VERSION "FM29 IBUS1 + IBUS2, V390.1 20230120, generated by sunnypilot/webhud/tools/gen_ibus.py"

NS_ :

BS_:

BU_: ADAS AMP FloatingButtons GW ICC MFSS PWC_L PWC_R RAC Rotator

BO_ 54 TBOX_0x36: 8 GW
 SG_ TBOX_RemSeekCarCtrlCmd : 3|2@0+ (1,0) [0|3] "" ICC
 SG_ TBOX_RemClsTrCmd : 9|2@0+ (1,0) [0|3] "" ICC
 SG_ TBOX_RemDrvrSeatVentnCmd : 12|3@0+ (1,0) [0|7] "" ICC
 SG_ TBOX_RemDrvrSeatHeatgCmd : 15|3@0+ (1,0) [0|7] "" ICC
 SG_ TBOX_RemSetWelFct : 17|2@0+ (1,0) [0|3] "" ICC
 SG_ TBOX_RemPassSeatVentnCmd : 20|3@0+ (1,0) [0|7] "" ICC
 SG_ TBOX_RemPassSeatHeatgCmd : 23|3@0+ (1,0) [0|7] "" ICC
 SG_ TBOX_ClsAVMFct_ICC : 27|1@0+ (1,0) [0|1] "" ICC
 SG_ TBOX_ClsRemAVMFct_AVAP : 28|1@0+ (1,0) [0|1] "" ICC
 SG_ TBOX_RemSetFolwMeFct_BCM : 31|3@0+ (1,0) [0|7] "" ICC
 SG_ TBOX_RemSetCtrlLockFct_PKC : 33|2@0+ (1,0) [0|3] "" ICC
 SG_ TBOX_RemSetKickSnsrFct : 35|2@0+ (1,0) [0|3] "" ICC
 SG_ TBOX_VideoCtrlReq : 38|3@0+ (1,0) [0|7] "" ICC
 SG_ TBOX_VoiceBlowerLimReq : 39|1@0+ (1,0) [0|1] "" ICC
 SG_ TBOX_RemCtrlCmdFb : 41|2@0+ (1,0) [0|3] "" ICC
 SG_ TBOX_CtrlReMirrReq : 43|2@0+ (1,0) [0|3] "" ICC
 SG_ TBOX_eCallMuteSt : 45|2@0+ (1,0) [0|3] "" ICC
 SG_ TBOX_eCallSt : 58|3@0+ (1,0) [0|7] "" ICC

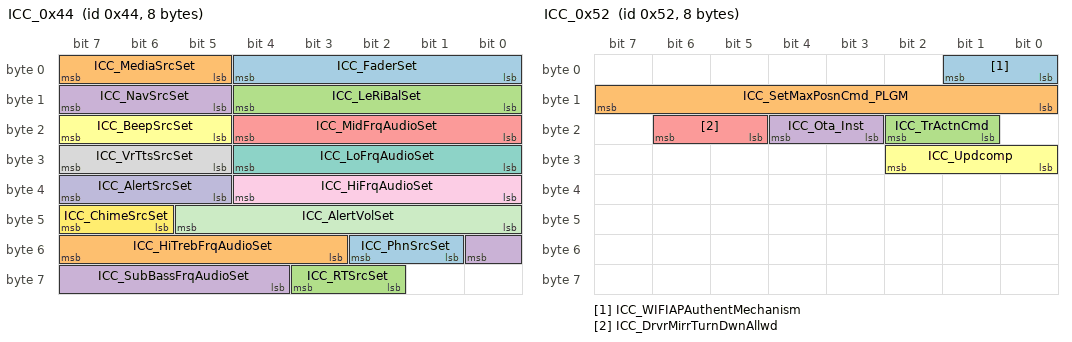
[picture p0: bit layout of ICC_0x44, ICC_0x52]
BO_ 68 ICC_0x44: 8 ICC
 SG_ ICC_FaderSet : 4|5@0+ (1,0) [0|31] "" ICC
 SG_ ICC_MediaSrcSet : 7|3@0+ (1,0) [0|7] "" ICC
 SG_ ICC_LeRiBalSet : 12|5@0+ (1,0) [0|31] "" ICC
 SG_ ICC_NavSrcSet : 15|3@0+ (1,0) [0|7] "" ICC
 SG_ ICC_MidFrqAudioSet : 20|5@0+ (1,0) [0|31] "" ICC
 SG_ ICC_BeepSrcSet : 23|3@0+ (1,0) [0|7] "" ICC
 SG_ ICC_LoFrqAudioSet : 28|5@0+ (1,0) [0|31] "" ICC
 SG_ ICC_VrTtsSrcSet : 31|3@0+ (1,0) [0|7] "" ICC
 SG_ ICC_HiFrqAudioSet : 36|5@0+ (1,0) [0|31] "" ICC
 SG_ ICC_AlertSrcSet : 39|3@0+ (1,0) [0|7] "" ICC
 SG_ ICC_AlertVolSet : 45|6@0+ (1,0) [0|63] "" ICC
 SG_ ICC_ChimeSrcSet : 47|2@0+ (1,0) [0|3] "" ICC
 SG_ ICC_PhnSrcSet : 50|2@0+ (1,0) [0|3] "" ICC
 SG_ ICC_HiTrebFrqAudioSet : 55|5@0+ (1,0) [0|31] "" ICC
 SG_ ICC_RTSrcSet : 59|2@0+ (1,0) [0|3] "" ICC
 SG_ ICC_SubBassFrqAudioSet : 48|5@0+ (1,0) [0|31] "" ICC

BO_ 70 ICC_0x46: 8 ICC
 SG_ ICC_FolwMeHomeTiSet : 2|3@0+ (1,0) [0|7] "" ICC
 SG_ ICC_IntrLampTiSet : 7|3@0+ (1,0) [0|7] "sec" ICC
 SG_ ICC_BluetoothWifiKeyPaySucFlg : 12|3@0+ (1,0) [0|7] "" ICC
 SG_ ICC_BluetoothWifiKeyPay : 15|3@0+ (1,0) [0|7] "" ICC
 SG_ ICC_MaiVolSet : 21|6@0+ (1,0) [0|63] "" ICC
 SG_ ICC_MuteCtrl : 22|1@0+ (1,0) [0|1] "" ICC
 SG_ ICC_ChimeVolSet : 27|4@0+ (1,0) [0|15] "" ICC
 SG_ ICC_IESSModReq : 29|2@0+ (1,0) [0|3] "" ICC
 SG_ ICC_VSCModReq : 31|2@0+ (1,0) [0|3] "" ICC
 SG_ ICC_HFTVolSet : 37|6@0+ (1,0) [0|63] "" ICC
 SG_ ICC_EmgyCallSet : 38|1@0+ (1,0) [0|1] "" ICC
 SG_ ICC_SurrndCtrl : 39|1@0+ (1,0) [0|1] "" ICC
 SG_ ICC_NavVolSet : 45|6@0+ (1,0) [0|63] "" ICC
 SG_ ICC_GetVoltReq : 47|1@0+ (1,0) [0|1] "" ICC
 SG_ ICC_RTVolSet : 53|6@0+ (1,0) [0|63] "" ICC
 SG_ ICC_GetDTCInfo : 54|1@0+ (1,0) [0|1] "" ICC
 SG_ ICC_GetSwVer : 55|1@0+ (1,0) [0|1] "" ICC
 SG_ ICC_VrTtsVolSet : 61|6@0+ (1,0) [0|63] "" ICC
 SG_ ICC_GetHwVer : 62|1@0+ (1,0) [0|1] "" ICC
 SG_ ICC_GetTempReq : 63|1@0+ (1,0) [0|1] "" ICC

BO_ 72 AMP_0x48: 8 AMP
 SG_ AMP_Ch1DTCInfo : 0|1@0+ (1,0) [0|1] "" ICC
 SG_ AMP_Ch2DTCInfo : 1|1@0+ (1,0) [0|1] "" ICC
 SG_ AMP_Ch3DTCInfo : 2|1@0+ (1,0) [0|1] "" ICC
 SG_ AMP_Ch4DTCInfo : 3|1@0+ (1,0) [0|1] "" ICC
 SG_ AMP_Ch5DTCInfo : 4|1@0+ (1,0) [0|1] "" ICC
 SG_ AMP_Ch6DTCInfo : 5|1@0+ (1,0) [0|1] "" ICC
 SG_ AMP_Ch7DTCInfo : 6|1@0+ (1,0) [0|1] "" ICC
 SG_ AMP_Ch8DTCInfo : 7|1@0+ (1,0) [0|1] "" ICC
 SG_ AMP_IntT : 15|8@0+ (1,-50) [-50|205] "Degree Celsius" ICC
 SG_ AMP_IntVolt : 23|8@0+ (0.1,0) [0|25.5] "V" ICC
 SG_ AMP_IntTSts : 25|2@0+ (1,0) [0|3] "" ICC
 SG_ AMP_PhnSrcSts : 27|2@0+ (1,0) [0|3] "" ICC
 SG_ AMP_VrTtsSrcSet : 30|3@0+ (1,0) [0|7] "" ICC
 SG_ AMP_RTVolSet : 37|6@0+ (1,0) [0|63] "" ICC
 SG_ AMP_RTSrcSts : 39|2@0+ (1,0) [0|3] "" ICC
 SG_ AMP_VrTtsVolSet : 45|6@0+ (1,0) [0|63] "" ICC
 SG_ AMP_ChimeSrcSts : 47|2@0+ (1,0) [0|3] "" ICC
 SG_ AMP_AlertVolSetSts : 53|6@0+ (1,0) [0|63] "" ICC
 SG_ AMP_AlertSrcSet : 58|3@0+ (1,0) [0|7] "" ICC

BO_ 73 AMP_0x49: 8 AMP
 SG_ AMP_BalSetSts : 4|5@0+ (1,0) [0|31] "" ICC
 SG_ AMP_VSCModSts : 6|2@0+ (1,0) [0|3] "" ICC
 SG_ AMP_SurrndCtrlSts : 7|1@0+ (1,0) [0|1] "" ICC
 SG_ AMP_FaderSetSts : 12|5@0+ (1,0) [0|31] "" ICC
 SG_ AMP_EmgyCallSetSts : 13|1@0+ (1,0) [0|1] "" ICC
 SG_ AMP_IESSModSts : 15|2@0+ (1,0) [0|3] "" ICC
 SG_ AMP_LoFrqAudioSetSts : 20|5@0+ (1,0) [0|31] "" ICC
 SG_ AMP_BeepSrcSts : 23|3@0+ (1,0) [0|7] "" ICC
 SG_ AMP_MidFrqAudioSetSts : 28|5@0+ (1,0) [0|31] "" ICC
 SG_ AMP_MediaSrcSts : 31|3@0+ (1,0) [0|7] "" ICC
 SG_ AMP_HiFrqAudioSetSts : 36|5@0+ (1,0) [0|31] "" ICC
 SG_ AMP_NavSrcSts : 39|3@0+ (1,0) [0|7] "" ICC
 SG_ AMP_HFTVolSetSts : 45|6@0+ (1,0) [0|63] "" ICC
 SG_ AMP_MuteCtrlSts : 46|1@0+ (1,0) [0|1] "" ICC
 SG_ AMP_NavVolSetSts : 55|6@0+ (1,0) [0|63] "" ICC
 SG_ AMP_MaiVolSetSts : 61|6@0+ (1,0) [0|63] "" ICC
 SG_ AMP_ChimeVolSetSts : 49|4@0+ (1,0) [0|15] "" ICC

BO_ 74 AMP_0x04A: 8 AMP
 SG_ AMP_GetHutInfoSts : 0|1@0+ (1,0) [0|1] "" ICC
 SG_ AMP_HiTrebFrqAudioSetSts : 15|5@0+ (1,0) [0|31] "" ICC
 SG_ AMP_SubBassFrqAudioSetSts : 10|5@0+ (1,0) [0|31] "" ICC

BO_ 76 ICC_0x4C: 8 ICC
 SG_ ICC_BluetoothMACwifi : 7|64@0+ (1,0) [0|1.84467e+19] "" ICC

BO_ 78 ICC_0x4E: 8 ICC
 SG_ ICC_abdEnaReq : 1|2@0+ (1,0) [0|3] "" ICC
 SG_ ICC_RiFrntWinCtrl : 4|3@0+ (1,0) [0|7] "" ICC
 SG_ ICC_LeReWinCtrl : 7|3@0+ (1,0) [0|7] "" ICC
 SG_ ICC_RiReWinCtrl : 10|3@0+ (1,0) [0|7] "" ICC
 SG_ ICC_LeFrntWinCtrl : 13|3@0+ (1,0) [0|7] "" ICC
 SG_ ICC_FrntWshrCtrl : 15|2@0+ (1,0) [0|3] "" ICC
 SG_ ICC_FrntWiprCtrl : 18|3@0+ (1,0) [0|7] "" ICC
 SG_ ICC_ReWiprCtrl : 20|2@0+ (1,0) [0|3] "" ICC
 SG_ ICC_PosnLampCtrl : 23|3@0+ (1,0) [0|7] "" ICC
 SG_ ICC_HiBeamCtrl : 25|2@0+ (1,0) [0|3] "" ICC
 SG_ ICC_LoBeamCtrl : 27|2@0+ (1,0) [0|3] "" ICC
 SG_ ICC_ReWshrCtrl : 29|2@0+ (1,0) [0|3] "" ICC
 SG_ ICC_TrunkLockCtrl : 31|2@0+ (1,0) [0|3] "" ICC
 SG_ ICC_SunroofPercCtrlCmdReq : 39|8@0+ (1,0) [0|127] "%" ICC
 SG_ ICC_FrntFogLampCtrl : 41|2@0+ (1,0) [0|3] "" ICC
 SG_ ICC_ReFogLampCtrl : 43|2@0+ (1,0) [0|3] "" ICC
 SG_ ICC_ReDefrstOpenReq : 45|2@0+ (1,0) [0|3] "" ICC
 SG_ ICC_SunshadeCtrlReq : 47|2@0+ (1,0) [0|3] "" ICC
 SG_ ICC_CentrLockCtrl : 49|2@0+ (1,0) [0|3] "" ICC
 SG_ ICC_MirrCmd : 51|2@0+ (1,0) [0|3] "" ICC
 SG_ ICC_ReMirrAutoFoldSet : 53|2@0+ (1,0) [0|3] "" ICC
 SG_ ICC_SunroofshadePercCtrlCmdReq : 54|1@0+ (1,0) [0|1] "" ICC
 SG_ ICC_RainClsdSunroofSet : 57|2@0+ (1,0) [0|3] "" ICC
 SG_ ICC_ArmedClsdWinSet : 59|2@0+ (1,0) [0|3] "" ICC
 SG_ ICC_OffUnlckSet : 61|2@0+ (1,0) [0|3] "" ICC
 SG_ ICC_DoorUnlockSet : 63|2@0+ (1,0) [0|3] "" ICC

BO_ 82 ICC_0x52: 8 ICC
 SG_ ICC_WIFIAPAuthentMechanism : 1|2@0+ (1,0) [0|3] "" ICC
 SG_ ICC_SetMaxPosnCmd_PLGM : 15|8@0+ (1,0) [0|255] "%" ICC
 SG_ ICC_TrActnCmd : 18|2@0+ (1,0) [0|3] "" ICC
 SG_ ICC_Ota_Inst : 20|2@0+ (1,0) [0|3] "" ICC
 SG_ ICC_DrvrMirrTurnDwnAllwd : 22|2@0+ (1,0) [0|3] "" ICC
 SG_ ICC_Updcomp : 26|3@0+ (1,0) [0|7] "" ICC

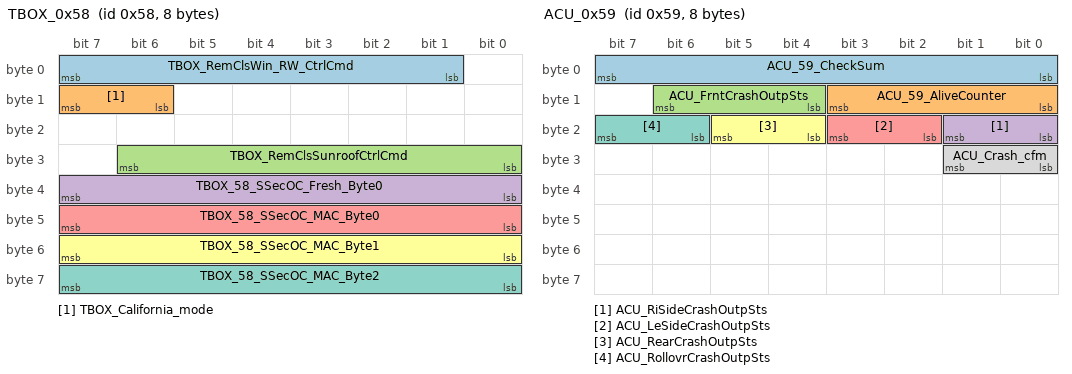
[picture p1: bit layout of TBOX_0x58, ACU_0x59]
BO_ 88 TBOX_0x58: 8 GW
 SG_ TBOX_RemClsWin_RW_CtrlCmd : 7|7@0+ (1,0) [0|100] "%" ICC
 SG_ TBOX_California_mode : 15|2@0+ (1,0) [0|3] "" ICC
 SG_ TBOX_RemClsSunroofCtrlCmd : 30|7@0+ (1,0) [0|100] "%" ICC
 SG_ TBOX_58_SSecOC_Fresh_Byte0 : 39|8@0+ (1,0) [0|255] "" ICC
 SG_ TBOX_58_SSecOC_MAC_Byte0 : 47|8@0+ (1,0) [0|255] "" ICC
 SG_ TBOX_58_SSecOC_MAC_Byte1 : 55|8@0+ (1,0) [0|255] "" ICC
 SG_ TBOX_58_SSecOC_MAC_Byte2 : 63|8@0+ (1,0) [0|255] "" ICC

BO_ 89 ACU_0x59: 8 GW
 SG_ ACU_59_CheckSum : 7|8@0+ (1,0) [0|255] "" ICC
 SG_ ACU_59_AliveCounter : 11|4@0+ (1,0) [0|14] "" ICC
 SG_ ACU_FrntCrashOutpSts : 14|3@0+ (1,0) [0|7] "" ICC
 SG_ ACU_RiSideCrashOutpSts : 17|2@0+ (1,0) [0|3] "" ICC
 SG_ ACU_LeSideCrashOutpSts : 19|2@0+ (1,0) [0|3] "" ICC
 SG_ ACU_RearCrashOutpSts : 21|2@0+ (1,0) [0|3] "" ICC
 SG_ ACU_RollovrCrashOutpSts : 23|2@0+ (1,0) [0|3] "" ICC
 SG_ ACU_Crash_cfm : 25|2@0+ (1,0) [0|3] "" ICC

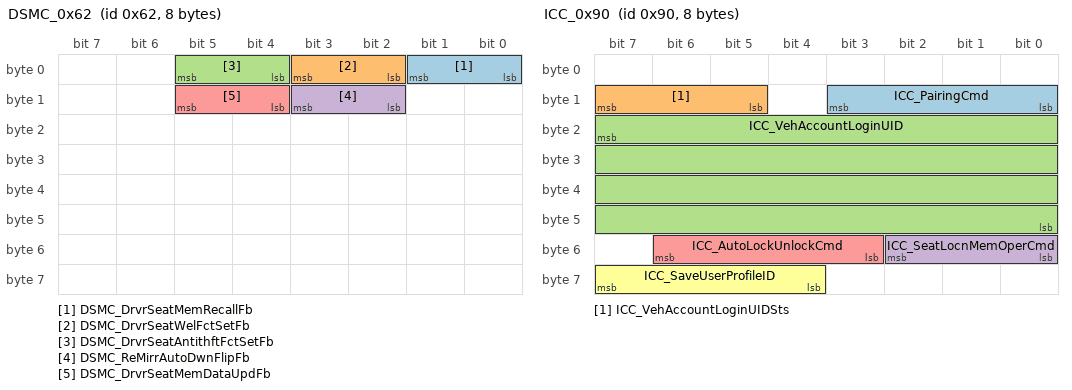
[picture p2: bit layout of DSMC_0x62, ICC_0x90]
BO_ 98 DSMC_0x62: 8 GW
 SG_ DSMC_DrvrSeatMemRecallFb : 1|2@0+ (1,0) [0|3] "" ICC
 SG_ DSMC_DrvrSeatWelFctSetFb : 3|2@0+ (1,0) [0|3] "" ICC
 SG_ DSMC_DrvrSeatAntithftFctSetFb : 5|2@0+ (1,0) [0|3] "" ICC
 SG_ DSMC_ReMirrAutoDwnFlipFb : 11|2@0+ (1,0) [0|3] "" ICC
 SG_ DSMC_DrvrSeatMemDataUpdFb : 13|2@0+ (1,0) [0|3] "" ICC

BO_ 100 PLGM_0x64: 8 GW
 SG_ PLGM_UsrSetTrMaxHeiResFb : 1|2@0+ (1,0) [0|3] "" ICC
 SG_ PLGM_RemTrCtrlFbInfo : 3|2@0+ (1,0) [0|3] "" ICC
 SG_ PLGM_LtchMotRtrnSig : 5|2@0+ (1,0) [0|3] "" ICC

BO_ 144 ICC_0x90: 8 ICC
 SG_ ICC_PairingCmd : 11|4@0+ (1,0) [0|15] "" ICC
 SG_ ICC_VehAccountLoginUIDSts : 15|3@0+ (1,0) [0|7] "" ICC
 SG_ ICC_VehAccountLoginUID : 23|32@0+ (1,0) [0|4.29497e+09] "" ICC
 SG_ ICC_SeatLocnMemOperCmd : 50|3@0+ (1,0) [0|7] "" ICC
 SG_ ICC_AutoLockUnlockCmd : 54|4@0+ (1,0) [0|15] "" ICC
 SG_ ICC_SaveUserProfileID : 63|4@0+ (1,0) [0|15] "" ICC

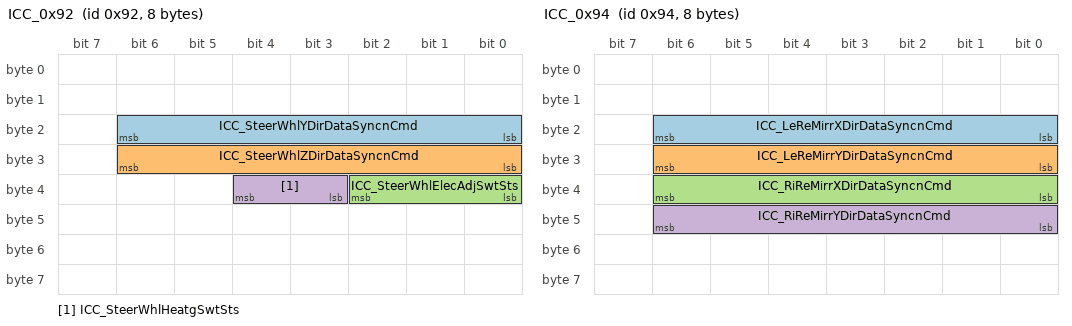
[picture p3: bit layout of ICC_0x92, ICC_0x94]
BO_ 146 ICC_0x92: 8 ICC
 SG_ ICC_SteerWhlYDirDataSyncnCmd : 22|7@0+ (1,0) [0|100] "" ICC
 SG_ ICC_SteerWhlZDirDataSyncnCmd : 30|7@0+ (1,0) [0|100] "" ICC
 SG_ ICC_SteerWhlElecAdjSwtSts : 34|3@0+ (1,0) [0|7] "" ICC
 SG_ ICC_SteerWhlHeatgSwtSts : 36|2@0+ (1,0) [0|3] "" ICC

BO_ 148 ICC_0x94: 8 ICC
 SG_ ICC_LeReMirrXDirDataSyncnCmd : 22|7@0+ (1,0) [0|100] "" ICC
 SG_ ICC_LeReMirrYDirDataSyncnCmd : 30|7@0+ (1,0) [0|100] "" ICC
 SG_ ICC_RiReMirrXDirDataSyncnCmd : 38|7@0+ (1,0) [0|100] "" ICC
 SG_ ICC_RiReMirrYDirDataSyncnCmd : 46|7@0+ (1,0) [0|100] "" ICC

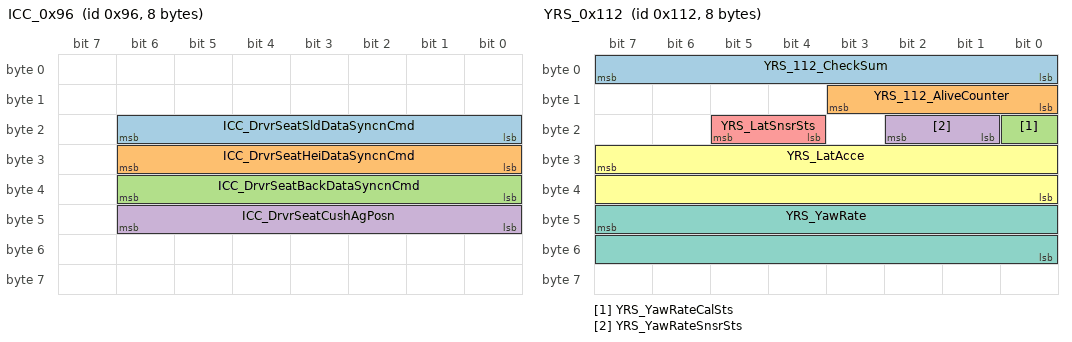
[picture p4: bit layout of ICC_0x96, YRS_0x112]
BO_ 150 ICC_0x96: 8 ICC
 SG_ ICC_DrvrSeatSldDataSyncnCmd : 22|7@0+ (1,0) [0|100] "" ICC
 SG_ ICC_DrvrSeatHeiDataSyncnCmd : 30|7@0+ (1,0) [0|100] "" ICC
 SG_ ICC_DrvrSeatBackDataSyncnCmd : 38|7@0+ (1,0) [0|100] "" ICC
 SG_ ICC_DrvrSeatCushAgPosn : 46|7@0+ (1,0) [0|100] "%" ICC

BO_ 237 BMS_HVBatt_Status_Overall: 8 GW
 SG_ BMS_OverallStatus_CheckSum : 7|8@0+ (1,0) [0|255] "" ICC
 SG_ BMS_OverallStatus_AliveCounter : 11|4@0+ (1,0) [0|14] "" ICC
 SG_ BMS_OperationStates : 19|4@0+ (1,0) [0|15] "" ICC
 SG_ BMS_BallancingStatus : 23|4@0+ (1,0) [0|15] "" ICC
 SG_ BMS_ErrorCategory_CAT0 : 24|1@0+ (1,0) [0|1] "" ICC
 SG_ BMS_ErrorCategory_CAT1 : 25|1@0+ (1,0) [0|1] "" ICC
 SG_ BMS_ErrorCategory_CAT2 : 26|1@0+ (1,0) [0|1] "" ICC
 SG_ BMS_ErrorCategory_CAT3 : 27|1@0+ (1,0) [0|1] "" ICC
 SG_ BMS_ErrorCategory_CAT4 : 28|1@0+ (1,0) [0|1] "" ICC
 SG_ BMS_ErrorCategory_CAT5 : 29|1@0+ (1,0) [0|1] "" ICC
 SG_ BMS_ErrorCategory_CAT6 : 30|1@0+ (1,0) [0|1] "" ICC
 SG_ BMS_ErrorCategory_CAT7 : 31|1@0+ (1,0) [0|1] "" ICC
 SG_ BMS_ErrorCategory_CAT8 : 32|1@0+ (1,0) [0|1] "" ICC
 SG_ BMS_HardwareStatus_OK : 33|1@0+ (1,0) [0|1] "" ICC
 SG_ BMS_ErrorCategory_Mem_Empty : 34|1@0+ (1,0) [0|1] "" ICC
 SG_ BMS_ConfigurationStatus_OK : 35|1@0+ (1,0) [0|1] "" ICC
 SG_ BMS_MeasurementModules_OK : 36|1@0+ (1,0) [0|1] "" ICC
 SG_ BMS_BatteryGeneralStatus_OK : 37|1@0+ (1,0) [0|1] "" ICC
 SG_ BMS_SDIL_Sts : 38|1@0+ (1,0) [0|1] "" ICC
 SG_ BMS_CL30C_Sts : 39|1@0+ (1,0) [0|1] "" ICC
 SG_ BMS_CL15_Sts : 40|1@0+ (1,0) [0|1] "" ICC
 SG_ BMS_HVIL_OK : 41|1@0+ (1,0) [0|1] "" ICC
 SG_ BMS_HV_ContactorsStatus_OK : 42|1@0+ (1,0) [0|1] "" ICC
 SG_ BMS_SW_Status_OK : 43|1@0+ (1,0) [0|1] "" ICC
 SG_ BMS_CurrentSensor_OK : 44|1@0+ (1,0) [0|1] "" ICC
 SG_ BMS_IsolatoinStatus_OK : 45|1@0+ (1,0) [0|1] "" ICC
 SG_ BMS_StateMAchine_Status : 55|8@0+ (1,0) [0|255] "" ICC
 SG_ BMS_BDU_Status : 63|8@0+ (1,0) [0|255] "" ICC

BO_ 274 YRS_0x112: 8 GW
 SG_ YRS_112_CheckSum : 7|8@0+ (1,0) [0|255] "" ICC
 SG_ YRS_112_AliveCounter : 11|4@0+ (1,0) [0|14] "" ICC
 SG_ YRS_YawRateCalSts : 16|1@0+ (1,0) [0|1] "" ICC
 SG_ YRS_YawRateSnsrSts : 18|2@0+ (1,0) [0|3] "" ICC
 SG_ YRS_LatSnsrSts : 21|2@0+ (1,0) [0|3] "" ICC
 SG_ YRS_LatAcce : 31|16@0+ (0.001,-2) [-2|2] "g" ICC
 SG_ YRS_YawRate : 47|16@0+ (0.01,-180) [-180|180] "deg/s" ICC

BO_ 275 YRS_0x113: 8 GW
 SG_ YRS_113_CheckSum : 7|8@0+ (1,0) [0|255] "" ICC
 SG_ YRS_113_AliveCounter : 11|4@0+ (1,0) [0|14] "" ICC
 SG_ YRS_LgtSnsrSts : 17|2@0+ (1,0) [0|3] "" ICC
 SG_ YRS_LgtAcce : 31|16@0+ (0.001,-2) [-2|2] "g" ICC

BO_ 276 ESP_0x114: 8 GW
 SG_ ESP_114_CheckSum : 7|8@0+ (1,0) [0|255] "" ICC
 SG_ ESP_114_AliveCounter : 11|4@0+ (1,0) [0|14] "" ICC
 SG_ ESP_OTARdy_Fb : 13|2@0+ (1,0) [0|3] "" ICC
 SG_ ESP_FltIndcn_DTC : 15|1@0+ (1,0) [0|1] "" ICC
 SG_ ESP_ActvSig_VDC : 16|1@0+ (1,0) [0|1] "" ICC
 SG_ ESP_ActvSig_TCS : 17|1@0+ (1,0) [0|1] "" ICC
 SG_ ESP_ActvSig_EBD : 19|1@0+ (1,0) [0|1] "" ICC
 SG_ ESP_ActvSig_DTC : 20|1@0+ (1,0) [0|1] "" ICC
 SG_ ESP_WarningOn : 22|2@0+ (1,0) [0|3] "" ICC
 SG_ ESP_Actvndcn_CDD : 24|1@0+ (1,0) [0|1] "" ICC
 SG_ ESP_FltIndcn_CDD : 25|1@0+ (1,0) [0|1] "" ICC
 SG_ ESP_ActvIndcn_ABA : 26|1@0+ (1,0) [0|1] "" ICC
 SG_ ESP_FltIndcn_ABA : 27|1@0+ (1,0) [0|1] "" ICC
 SG_ ESP_ActvIndcn_ABP : 28|1@0+ (1,0) [0|1] "" ICC
 SG_ ESP_FltIndcn_ABP : 29|1@0+ (1,0) [0|1] "" ICC
 SG_ ESP_ActvIndcn_AEB : 30|1@0+ (1,0) [0|1] "" ICC
 SG_ ESP_FltIndcn_AEB : 31|1@0+ (1,0) [0|1] "" ICC
 SG_ ESP_ActvIndcn_AWB : 32|1@0+ (1,0) [0|1] "" ICC
 SG_ ESP_FltIndcn_AWB : 33|1@0+ (1,0) [0|1] "" ICC
 SG_ ESP_VehStandstillIndcn : 35|2@0+ (1,0) [0|3] "" ICC
 SG_ ESP_BrkOverTIndcn : 36|1@0+ (1,0) [0|1] "" ICC
 SG_ ESP_FltIndcn_VDC : 37|1@0+ (1,0) [0|1] "" ICC
 SG_ ESP_ActvIndcn_CDD_AP : 42|1@0+ (1,0) [0|1] "" ICC
 SG_ ESP_FltIndcn_CDD_AP : 43|1@0+ (1,0) [0|1] "" ICC

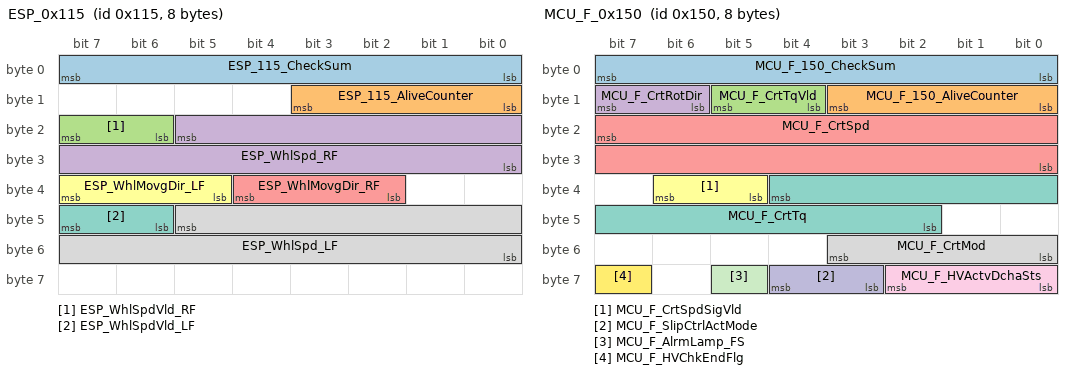
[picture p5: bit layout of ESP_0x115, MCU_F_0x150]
BO_ 277 ESP_0x115: 8 GW
 SG_ ESP_115_CheckSum : 7|8@0+ (1,0) [0|255] "" ICC
 SG_ ESP_115_AliveCounter : 11|4@0+ (1,0) [0|14] "" ICC
 SG_ ESP_WhlSpdVld_RF : 23|2@0+ (1,0) [0|3] "" ICC
 SG_ ESP_WhlSpd_RF : 21|14@0+ (0.0625,0) [0|300] "km/h" ICC
 SG_ ESP_WhlMovgDir_RF : 36|3@0+ (1,0) [0|7] "" ICC
 SG_ ESP_WhlMovgDir_LF : 39|3@0+ (1,0) [0|7] "" ICC
 SG_ ESP_WhlSpdVld_LF : 47|2@0+ (1,0) [0|3] "" ICC
 SG_ ESP_WhlSpd_LF : 45|14@0+ (0.0625,0) [0|300] "km/h" ICC

BO_ 336 MCU_F_0x150: 8 GW
 SG_ MCU_F_150_CheckSum : 7|8@0+ (1,0) [0|255] "" ICC
 SG_ MCU_F_150_AliveCounter : 11|4@0+ (1,0) [0|14] "" ICC
 SG_ MCU_F_CrtTqVld : 13|2@0+ (1,0) [0|3] "" ICC
 SG_ MCU_F_CrtRotDir : 15|2@0+ (1,0) [0|3] "" ICC
 SG_ MCU_F_CrtSpd : 23|16@0+ (1,-32768) [-32768|32767] "rpm" ICC
 SG_ MCU_F_CrtSpdSigVld : 38|2@0+ (1,0) [0|3] "" ICC
 SG_ MCU_F_CrtTq : 36|11@0+ (0.5,-511) [-511|512] "Nm" ICC
 SG_ MCU_F_CrtMod : 51|4@0+ (1,0) [0|15] "" ICC
 SG_ MCU_F_HVActvDchaSts : 58|3@0+ (1,0) [0|7] "" ICC
 SG_ MCU_F_SlipCtrlActMode : 60|2@0+ (1,0) [0|3] "" ICC
 SG_ MCU_F_AlrmLamp_FS : 61|1@0+ (1,0) [0|1] "" ICC
 SG_ MCU_F_HVChkEndFlg : 63|1@0+ (1,0) [0|1] "" ICC

BO_ 337 MCU_R_0x151: 8 GW
 SG_ MCU_R_151_CheckSum : 7|8@0+ (1,0) [0|255] "" ICC
 SG_ MCU_R_151_AliveCounter : 11|4@0+ (1,0) [0|14] "" ICC
 SG_ MCU_R_CrtTqVld : 13|2@0+ (1,0) [0|3] "" ICC
 SG_ MCU_R_CrtRotDir : 15|2@0+ (1,0) [0|3] "" ICC
 SG_ MCU_R_CrtSpd : 23|16@0+ (1,-32768) [-32768|32767] "rpm" ICC
 SG_ MCU_R_CrtSpdSigVld : 38|2@0+ (1,0) [0|3] "" ICC
 SG_ MCU_R_CrtTq : 36|11@0+ (0.5,-511) [-511|512] "Nm" ICC
 SG_ MCU_R_CrtMod : 51|4@0+ (1,0) [0|15] "" ICC
 SG_ MCU_R_Decoup_State : 55|4@0+ (1,0) [0|15] "" ICC
 SG_ MCU_R_HVActvDchaSts : 58|3@0+ (1,0) [0|7] "" ICC
 SG_ MCU_R_SlipCtrlActMode : 60|2@0+ (1,0) [0|3] "" ICC
 SG_ MCU_R_AlrmLamp_FS : 61|1@0+ (1,0) [0|1] "" ICC
 SG_ MCU_R_HVChkEndFlg : 63|1@0+ (1,0) [0|1] "" ICC
 SG_ ACU_159_CheckSum : 7|8@0+ (1,0) [0|255] "" ICC
 SG_ ACU_159_AliveCounter : 11|4@0+ (1,0) [0|14] "" ICC
 SG_ ACU_Pass_OCS_St : 13|2@0+ (1,0) [0|3] "" ICC
 SG_ ACU_AirBagSysAlrmLampSts : 17|2@0+ (1,0) [0|3] "" ICC
 SG_ ACU_Pass_Airbag_LED : 20|3@0+ (1,0) [0|7] "" ICC
 SG_ ACU_Drvr_Occpt_St : 22|2@0+ (1,0) [0|3] "" ICC
 SG_ ACU_BucSwtStFrntDrvr : 25|2@0+ (1,0) [0|3] "" ICC
 SG_ ACU_BucSwtStFrntPass : 27|2@0+ (1,0) [0|3] "" ICC
 SG_ ACU_SeatTrkPosnSwtFrntDrvr : 29|2@0+ (1,0) [0|3] "" ICC
 SG_ ACU_SeatTrkPosnSwtFrntPass : 31|2@0+ (1,0) [0|3] "" ICC

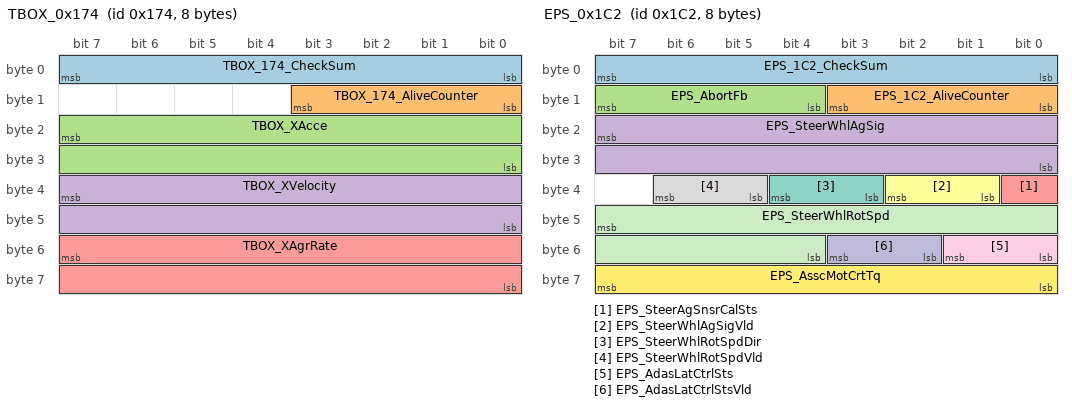
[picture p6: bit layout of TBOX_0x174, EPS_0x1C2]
BO_ 372 TBOX_0x174: 8 GW
 SG_ TBOX_174_CheckSum : 7|8@0+ (1,0) [0|255] "" ICC
 SG_ TBOX_174_AliveCounter : 11|4@0+ (1,0) [0|14] "" ICC
 SG_ TBOX_XAcce : 23|16@0- (0.01,0) [-327|327] "m/s2" ICC
 SG_ TBOX_XVelocity : 39|16@0- (1,0) [-32768|32767] "cm/s" ICC
 SG_ TBOX_XAgrRate : 55|16@0- (0.01,0) [-327|327] "deg/s" ICC

BO_ 373 TBOX_0x175: 8 GW
 SG_ TBOX_175_CheckSum : 7|8@0+ (1,0) [0|255] "" ICC
 SG_ TBOX_175_AliveCounter : 11|4@0+ (1,0) [0|14] "" ICC
 SG_ TBOX_YAcce : 23|16@0- (0.01,0) [-327|327] "m/s2" ICC
 SG_ TBOX_YVelocity : 39|16@0- (1,0) [-32768|32767] "cm/s" ICC
 SG_ TBOX_YAgrRate : 55|16@0- (0.01,0) [-327|327] "deg/s" ICC

BO_ 374 TBOX_0x176: 8 GW
 SG_ TBOX_176_CheckSum : 7|8@0+ (1,0) [0|255] "" ICC
 SG_ TBOX_176_AliveCounter : 11|4@0+ (1,0) [0|14] "" ICC
 SG_ TBOX_ZAcce : 23|16@0- (0.01,0) [-327|327] "m/s2" ICC
 SG_ TBOX_ZVelocity : 39|16@0- (1,0) [-32768|32767] "cm/s" ICC
 SG_ TBOX_ZAgrRate : 55|16@0- (0.01,0) [-327|327] "deg/s" ICC

BO_ 377 TBOX_0x179: 8 GW
 SG_ TBOX_179_CheckSum : 7|8@0+ (1,0) [0|255] "" ICC
 SG_ TBOX_179_AliveCounter : 11|4@0+ (1,0) [0|14] "" ICC
 SG_ TBOX_Heading : 23|16@0+ (0.01,0) [0|359.9] "deg" ICC
 SG_ TBOX_HeadingStdDev : 39|16@0+ (0.01,0) [0|179.9] "deg" ICC

BO_ 440 ESP_0x1B8: 8 GW
 SG_ ESP_1B8_CheckSum : 7|8@0+ (1,0) [0|255] "" ICC
 SG_ ESP_1B8_AliveCounter : 11|4@0+ (1,0) [0|14] "" ICC
 SG_ ESP_ModFbSig : 14|3@0+ (1,0) [0|7] "" ICC
 SG_ ESP_ModSwtAllw : 15|1@0+ (1,0) [0|1] "" ICC
 SG_ ESP_ActvVehHldFlg : 16|1@0+ (1,0) [0|1] "" ICC
 SG_ ESP_VehSecuCdn : 19|3@0+ (1,0) [0|7] "" ICC
 SG_ ESP_BrkFStsFlg : 20|1@0+ (1,0) [0|1] "" ICC
 SG_ ESP_CddApOpsDirMovmt : 24|1@0+ (1,0) [0|1] "" ICC
 SG_ ESP_VehStopSts : 32|1@0+ (1,0) [0|1] "" ICC
 SG_ ESP_VehStandstillSts : 33|1@0+ (1,0) [0|1] "" ICC
 SG_ ESP_EPB_BenchMode : 35|2@0+ (1,0) [0|3] "" ICC
 SG_ ESP_RoadSlopVld : 37|2@0+ (1,0) [0|3] "" ICC
 SG_ ESP_AEBRdy : 41|2@0+ (1,0) [0|3] "" ICC
 SG_ ESPACCRdy : 43|2@0+ (1,0) [0|3] "" ICC
 SG_ ESP_ParkRdy : 45|2@0+ (1,0) [0|3] "" ICC
 SG_ ESP_ReAEBRdy : 47|2@0+ (1,0) [0|3] "" ICC
 SG_ ESP_SpclTerrainModFltIndcn : 51|1@0+ (1,0) [0|1] "" ICC
 SG_ ESP_DrvOffStRdy : 52|1@0+ (1,0) [0|1] "" ICC
 SG_ ESP_TarLSMSts : 55|1@0+ (1,0) [0|1] "" ICC
 SG_ ESP_RoadSlop : 50|11@0+ (0.01,-10) [-10|10] "m/s2" ICC

BO_ 450 EPS_0x1C2: 8 GW
 SG_ EPS_1C2_CheckSum : 7|8@0+ (1,0) [0|255] "" ICC
 SG_ EPS_1C2_AliveCounter : 11|4@0+ (1,0) [0|14] "" ICC
 SG_ EPS_AbortFb : 15|4@0+ (1,0) [0|15] "" ICC
 SG_ EPS_SteerWhlAgSig : 23|16@0+ (0.0625,-780) [-780|780] "deg" ICC
 SG_ EPS_SteerAgSnsrCalSts : 32|1@0+ (1,0) [0|1] "" ICC
 SG_ EPS_SteerWhlAgSigVld : 34|2@0+ (1,0) [0|3] "" ICC
 SG_ EPS_SteerWhlRotSpdDir : 36|2@0+ (1,0) [0|3] "" ICC
 SG_ EPS_SteerWhlRotSpdVld : 38|2@0+ (1,0) [0|3] "" ICC
 SG_ EPS_AdasLatCtrlSts : 49|2@0+ (1,0) [0|3] "" ICC
 SG_ EPS_AdasLatCtrlStsVld : 51|2@0+ (1,0) [0|3] "" ICC
 SG_ EPS_SteerWhlRotSpd : 47|12@0+ (0.5,-1016) [-1016|1016] "deg/s" ICC
 SG_ EPS_AsscMotCrtTq : 63|8@0+ (0.1,0) [0|10] "Nm" ICC

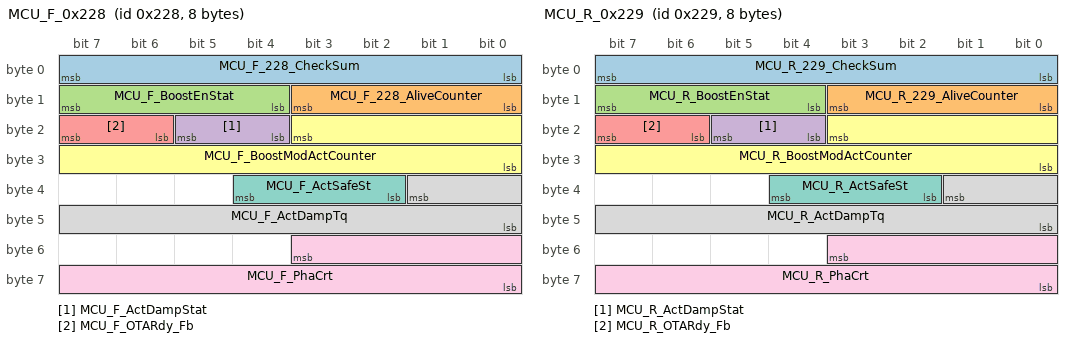
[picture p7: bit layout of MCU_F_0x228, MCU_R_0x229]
BO_ 552 MCU_F_0x228: 8 GW
 SG_ MCU_F_228_CheckSum : 7|8@0+ (1,0) [0|255] "" ICC
 SG_ MCU_F_228_AliveCounter : 11|4@0+ (1,0) [0|14] "" ICC
 SG_ MCU_F_BoostEnStat : 15|4@0+ (1,0) [0|15] "" ICC
 SG_ MCU_F_ActDampStat : 21|2@0+ (1,0) [0|3] "" ICC
 SG_ MCU_F_OTARdy_Fb : 23|2@0+ (1,0) [0|3] "" ICC
 SG_ MCU_F_BoostModActCounter : 19|12@0+ (1,0) [0|2000] "" ICC
 SG_ MCU_F_ActSafeSt : 36|3@0+ (1,0) [0|7] "" ICC
 SG_ MCU_F_ActDampTq : 33|10@0+ (1,-511) [-511|512] "Nm" ICC
 SG_ MCU_F_PhaCrt : 51|12@0+ (0.5,-1023.5) [-1023.5|1024] "A" ICC

BO_ 553 MCU_R_0x229: 8 GW
 SG_ MCU_R_229_CheckSum : 7|8@0+ (1,0) [0|255] "" ICC
 SG_ MCU_R_229_AliveCounter : 11|4@0+ (1,0) [0|14] "" ICC
 SG_ MCU_R_BoostEnStat : 15|4@0+ (1,0) [0|15] "" ICC
 SG_ MCU_R_ActDampStat : 21|2@0+ (1,0) [0|3] "" ICC
 SG_ MCU_R_OTARdy_Fb : 23|2@0+ (1,0) [0|3] "" ICC
 SG_ MCU_R_BoostModActCounter : 19|12@0+ (1,0) [0|2000] "" ICC
 SG_ MCU_R_ActSafeSt : 36|3@0+ (1,0) [0|7] "" ICC
 SG_ MCU_R_ActDampTq : 33|10@0+ (1,-511) [-511|512] "Nm" ICC
 SG_ MCU_R_PhaCrt : 51|12@0+ (0.5,-1023.5) [-1023.5|1024] "A" ICC

BO_ 564 VCU_0x234: 8 GW
 SG_ VCU_214_234_CheckSum : 7|8@0+ (1,0) [0|255] "" ICC
 SG_ VCU_214_234_AliveCounter : 11|4@0+ (1,0) [0|14] "" ICC
 SG_ VCU_RdyLamp : 12|1@0+ (1,0) [0|1] "" ICC
 SG_ VCU_BrkLampCtrlSts : 14|1@0+ (1,0) [0|1] "" ICC
 SG_ VCU_RemWakeUpEndFlg : 15|1@0+ (1,0) [0|1] "" ICC
 SG_ VCU_StgyGearSig : 19|4@0+ (1,0) [0|15] "" ICC
 SG_ VCU_ShiftMisoper : 21|1@0+ (1,0) [0|1] "" ICC
 SG_ VCU_GearSigVld : 23|2@0+ (1,0) [0|3] "" ICC
 SG_ VCU_GearSig : 27|4@0+ (1,0) [0|15] "" ICC
 SG_ VCU_ACCRdy : 28|1@0+ (1,0) [0|1] "" ICC
 SG_ VCU_ParkRdy : 29|1@0+ (1,0) [0|1] "" ICC
 SG_ VCU_APSPercVld : 31|2@0+ (1,0) [0|3] "" ICC
 SG_ VCU_VehSt : 39|16@0+ (1,0) [0|65535] "" ICC
 SG_ VCU_APSPerc : 55|8@0+ (0.4,0) [0|100] "%" ICC
 SG_ VCU_BrkSig : 56|1@0+ (1,0) [0|1] "" ICC
 SG_ VCU_BrkSigVld : 58|2@0+ (1,0) [0|3] "" ICC
 SG_ VCU_DrvModSigFb : 61|3@0+ (1,0) [0|7] "" ICC
 SG_ VCU_DrvModShiftMisoper : 62|1@0+ (1,0) [0|1] "" ICC
 SG_ VCU_SpclTerrainModEnaSig : 63|1@0+ (1,0) [0|1] "" ICC

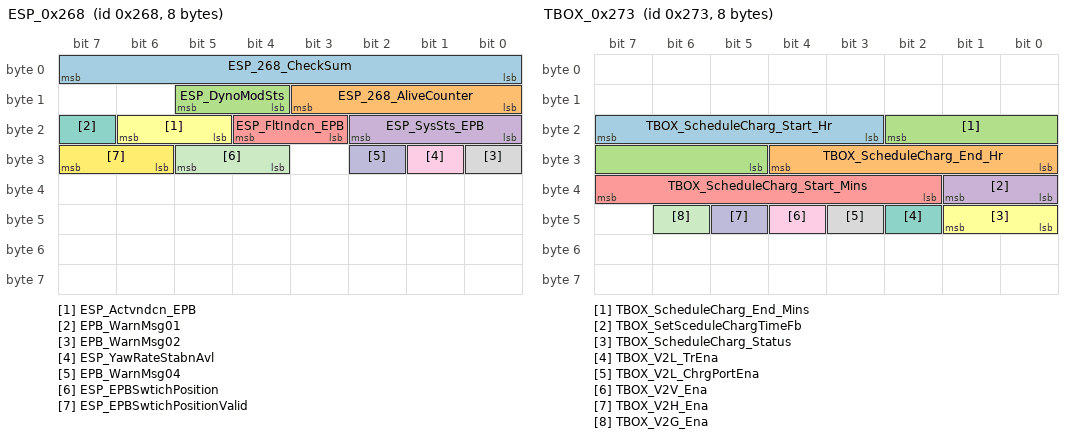
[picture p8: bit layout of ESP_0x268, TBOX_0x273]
BO_ 616 ESP_0x268: 8 GW
 SG_ ESP_268_CheckSum : 7|8@0+ (1,0) [0|255] "" ICC
 SG_ ESP_268_AliveCounter : 11|4@0+ (1,0) [0|14] "" ICC
 SG_ ESP_DynoModSts : 13|2@0+ (1,0) [0|3] "" ICC
 SG_ ESP_SysSts_EPB : 18|3@0+ (1,0) [0|7] "" ICC
 SG_ ESP_FltIndcn_EPB : 20|2@0+ (1,0) [0|3] "" ICC
 SG_ ESP_Actvndcn_EPB : 22|2@0+ (1,0) [0|3] "" ICC
 SG_ EPB_WarnMsg01 : 23|1@0+ (1,0) [0|1] "" ICC
 SG_ EPB_WarnMsg02 : 24|1@0+ (1,0) [0|1] "" ICC
 SG_ ESP_YawRateStabnAvl : 25|1@0+ (1,0) [0|1] "" ICC
 SG_ EPB_WarnMsg04 : 26|1@0+ (1,0) [0|1] "" ICC
 SG_ ESP_EPBSwtichPosition : 29|2@0+ (1,0) [0|3] "" ICC
 SG_ ESP_EPBSwtichPositionValid : 31|2@0+ (1,0) [0|3] "" ICC

BO_ 627 TBOX_0x273: 8 GW
 SG_ TBOX_ScheduleCharg_Start_Hr : 23|5@0+ (1,0) [0|23] "" ICC
 SG_ TBOX_ScheduleCharg_End_Hr : 28|5@0+ (1,0) [0|23] "" ICC
 SG_ TBOX_ScheduleCharg_End_Mins : 18|6@0+ (1,0) [0|59] "" ICC
 SG_ TBOX_SetSceduleChargTimeFb : 33|2@0+ (1,0) [0|3] "" ICC
 SG_ TBOX_ScheduleCharg_Start_Mins : 39|6@0+ (1,0) [0|59] "" ICC
 SG_ TBOX_ScheduleCharg_Status : 41|2@0+ (1,0) [0|3] "" ICC
 SG_ TBOX_V2L_TrEna : 42|1@0+ (1,0) [0|1] "" ICC
 SG_ TBOX_V2L_ChrgPortEna : 43|1@0+ (1,0) [0|1] "" ICC
 SG_ TBOX_V2V_Ena : 44|1@0+ (1,0) [0|1] "" ICC
 SG_ TBOX_V2H_Ena : 45|1@0+ (1,0) [0|1] "" ICC
 SG_ TBOX_V2G_Ena : 46|1@0+ (1,0) [0|1] "" ICC

BO_ 649 VCU_0x289: 8 GW
 SG_ VCU_SetSpeedLimitSts : 7|8@0+ (1,0) [0|255] "" ICC

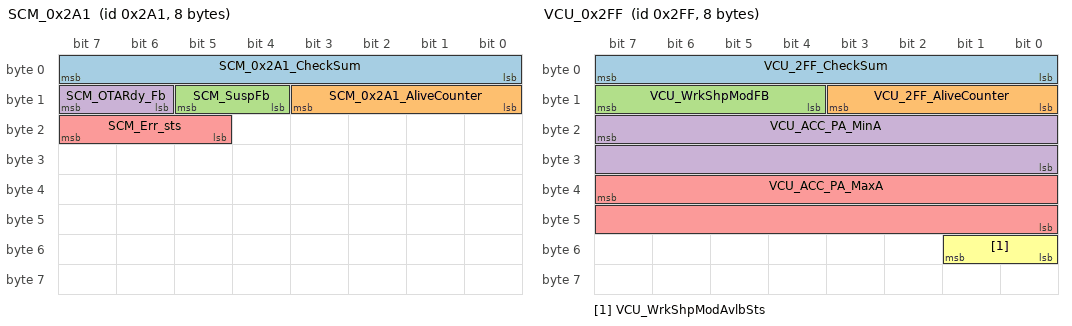
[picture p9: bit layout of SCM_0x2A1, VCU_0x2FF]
BO_ 673 SCM_0x2A1: 8 GW
 SG_ SCM_0x2A1_CheckSum : 7|8@0+ (1,0) [0|255] "" ICC
 SG_ SCM_0x2A1_AliveCounter : 11|4@0+ (1,0) [0|14] "" ICC
 SG_ SCM_SuspFb : 13|2@0+ (1,0) [0|3] "" ICC
 SG_ SCM_OTARdy_Fb : 15|2@0+ (1,0) [0|3] "" ICC
 SG_ SCM_Err_sts : 23|3@0+ (1,0) [0|7] "" ICC

BO_ 684 VCU_IBS_BZE1: 8 GW
 SG_ IBS_StateOfCharge : 7|8@0+ (0.5,0) [0|100] "%" ICC
 SG_ IBS_StateOfHealth : 15|8@0+ (0.5,0) [0|100] "%" ICC
 SG_ IBS_EstVoltaDrop : 23|8@0+ (0.05,0) [0|12.7] "V" ICC
 SG_ IBS_OptChargeVolt : 31|8@0+ (0.05,5) [5|17.75] "V" ICC
 SG_ IBS_AvgRi : 39|16@0+ (0.01,0) [0|200] "mOhm" ICC

BO_ 743 ECC_0x2E7: 8 GW
 SG_ ECC_ICCSysSwtCmdFb : 1|2@0+ (1,0) [0|3] "" ICC
 SG_ ECC_CooltLvlWarn : 17|2@0+ (1,0) [0|3] "" ICC

BO_ 756 BMS_0x2F4: 8 GW
 SG_ BMS_Bat_measure_Coulomb_Ctr : 7|16@0- (10,0) [-327680|327670] "As" ICC
 SG_ BMS_Bat_measure_Energy : 23|16@0- (10,0) [-327680|327670] "Wh" ICC
 SG_ BMS_Bat_measure_Power : 39|16@0- (0.1,0) [-3276.8|3276.7] "KW" ICC
 SG_ BMS_Bat_Bus_measure_Temperature : 55|8@0+ (1,-55) [-55|200] "Degree Celsius" ICC

BO_ 757 BMS_SOC: 8 GW
 SG_ BMS_Bat_SoC_usable : 7|8@0+ (1,0) [0|100] "%" ICC
 SG_ BMS_Bat_Actual_Pack_Capacity : 31|16@0+ (0.01,0) [0|655.35] "kWh" ICC
 SG_ BMS_Bat_SOH : 47|8@0+ (1,0) [0|255] "%" ICC
 SG_ BMS_Bat_SOC_Real : 55|8@0+ (1,0) [0|100] "%" ICC

BO_ 767 VCU_0x2FF: 8 GW
 SG_ VCU_2FF_CheckSum : 7|8@0+ (1,0) [0|255] "" ICC
 SG_ VCU_2FF_AliveCounter : 11|4@0+ (1,0) [0|14] "" ICC
 SG_ VCU_WrkShpModFB : 15|4@0+ (1,0) [0|15] "" ICC
 SG_ VCU_ACC_PA_MinA : 23|16@0+ (0.0004882,-16) [-16|0] "m/sec2" ICC
 SG_ VCU_ACC_PA_MaxA : 39|16@0+ (0.0004882,0) [0|16] "m/sec2" ICC
 SG_ VCU_WrkShpModAvlbSts : 49|2@0+ (1,0) [0|3] "" ICC

BO_ 783 ICC_0x30F: 8 ICC
 SG_ ICC_QuickBootMode : 0|1@0+ (1,0) [0|1] "" ICC

BO_ 792 ESP_0x318: 8 GW
 SG_ ESP_318_CheckSum : 7|8@0+ (1,0) [0|255] "" ICC
 SG_ ESP_318_AliveCounter : 11|4@0+ (1,0) [0|14] "" ICC
 SG_ ESP_BrkPedlStsVld : 13|2@0+ (1,0) [0|3] "" ICC
 SG_ ESP_BrkPedlSts : 14|1@0+ (1,0) [0|1] "" ICC
 SG_ ESP_VehSpdVld : 17|2@0+ (1,0) [0|3] "" ICC
 SG_ ESP_SysActv : 20|1@0+ (1,0) [0|1] "" ICC
 SG_ ESP_LampSwtOffIndcn : 21|1@0+ (1,0) [0|1] "" ICC
 SG_ ESP_FltIndcn_EBD : 22|1@0+ (1,0) [0|1] "" ICC
 SG_ ESP_FltIndcn_ABS : 23|1@0+ (1,0) [0|1] "" ICC
 SG_ ESP_MilgRollgCntr_ODO : 31|16@0+ (1,0) [0|65535] "pulses" ICC
 SG_ ESP_VehSpd : 47|16@0+ (0.1,0) [0|300] "km/h" ICC
 SG_ ESP_IninModSigIndcn : 56|1@0+ (1,0) [0|1] "" ICC
 SG_ ESP_FltIndcn_TCS : 57|1@0+ (1,0) [0|1] "" ICC
 SG_ ESP_CtrlSts_HDC : 59|2@0+ (1,0) [0|3] "" ICC
 SG_ ESP_AvlIndcn_HDC : 60|1@0+ (1,0) [0|1] "" ICC
 SG_ ESP_NoBrkP : 61|1@0+ (1,0) [0|1] "" ICC
 SG_ ESP_RDAEnaFlg : 62|1@0+ (1,0) [0|1] "" ICC

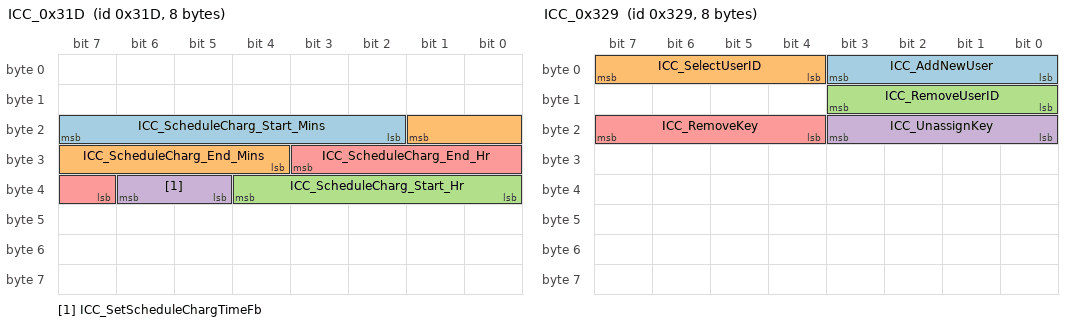
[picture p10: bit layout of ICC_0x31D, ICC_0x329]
BO_ 797 ICC_0x31D: 8 ICC
 SG_ ICC_ScheduleCharg_Start_Mins : 23|6@0+ (1,0) [0|59] "" ICC
 SG_ ICC_ScheduleCharg_End_Mins : 17|6@0+ (1,0) [0|59] "" ICC
 SG_ ICC_ScheduleCharg_Start_Hr : 36|5@0+ (1,0) [0|23] "" ICC
 SG_ ICC_SetScheduleChargTimeFb : 38|2@0+ (1,0) [0|3] "" ICC
 SG_ ICC_ScheduleCharg_End_Hr : 27|5@0+ (1,0) [0|23] "" ICC

BO_ 799 ICC_0x31F: 8 ICC
 SG_ ICC_SetSpeedLimit : 23|8@0+ (1,0) [0|255] "" ICC

BO_ 809 ICC_0x329: 8 ICC
 SG_ ICC_AddNewUser : 3|4@0+ (1,0) [0|15] "" ICC
 SG_ ICC_SelectUserID : 7|4@0+ (1,0) [0|15] "" ICC
 SG_ ICC_RemoveUserID : 11|4@0+ (1,0) [0|15] "" ICC
 SG_ ICC_UnassignKey : 19|4@0+ (1,0) [0|15] "" ICC
 SG_ ICC_RemoveKey : 23|4@0+ (1,0) [0|15] "" ICC

BO_ 812 ICC_0x32C: 8 ICC
 SG_ ICC_SchedUpdate_Selection : 7|64@0+ (1,0) [0|1.84467e+19] "" ICC

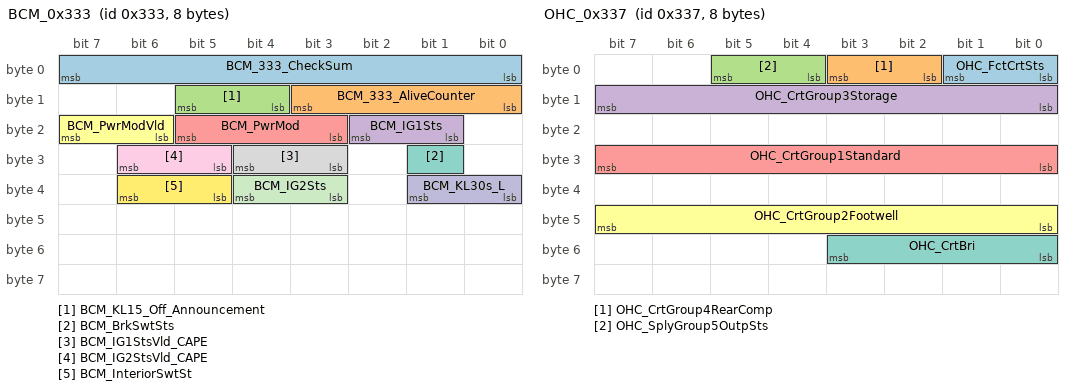
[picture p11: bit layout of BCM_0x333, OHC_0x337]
BO_ 819 BCM_0x333: 8 GW
 SG_ BCM_333_CheckSum : 7|8@0+ (1,0) [0|255] "" ICC
 SG_ BCM_333_AliveCounter : 11|4@0+ (1,0) [0|14] "" ICC
 SG_ BCM_KL15_Off_Announcement : 13|2@0+ (1,0) [0|3] "" ICC
 SG_ BCM_IG1Sts : 18|2@0+ (1,0) [0|3] "" ICC
 SG_ BCM_PwrMod : 21|3@0+ (1,0) [0|7] "" ICC
 SG_ BCM_PwrModVld : 23|2@0+ (1,0) [0|3] "" ICC
 SG_ BCM_BrkSwtSts : 25|1@0+ (1,0) [0|1] "" ICC
 SG_ BCM_IG1StsVld_CAPE : 28|2@0+ (1,0) [0|3] "" ICC
 SG_ BCM_IG2StsVld_CAPE : 30|2@0+ (1,0) [0|3] "" ICC
 SG_ BCM_KL30s_L : 33|2@0+ (1,0) [0|3] "" ICC
 SG_ BCM_IG2Sts : 36|2@0+ (1,0) [0|3] "" ICC
 SG_ BCM_InteriorSwtSt : 38|2@0+ (1,0) [0|3] "" ICC

BO_ 821 BCM_0x335: 8 GW
 SG_ BCM_335_CheckSum : 7|8@0+ (1,0) [0|255] "" ICC
 SG_ BCM_335_AliveCounter : 11|4@0+ (1,0) [0|14] "" ICC
 SG_ BCM_WiprInSrvPosn : 12|1@0+ (1,0) [0|1] "" ICC
 SG_ BCM_IntLampTiSetSts : 15|3@0+ (1,0) [0|7] "" ICC
 SG_ BCM_WaterPosnSnsrSwtSts : 16|1@0+ (1,0) [0|1] "" ICC
 SG_ BCM_FrntFogLampOutpCmd : 17|1@0+ (1,0) [0|1] "" ICC
 SG_ BCM_LicPlateLampOutpCmd : 18|1@0+ (1,0) [0|1] "" ICC
 SG_ BCM_EnaSts_ADB : 19|1@0+ (1,0) [0|1] "" ICC
 SG_ BCM_PwrSaveOutpCmd : 20|1@0+ (1,0) [0|1] "" ICC
 SG_ BCM_ExtLampSwtSts : 23|3@0+ (1,0) [0|7] "" ICC
 SG_ BCM_HornOutpCmd : 24|1@0+ (1,0) [0|1] "" ICC
 SG_ BCM_HornSwtSts : 25|1@0+ (1,0) [0|1] "" ICC
 SG_ BCM_WelLampOutpCmd : 26|1@0+ (1,0) [0|1] "" ICC
 SG_ BCM_FolwMeHomeSts : 27|1@0+ (1,0) [0|1] "" ICC
 SG_ BCM_FrntFogLampSwtSts : 28|1@0+ (1,0) [0|1] "" ICC
 SG_ BCM_ReFogLampSwtSts : 29|1@0+ (1,0) [0|1] "" ICC
 SG_ BCM_ReWiprBackSwtSts : 30|1@0+ (1,0) [0|1] "" ICC
 SG_ BCM_RainClsSunroofSetSts : 31|1@0+ (1,0) [0|0] "" ICC
 SG_ BCM_MirrLockAutoSetSts : 32|1@0+ (1,0) [0|1] "" ICC
 SG_ BCM_FrntWshrOutpCmd : 33|1@0+ (1,0) [0|1] "" ICC
 SG_ BCM_DangerAlrmLampSwtSts : 34|1@0+ (1,0) [0|1] "" ICC
 SG_ BCM_ReDefrstHeatgCmd : 35|1@0+ (1,0) [0|1] "" ICC
 SG_ BCM_RvsLampOutpCmd : 36|1@0+ (1,0) [0|1] "" ICC
 SG_ BCM_IntLampOutpCmd : 37|1@0+ (1,0) [0|1] "" ICC
 SG_ BCM_LeTrunLampOutpCmd : 38|1@0+ (1,0) [0|1] "" ICC
 SG_ BCM_RiTrunLampOutpCmd : 39|1@0+ (1,0) [0|1] "" ICC
 SG_ BCM_ReWiprOutpCmd : 40|1@0+ (1,0) [0|1] "" ICC
 SG_ BCM_ReWshrOutpCmd : 41|1@0+ (1,0) [0|1] "" ICC
 SG_ BCM_BrkLampSwtSts : 42|1@0+ (1,0) [0|1] "" ICC
 SG_ BCM_HiBeamOutpCmd : 43|1@0+ (1,0) [0|1] "" ICC
 SG_ BCM_LoBeamOutpCmd : 44|1@0+ (1,0) [0|1] "" ICC
 SG_ BCM_PosnLampOutpCmd : 46|2@0+ (1,0) [0|3] "" ICC
 SG_ BCM_BrkLampOutpCmd : 47|1@0+ (1,0) [0|1] "" ICC
 SG_ BCM_ReFogLampOutpCmd : 48|1@0+ (1,0) [0|1] "" ICC
 SG_ BCM_FrntWiprSpd : 54|6@0+ (1,0) [0|63] "time/m" ICC
 SG_ BCM_EnaReq_ADB : 55|1@0+ (1,0) [0|1] "" ICC
 SG_ BCM_VehAmbBri : 63|8@0+ (100,0) [0|25400] "lx" ICC

BO_ 822 ICC_0x336: 8 ICC
 SG_ ICC_336_Checksum : 7|8@0+ (1,0) [0|255] "" ICC
 SG_ ICC_336_AliveCounter : 11|4@0+ (1,0) [0|14] "" ICC
 SG_ ICC_SetAtmLampBri : 15|4@0+ (1,0) [0|15] "" ICC
 SG_ ICC_SuspSet : 17|2@0+ (1,0) [0|3] "" ICC
 SG_ ICC_OTAInhbRdy : 19|2@0+ (1,0) [0|3] "" ICC
 SG_ ICC_AtmLampOpenCmd : 20|1@0+ (1,0) [0|1] "" ICC
 SG_ ICC_SteerAssiSet : 23|3@0+ (1,0) [0|7] "" ICC
 SG_ ICC_SetStorageBriLvl : 27|4@0+ (1,0) [0|15] "" ICC
 SG_ ICC_HDCSwtSig : 28|1@0+ (1,0) [0|1] "" ICC
 SG_ ICC_ESPSwtSig : 29|1@0+ (1,0) [0|1] "" ICC
 SG_ ICC_ReqCalifModHMIBtn : 31|2@0+ (1,0) [0|3] "" ICC
 SG_ ICC_SpdLimOffs : 35|4@0+ (1,0) [0|15] "" ICC
 SG_ ICC_iTPMSResetSig : 37|2@0+ (1,0) [0|3] "" ICC
 SG_ ICC_WIFIOnOffSig : 39|2@0+ (1,0) [0|3] "" ICC
 SG_ ICC_LeMirrAlrmLampFlt : 41|2@0+ (1,0) [0|3] "" ICC
 SG_ ICC_RiMirrAlrmLampFlt : 43|2@0+ (1,0) [0|3] "" ICC
 SG_ ICC_PhoneSt : 45|2@0+ (1,0) [0|3] "" ICC
 SG_ ICC_SpeechSt : 47|2@0+ (1,0) [0|3] "" ICC
 SG_ ICC_RemReqFb : 49|2@0+ (1,0) [0|3] "" ICC
 SG_ ICC_SpdLimFdb : 51|2@0+ (1,0) [0|3] "" ICC
 SG_ ICC_OTARdy_Fb : 54|2@0+ (1,0) [0|3] "" ICC

BO_ 823 OHC_0x337: 8 GW
 SG_ OHC_FctCrtSts : 1|2@0+ (1,0) [0|3] "" ICC
 SG_ OHC_CrtGroup4RearComp : 3|2@0+ (1,0) [0|3] "" ICC
 SG_ OHC_SplyGroup5OutpSts : 5|2@0+ (1,0) [0|3] "" ICC
 SG_ OHC_CrtGroup3Storage : 15|8@0+ (1,0) [0|100] "%" ICC
 SG_ OHC_CrtGroup1Standard : 31|8@0+ (1,0) [0|100] "%" ICC
 SG_ OHC_CrtGroup2Footwell : 47|8@0+ (1,0) [0|100] "%" ICC
 SG_ OHC_CrtBri : 51|4@0+ (1,0) [0|15] "" ICC

BO_ 835 BCM_0x343: 8 GW
 SG_ BCM_343_CheckSum : 7|8@0+ (1,0) [0|255] "" ICC
 SG_ BCM_343_AliveCounter : 11|4@0+ (1,0) [0|14] "" ICC
 SG_ BCM_RemReqFb : 13|2@0+ (1,0) [0|3] "" ICC
 SG_ BCM_APASwSts : 15|2@0+ (1,0) [0|3] "" ICC
 SG_ BCM_FrntHoodLidSts : 16|1@0+ (1,0) [0|1] "" ICC
 SG_ BCM_SunroofAntipinchSts : 17|1@0+ (1,0) [0|1] "" ICC
 SG_ BCM_FrntDrDoorLockSts : 18|1@0+ (1,0) [0|1] "" ICC
 SG_ BCM_TrRelsSwtSts : 19|1@0+ (1,0) [0|1] "" ICC
 SG_ BCM_LockAllDoorCmd : 20|1@0+ (1,0) [0|1] "" ICC
 SG_ BCM_DrFrntDoorSts : 21|1@0+ (1,0) [0|1] "" ICC
 SG_ BCM_PasFrntDoorSts : 22|1@0+ (1,0) [0|1] "" ICC
 SG_ BCM_AntithftSts : 25|2@0+ (1,0) [0|3] "" ICC
 SG_ BCM_CenLockSwtSts : 27|2@0+ (1,0) [0|3] "" ICC
 SG_ BCM_DoorUnlockSetFb : 28|1@0+ (1,0) [0|1] "" ICC
 SG_ BCM_RiReDoorSts : 29|1@0+ (1,0) [0|1] "" ICC
 SG_ BCM_LeReDoorSts : 30|1@0+ (1,0) [0|1] "" ICC
 SG_ BCM_LeFrntWinSts : 31|1@0+ (1,0) [0|1] "" ICC
 SG_ BCM_RiFrntWinSts : 32|1@0+ (1,0) [0|1] "" ICC
 SG_ BCM_LeReWinSts : 33|1@0+ (1,0) [0|1] "" ICC
 SG_ BCM_RiReWinSt : 34|1@0+ (1,0) [0|1] "" ICC
 SG_ BCM_SunroofSts : 35|1@0+ (1,0) [0|1] "" ICC
 SG_ BCM_FolwMeSetStsFb : 38|3@0+ (1,0) [0|7] "" ICC
 SG_ BCM_DrvrDoorUnlckOutpCmd : 39|1@0+ (1,0) [0|1] "" ICC
 SG_ BCM_PassDoorUnlckOutpCmd : 40|1@0+ (1,0) [0|1] "" ICC
 SG_ BCM_LeDRLOutpCmd : 41|1@0+ (1,0) [0|1] "" ICC
 SG_ BCM_RiDRLOutpCmd : 42|1@0+ (1,0) [0|1] "" ICC
 SG_ BCM_ArmedClsWinSetSts : 44|1@0+ (1,0) [0|1] "" ICC
 SG_ BCM_OffAutoUnlckSetSts : 45|1@0+ (1,0) [0|1] "" ICC
 SG_ BCM_WarnVbrnSts : 46|1@0+ (1,0) [0|1] "" ICC
 SG_ BCM_SunroofPosnInfo : 55|7@0+ (1,0) [0|127] "%" ICC
 SG_ BCM_SunroofOpenAr : 56|1@0+ (1,0) [0|1] "" ICC
 SG_ BCM_SteerWhlVbrnAlrmAvl : 58|2@0+ (1,0) [0|3] "" ICC
 SG_ BCM_SunroofRunngSts : 61|3@0+ (1,0) [0|7] "" ICC
 SG_ BCM_MirrCmd : 63|2@0+ (1,0) [0|3] "" ICC

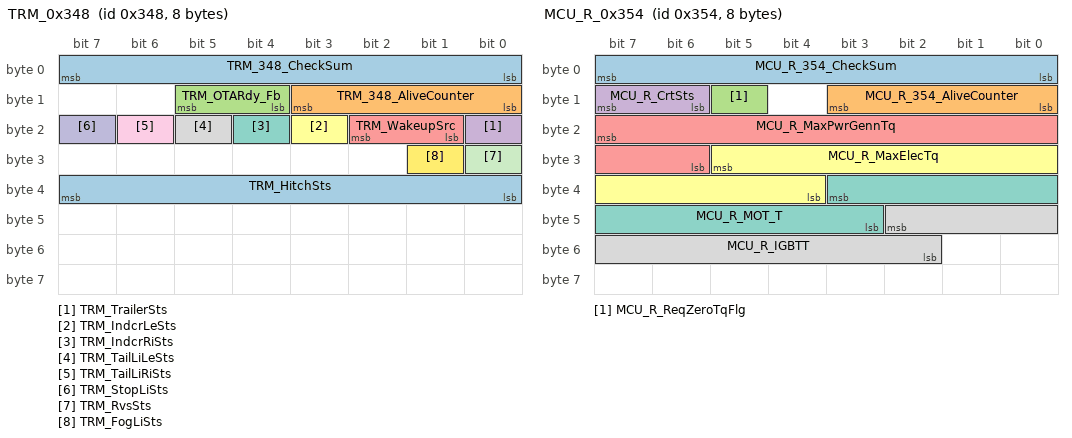
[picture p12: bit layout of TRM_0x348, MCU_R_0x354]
BO_ 840 TRM_0x348: 8 GW
 SG_ TRM_348_CheckSum : 7|8@0+ (1,0) [0|255] "" ICC
 SG_ TRM_348_AliveCounter : 11|4@0+ (1,0) [0|14] "" ICC
 SG_ TRM_OTARdy_Fb : 13|2@0+ (1,0) [0|3] "" ICC
 SG_ TRM_TrailerSts : 16|1@0+ (1,0) [0|1] "" ICC
 SG_ TRM_WakeupSrc : 18|2@0+ (1,0) [0|3] "" ICC
 SG_ TRM_IndcrLeSts : 19|1@0+ (1,0) [0|1] "" ICC
 SG_ TRM_IndcrRiSts : 20|1@0+ (1,0) [0|1] "" ICC
 SG_ TRM_TailLiLeSts : 21|1@0+ (1,0) [0|1] "" ICC
 SG_ TRM_TailLiRiSts : 22|1@0+ (1,0) [0|1] "" ICC
 SG_ TRM_StopLiSts : 23|1@0+ (1,0) [0|1] "" ICC
 SG_ TRM_RvsSts : 24|1@0+ (1,0) [0|1] "" ICC
 SG_ TRM_FogLiSts : 25|1@0+ (1,0) [0|1] "" ICC
 SG_ TRM_HitchSts : 39|8@0+ (1,0) [0|255] "" ICC

BO_ 852 MCU_R_0x354: 8 GW
 SG_ MCU_R_354_CheckSum : 7|8@0+ (1,0) [0|255] "" ICC
 SG_ MCU_R_354_AliveCounter : 11|4@0+ (1,0) [0|14] "" ICC
 SG_ MCU_R_ReqZeroTqFlg : 13|1@0+ (1,0) [0|1] "" ICC
 SG_ MCU_R_CrtSts : 15|2@0+ (1,0) [0|3] "" ICC
 SG_ MCU_R_MaxPwrGennTq : 23|10@0+ (1,-511) [-511|512] "Nm" ICC
 SG_ MCU_R_MaxElecTq : 29|10@0+ (1,-511) [-511|512] "Nm" ICC
 SG_ MCU_R_MOT_T : 35|9@0+ (1,-48) [-48|400] "Degree Celsius" ICC
 SG_ MCU_R_IGBTT : 42|9@0+ (1,-48) [-48|300] "Degree Celsius" ICC

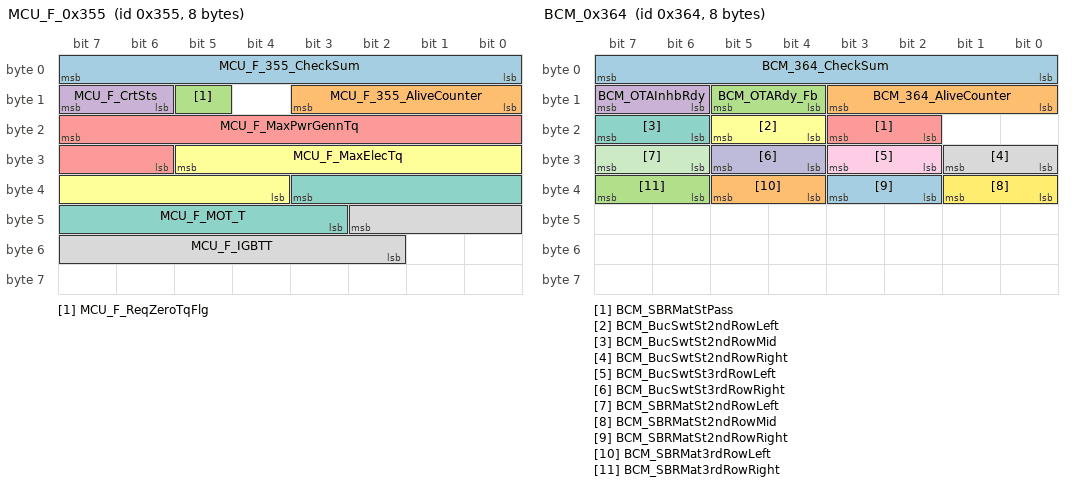
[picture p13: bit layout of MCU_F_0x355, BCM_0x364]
BO_ 853 MCU_F_0x355: 8 GW
 SG_ MCU_F_355_CheckSum : 7|8@0+ (1,0) [0|255] "" ICC
 SG_ MCU_F_355_AliveCounter : 11|4@0+ (1,0) [0|14] "" ICC
 SG_ MCU_F_ReqZeroTqFlg : 13|1@0+ (1,0) [0|1] "" ICC
 SG_ MCU_F_CrtSts : 15|2@0+ (1,0) [0|3] "" ICC
 SG_ MCU_F_MaxPwrGennTq : 23|10@0+ (1,-511) [-511|512] "Nm" ICC
 SG_ MCU_F_MaxElecTq : 29|10@0+ (1,-511) [-511|512] "Nm" ICC
 SG_ MCU_F_MOT_T : 35|9@0+ (1,-48) [-48|400] "Degree Celsius" ICC
 SG_ MCU_F_IGBTT : 42|9@0+ (1,-48) [-48|300] "Degree Celsius" ICC

BO_ 856 VCU_0x358: 8 GW
 SG_ VCU_358_CheckSum : 7|8@0+ (1,0) [0|255] "" ICC
 SG_ VCU_358_AliveCounter : 11|4@0+ (1,0) [0|14] "" ICC
 SG_ VCU_KickdwnFlg : 13|2@0+ (1,0) [0|3] "" ICC
 SG_ VCU_EPedlEnaSig : 15|1@0+ (1,0) [0|1] "" ICC
 SG_ VCU_ComLostFlt_ESP : 16|1@0+ (1,0) [0|1] "" ICC
 SG_ VCU_ComFlt_iBooster : 17|1@0+ (1,0) [0|1] "" ICC
 SG_ VCU_RegenLvlFb : 19|2@0+ (1,0) [0|3] "" ICC
 SG_ VCU_AccelModFb : 21|2@0+ (1,0) [0|3] "" ICC
 SG_ VCU_EPedlStsFb : 23|2@0+ (1,0) [0|3] "" ICC
 SG_ VCU_CcTrgSpdDisp : 31|8@0+ (1,0) [0|255] "" ICC
 SG_ VCU_Sts_CC_ICC : 35|4@0+ (1,0) [0|15] "" ICC
 SG_ VCU_CCIconDisp : 38|3@0+ (1,0) [0|7] "" ICC
 SG_ VCU_DispSpdUnit_CC : 39|1@0+ (1,0) [0|1] "" ICC
 SG_ VCU_BoostEnStat : 43|4@0+ (1,0) [0|15] "" ICC
 SG_ VCU_OTARdy_Fb : 45|2@0+ (1,0) [0|3] "" ICC
 SG_ VCU_OTA_ECUInhb_Req : 47|2@0+ (1,0) [0|3] "" ICC
 SG_ VCU_OTAVehCdnChk_ASIL : 49|2@0+ (1,0) [0|3] "" ICC
 SG_ VCU_OTAVehInhb_ASIL_Fb : 51|2@0+ (1,0) [0|3] "" ICC

BO_ 868 BCM_0x364: 8 GW
 SG_ BCM_364_CheckSum : 7|8@0+ (1,0) [0|255] "" ICC
 SG_ BCM_364_AliveCounter : 11|4@0+ (1,0) [0|14] "" ICC
 SG_ BCM_OTARdy_Fb : 13|2@0+ (1,0) [0|3] "" ICC
 SG_ BCM_OTAInhbRdy : 15|2@0+ (1,0) [0|3] "" ICC
 SG_ BCM_SBRMatStPass : 19|2@0+ (1,0) [0|3] "" ICC
 SG_ BCM_BucSwtSt2ndRowLeft : 21|2@0+ (1,0) [0|3] "" ICC
 SG_ BCM_BucSwtSt2ndRowMid : 23|2@0+ (1,0) [0|3] "" ICC
 SG_ BCM_BucSwtSt2ndRowRight : 25|2@0+ (1,0) [0|3] "" ICC
 SG_ BCM_BucSwtSt3rdRowLeft : 27|2@0+ (1,0) [0|3] "" ICC
 SG_ BCM_BucSwtSt3rdRowRight : 29|2@0+ (1,0) [0|3] "" ICC
 SG_ BCM_SBRMatSt2ndRowLeft : 31|2@0+ (1,0) [0|3] "" ICC
 SG_ BCM_SBRMatSt2ndRowMid : 33|2@0+ (1,0) [0|3] "" ICC
 SG_ BCM_SBRMatSt2ndRowRight : 35|2@0+ (1,0) [0|3] "" ICC
 SG_ BCM_SBRMat3rdRowLeft : 37|2@0+ (1,0) [0|3] "" ICC
 SG_ BCM_SBRMat3rdRowRight : 39|2@0+ (1,0) [0|3] "" ICC

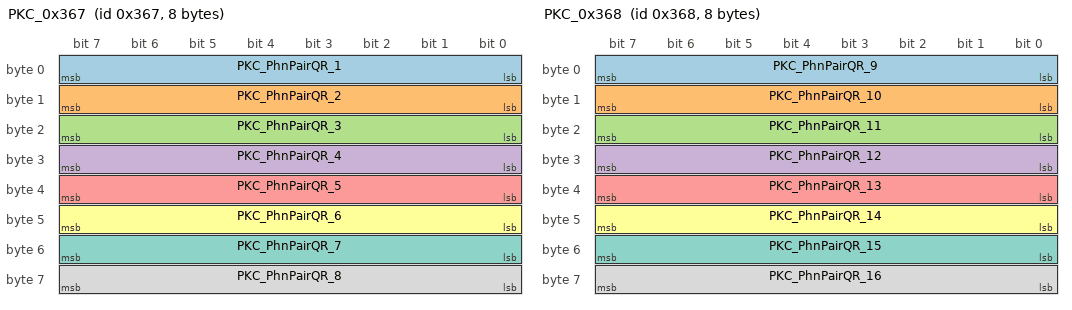
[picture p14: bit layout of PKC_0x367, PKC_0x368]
BO_ 871 PKC_0x367: 8 GW
 SG_ PKC_PhnPairQR_1 : 7|8@0+ (1,0) [0|255] "" ICC
 SG_ PKC_PhnPairQR_2 : 15|8@0+ (1,0) [0|255] "" ICC
 SG_ PKC_PhnPairQR_3 : 23|8@0+ (1,0) [0|255] "" ICC
 SG_ PKC_PhnPairQR_4 : 31|8@0+ (1,0) [0|255] "" ICC
 SG_ PKC_PhnPairQR_5 : 39|8@0+ (1,0) [0|255] "" ICC
 SG_ PKC_PhnPairQR_6 : 47|8@0+ (1,0) [0|255] "" ICC
 SG_ PKC_PhnPairQR_7 : 55|8@0+ (1,0) [0|255] "" ICC
 SG_ PKC_PhnPairQR_8 : 63|8@0+ (1,0) [0|255] "" ICC

BO_ 872 PKC_0x368: 8 GW
 SG_ PKC_PhnPairQR_9 : 7|8@0+ (1,0) [0|255] "" ICC
 SG_ PKC_PhnPairQR_10 : 15|8@0+ (1,0) [0|255] "" ICC
 SG_ PKC_PhnPairQR_11 : 23|8@0+ (1,0) [0|255] "" ICC
 SG_ PKC_PhnPairQR_12 : 31|8@0+ (1,0) [0|255] "" ICC
 SG_ PKC_PhnPairQR_13 : 39|8@0+ (1,0) [0|255] "" ICC
 SG_ PKC_PhnPairQR_14 : 47|8@0+ (1,0) [0|255] "" ICC
 SG_ PKC_PhnPairQR_15 : 55|8@0+ (1,0) [0|255] "" ICC
 SG_ PKC_PhnPairQR_16 : 63|8@0+ (1,0) [0|255] "" ICC

BO_ 883 ECC_0x373: 8 GW
 SG_ ECC_CrtSts : 3|4@0+ (1,0) [0|15] "" ICC
 SG_ ECC_IninSts : 4|1@0+ (1,0) [0|1] "" ICC
 SG_ ECC_PwrSysHeatMngtSts : 6|2@0+ (1,0) [0|3] "" ICC
 SG_ ECC_ACSts : 7|1@0+ (1,0) [0|1] "" ICC
 SG_ ECC_AirClnSts : 8|1@0+ (1,0) [0|1] "" ICC
 SG_ ECC_WindSpdSts : 12|4@0+ (1,0) [0|15] "" ICC
 SG_ ECC_BackRowAirOutlModSts : 15|3@0+ (1,0) [0|7] "" ICC
 SG_ ECC_DrvrTSetSts : 23|8@0+ (0.5,0) [0|127.5] "" ICC
 SG_ ECC_PassTSetSts : 31|8@0+ (0.5,0) [0|127.5] "" ICC
 SG_ ECC_HeatSts : 32|1@0+ (1,0) [0|1] "" ICC
 SG_ ECC_AUTOSts : 33|1@0+ (1,0) [0|1] "" ICC
 SG_ ECC_SYNCSts : 34|1@0+ (1,0) [0|1] "" ICC
 SG_ ECC_InfoSysWrmColdDisp : 36|2@0+ (1,0) [0|3] "" ICC
 SG_ ECC_CircSts : 37|1@0+ (1,0) [0|1] "" ICC
 SG_ ECC_ParticleConcVld : 39|2@0+ (1,0) [0|3] "" ICC
 SG_ ECC_OutdT : 47|8@0+ (0.5,-48) [-48|79.5] "Degree Celsius" ICC
 SG_ ECC_OutdTVld : 49|2@0+ (1,0) [0|3] "" ICC
 SG_ ECC_MaxFrntDefrst : 50|1@0+ (1,0) [0|1] "" ICC
 SG_ ECC_HeatMngtSysFlt : 51|1@0+ (1,0) [0|1] "" ICC
 SG_ ECC_HeatMngtFctLim : 52|1@0+ (1,0) [0|1] "" ICC
 SG_ ECC_DrvrAirOutlMod : 55|3@0+ (1,0) [0|7] "" ICC
 SG_ ECC_PassAirOutlMod : 58|3@0+ (1,0) [0|7] "" ICC
 SG_ ECC_RemSts : 60|2@0+ (1,0) [0|3] "" ICC
 SG_ ECC_OTAInhbRdy : 62|2@0+ (1,0) [0|3] "" ICC

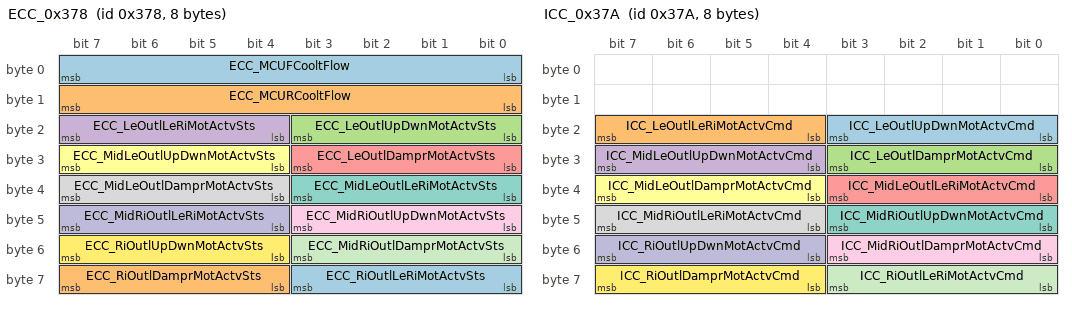
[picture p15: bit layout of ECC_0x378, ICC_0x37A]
BO_ 888 ECC_0x378: 8 GW
 SG_ ECC_MCUFCooltFlow : 7|8@0+ (0.1,0) [0|25.5] "L/min" ICC
 SG_ ECC_MCURCooltFlow : 15|8@0+ (0.1,0) [0|25.5] "L/min" ICC
 SG_ ECC_LeOutlUpDwnMotActvSts : 19|4@0+ (1,0) [0|15] "" ICC
 SG_ ECC_LeOutlLeRiMotActvSts : 23|4@0+ (1,0) [0|15] "" ICC
 SG_ ECC_LeOutlDamprMotActvSts : 27|4@0+ (1,0) [0|15] "" ICC
 SG_ ECC_MidLeOutlUpDwnMotActvSts : 31|4@0+ (1,0) [0|15] "" ICC
 SG_ ECC_MidLeOutlLeRiMotActvSts : 35|4@0+ (1,0) [0|15] "" ICC
 SG_ ECC_MidLeOutlDamprMotActvSts : 39|4@0+ (1,0) [0|15] "" ICC
 SG_ ECC_MidRiOutlUpDwnMotActvSts : 43|4@0+ (1,0) [0|15] "" ICC
 SG_ ECC_MidRiOutlLeRiMotActvSts : 47|4@0+ (1,0) [0|15] "" ICC
 SG_ ECC_MidRiOutlDamprMotActvSts : 51|4@0+ (1,0) [0|15] "" ICC
 SG_ ECC_RiOutlUpDwnMotActvSts : 55|4@0+ (1,0) [0|15] "" ICC
 SG_ ECC_RiOutlLeRiMotActvSts : 59|4@0+ (1,0) [0|15] "" ICC
 SG_ ECC_RiOutlDamprMotActvSts : 63|4@0+ (1,0) [0|15] "" ICC

BO_ 890 ICC_0x37A: 8 ICC
 SG_ ICC_LeOutlUpDwnMotActvCmd : 19|4@0+ (1,0) [0|15] "" ICC
 SG_ ICC_LeOutlLeRiMotActvCmd : 23|4@0+ (1,0) [0|15] "" ICC
 SG_ ICC_LeOutlDamprMotActvCmd : 27|4@0+ (1,0) [0|15] "" ICC
 SG_ ICC_MidLeOutlUpDwnMotActvCmd : 31|4@0+ (1,0) [0|15] "" ICC
 SG_ ICC_MidLeOutlLeRiMotActvCmd : 35|4@0+ (1,0) [0|15] "" ICC
 SG_ ICC_MidLeOutlDamprMotActvCmd : 39|4@0+ (1,0) [0|15] "" ICC
 SG_ ICC_MidRiOutlUpDwnMotActvCmd : 43|4@0+ (1,0) [0|15] "" ICC
 SG_ ICC_MidRiOutlLeRiMotActvCmd : 47|4@0+ (1,0) [0|15] "" ICC
 SG_ ICC_MidRiOutlDamprMotActvCmd : 51|4@0+ (1,0) [0|15] "" ICC
 SG_ ICC_RiOutlUpDwnMotActvCmd : 55|4@0+ (1,0) [0|15] "" ICC
 SG_ ICC_RiOutlLeRiMotActvCmd : 59|4@0+ (1,0) [0|15] "" ICC
 SG_ ICC_RiOutlDamprMotActvCmd : 63|4@0+ (1,0) [0|15] "" ICC

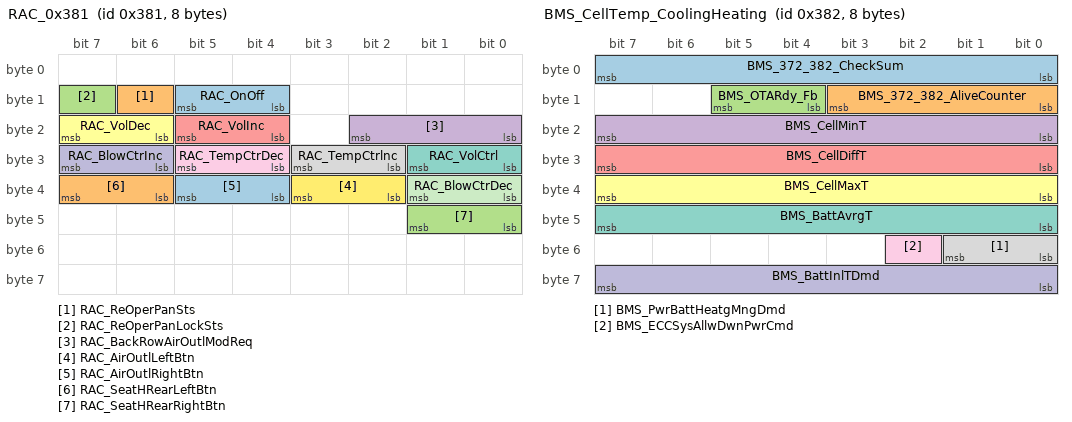
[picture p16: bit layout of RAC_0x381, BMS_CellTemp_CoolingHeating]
BO_ 897 RAC_0x381: 8 RAC
 SG_ RAC_OnOff : 13|2@0+ (1,0) [0|3] "" ICC
 SG_ RAC_ReOperPanSts : 14|1@0+ (1,0) [0|1] "" ICC
 SG_ RAC_ReOperPanLockSts : 15|1@0+ (1,0) [0|1] "" ICC
 SG_ RAC_BackRowAirOutlModReq : 18|3@0+ (1,0) [0|7] "" ICC
 SG_ RAC_VolInc : 21|2@0+ (1,0) [0|3] "" ICC
 SG_ RAC_VolDec : 23|2@0+ (1,0) [0|3] "" ICC
 SG_ RAC_VolCtrl : 25|2@0+ (1,0) [0|3] "" ICC
 SG_ RAC_TempCtrlnc : 27|2@0+ (1,0) [0|3] "" ICC
 SG_ RAC_TempCtrDec : 29|2@0+ (1,0) [0|3] "" ICC
 SG_ RAC_BlowCtrInc : 31|2@0+ (1,0) [0|3] "" ICC
 SG_ RAC_BlowCtrDec : 33|2@0+ (1,0) [0|3] "" ICC
 SG_ RAC_AirOutlLeftBtn : 35|2@0+ (1,0) [0|3] "" ICC
 SG_ RAC_AirOutlRightBtn : 37|2@0+ (1,0) [0|3] "" ICC
 SG_ RAC_SeatHRearLeftBtn : 39|2@0+ (1,0) [0|3] "" ICC
 SG_ RAC_SeatHRearRightBtn : 41|2@0+ (1,0) [0|3] "" ICC

BO_ 898 BMS_CellTemp_CoolingHeating: 8 GW
 SG_ BMS_372_382_CheckSum : 7|8@0+ (1,0) [0|255] "" ICC
 SG_ BMS_372_382_AliveCounter : 11|4@0+ (1,0) [0|14] "" ICC
 SG_ BMS_OTARdy_Fb : 13|2@0+ (1,0) [0|3] "" ICC
 SG_ BMS_CellMinT : 23|8@0+ (1,-48) [-48|207] "Degree Celsius" ICC
 SG_ BMS_CellDiffT : 31|8@0+ (1,0) [0|255] "Degree Celsius" ICC
 SG_ BMS_CellMaxT : 39|8@0+ (1,-48) [-48|207] "Degree Celsius" ICC
 SG_ BMS_BattAvrgT : 47|8@0+ (1,-48) [-48|207] "Degree Celsius" ICC
 SG_ BMS_PwrBattHeatgMngDmd : 49|2@0+ (1,0) [0|3] "" ICC
 SG_ BMS_ECCSysAllwDwnPwrCmd : 50|1@0+ (1,0) [0|1] "" ICC
 SG_ BMS_BattInlTDmd : 63|8@0+ (1,-48) [-48|207] "" ICC

BO_ 899 MCU_F_0x383: 8 GW
 SG_ MCU_F_383_CheckSum : 7|8@0+ (1,0) [0|255] "" ICC
 SG_ MCU_F_383_AliveCounter : 11|4@0+ (1,0) [0|14] "" ICC
 SG_ MCU_F_ParkLockStatus_EV : 15|4@0+ (1,0) [0|15] "" ICC
 SG_ MCU_F_PrkLckStatNrmlOp_EV : 18|3@0+ (1,0) [0|7] "" ICC

BO_ 900 ICC_0x384: 8 ICC
 SG_ ICC_PreHeatDepartSet : 15|2@0+ (1,0) [0|3] "" ICC
 SG_ ICC_MonPreHeatDepartSet : 16|1@0+ (1,0) [0|1] "" ICC
 SG_ ICC_TuePreHeatDepartSet : 17|1@0+ (1,0) [0|1] "" ICC
 SG_ ICC_WedPreHeatDepartSet : 18|1@0+ (1,0) [0|1] "" ICC
 SG_ ICC_ThuPreHeatDepartSet : 19|1@0+ (1,0) [0|1] "" ICC
 SG_ ICC_FriPreHeatDepartSet : 20|1@0+ (1,0) [0|1] "" ICC
 SG_ ICC_SatPreHeatDepartSet : 21|1@0+ (1,0) [0|1] "" ICC
 SG_ ICC_SunPreHeatDepartSet : 22|1@0+ (1,0) [0|1] "" ICC
 SG_ ICC_PreHeatDepartTi1_Mins : 29|6@0+ (1,0) [0|59] "" ICC
 SG_ ICC_SchedChargSet : 31|2@0+ (1,0) [0|3] "" ICC
 SG_ ICC_MonSchedChargSet : 32|1@0+ (1,0) [0|1] "" ICC
 SG_ ICC_TueSchedChargSet : 33|1@0+ (1,0) [0|1] "" ICC
 SG_ ICC_WedSchedChargSet : 34|1@0+ (1,0) [0|1] "" ICC
 SG_ ICC_ThuSchedChargSet : 35|1@0+ (1,0) [0|1] "" ICC
 SG_ ICC_FriSchedChargSet : 36|1@0+ (1,0) [0|1] "" ICC
 SG_ ICC_SatSchedChargSet : 37|1@0+ (1,0) [0|1] "" ICC
 SG_ ICC_SunSchedChargSet : 38|1@0+ (1,0) [0|1] "" ICC
 SG_ ICC_PreHeatDepartTi1_Hr : 44|5@0+ (1,0) [0|23] "" ICC
 SG_ ICC_PreHeatDepartTi2_Hr : 53|5@0+ (1,0) [0|23] "" ICC
 SG_ ICC_PreHeatDepartTi2_Mins : 62|6@0+ (1,0) [0|59] "" ICC
 SG_ ICC_PreHeatDepartSetFb : 48|2@0+ (1,0) [0|3] "" ICC

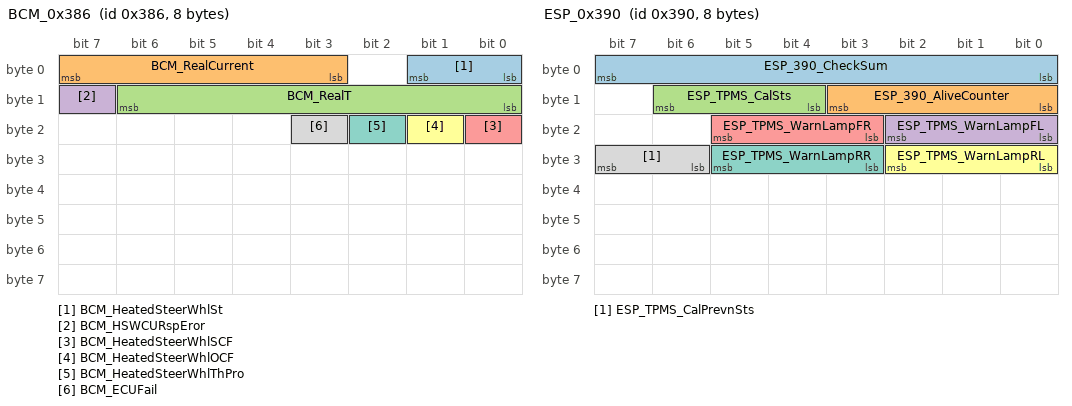
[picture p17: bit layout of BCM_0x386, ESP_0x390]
BO_ 902 BCM_0x386: 8 GW
 SG_ BCM_HeatedSteerWhlSt : 1|2@0+ (1,0) [0|3] "" ICC
 SG_ BCM_RealCurrent : 7|5@0+ (0.5,0) [0|15.5] "A" ICC
 SG_ BCM_RealT : 14|7@0+ (1,-41) [-40|85] "Degree Celsius" ICC
 SG_ BCM_HSWCURspEror : 15|1@0+ (1,0) [0|1] "" ICC
 SG_ BCM_HeatedSteerWhlSCF : 16|1@0+ (1,0) [0|1] "" ICC
 SG_ BCM_HeatedSteerWhlOCF : 17|1@0+ (1,0) [0|1] "" ICC
 SG_ BCM_HeatedSteerWhlThPro : 18|1@0+ (1,0) [0|1] "" ICC
 SG_ BCM_ECUFail : 19|1@0+ (1,0) [0|1] "" ICC

BO_ 912 ESP_0x390: 8 GW
 SG_ ESP_390_CheckSum : 7|8@0+ (1,0) [0|255] "" ICC
 SG_ ESP_390_AliveCounter : 11|4@0+ (1,0) [0|14] "" ICC
 SG_ ESP_TPMS_CalSts : 14|3@0+ (1,0) [0|7] "" ICC
 SG_ ESP_TPMS_WarnLampFL : 18|3@0+ (1,0) [0|7] "" ICC
 SG_ ESP_TPMS_WarnLampFR : 21|3@0+ (1,0) [0|7] "" ICC
 SG_ ESP_TPMS_WarnLampRL : 26|3@0+ (1,0) [0|7] "" ICC
 SG_ ESP_TPMS_WarnLampRR : 29|3@0+ (1,0) [0|7] "" ICC
 SG_ ESP_TPMS_CalPrevnSts : 31|2@0+ (1,0) [0|3] "" ICC

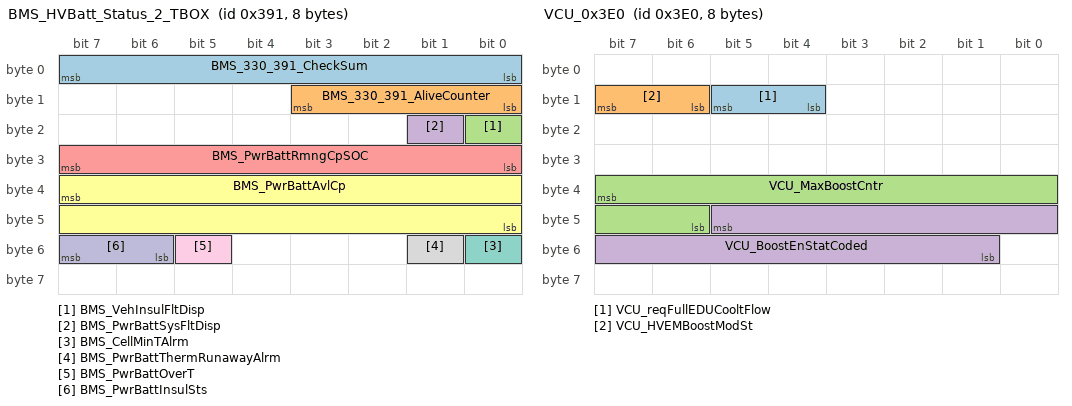
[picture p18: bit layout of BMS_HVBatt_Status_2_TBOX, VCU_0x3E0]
BO_ 913 BMS_HVBatt_Status_2_TBOX: 8 GW
 SG_ BMS_330_391_CheckSum : 7|8@0+ (1,0) [0|255] "" ICC
 SG_ BMS_330_391_AliveCounter : 11|4@0+ (1,0) [0|14] "" ICC
 SG_ BMS_VehInsulFltDisp : 16|1@0+ (1,0) [0|1] "" ICC
 SG_ BMS_PwrBattSysFltDisp : 17|1@0+ (1,0) [0|1] "" ICC
 SG_ BMS_PwrBattRmngCpSOC : 31|8@0+ (0.4,0) [0|100] "%" ICC
 SG_ BMS_PwrBattAvlCp : 39|16@0+ (0.01,0) [0|655.35] "Ah" ICC
 SG_ BMS_CellMinTAlrm : 48|1@0+ (1,0) [0|1] "" ICC
 SG_ BMS_PwrBattThermRunawayAlrm : 49|1@0+ (1,0) [0|1] "" ICC
 SG_ BMS_PwrBattOverT : 53|1@0+ (1,0) [0|1] "" ICC
 SG_ BMS_PwrBattInsulSts : 55|2@0+ (1,0) [0|3] "" ICC

BO_ 965 AMP_0x3C5: 8 AMP
 SG_ AMP_OTAInhbRdy : 15|2@0+ (1,0) [0|3] "" ICC

BO_ 992 VCU_0x3E0: 8 GW
 SG_ VCU_reqFullEDUCooltFlow : 13|2@0+ (1,0) [0|3] "" ICC
 SG_ VCU_HVEMBoostModSt : 15|2@0+ (1,0) [0|3] "" ICC
 SG_ VCU_MaxBoostCntr : 39|10@0+ (1,0) [0|1000] "" ICC
 SG_ VCU_BoostEnStatCoded : 45|13@0+ (1,0) [0|5040] "" ICC

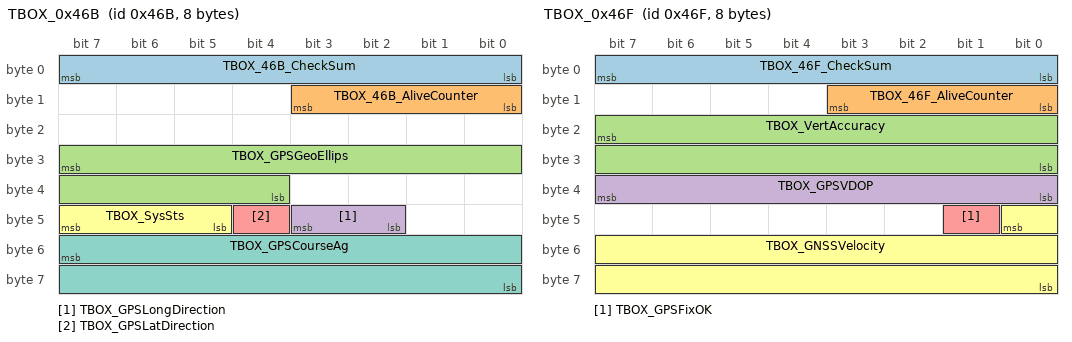
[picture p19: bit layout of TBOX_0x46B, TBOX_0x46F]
BO_ 1131 TBOX_0x46B: 8 GW
 SG_ TBOX_46B_CheckSum : 7|8@0+ (1,0) [0|255] "" ICC
 SG_ TBOX_46B_AliveCounter : 11|4@0+ (1,0) [0|14] "" ICC
 SG_ TBOX_GPSGeoEllips : 31|12@0+ (0.1,-200) [-200|200] "m" ICC
 SG_ TBOX_GPSLongDirection : 43|2@0+ (1,0) [0|3] "" ICC
 SG_ TBOX_GPSLatDirection : 44|1@0+ (1,0) [0|1] "" ICC
 SG_ TBOX_SysSts : 47|3@0+ (1,0) [0|7] "" ICC
 SG_ TBOX_GPSCourseAg : 55|16@0+ (0.01,0) [0|359.9] "deg" ICC

BO_ 1133 TBOX_0x46D: 8 GW
 SG_ TBOX_46D_CheckSumm : 7|8@0+ (1,0) [0|255] "" ICC
 SG_ TBOX_46D_AliveCounter : 11|4@0+ (1,0) [0|14] "" ICC
 SG_ TBOX_GPSEpochWeekNur : 23|16@0+ (1,0) [0|65535] "" ICC
 SG_ TBOX_GPSEpochTOW : 39|32@0+ (1,0) [0|6.048e+07] "" ICC

BO_ 1135 TBOX_0x46F: 8 GW
 SG_ TBOX_46F_CheckSum : 7|8@0+ (1,0) [0|255] "" ICC
 SG_ TBOX_46F_AliveCounter : 11|4@0+ (1,0) [0|14] "" ICC
 SG_ TBOX_VertAccuracy : 23|16@0+ (0.01,0) [0|650] "m" ICC
 SG_ TBOX_GPSVDOP : 39|8@0+ (0.1,0) [0|25] "" ICC
 SG_ TBOX_GPSFixOK : 41|1@0+ (1,0) [0|1] "" ICC
 SG_ TBOX_GNSSVelocity : 40|17@0+ (0.01,0) [0|1000] "m/s" ICC

BO_ 1137 PLGM_0x471: 8 GW
 SG_ PLGM_UsrSetTrMaxHei : 7|8@0+ (1,0) [0|255] "%" ICC
 SG_ PLGM_LeTrPosn : 15|8@0+ (1,0) [0|100] "%" ICC
 SG_ PLGM_RiTrPosn : 23|8@0+ (1,0) [0|100] "%" ICC
 SG_ PLGM_LiRemdngReq_BCM : 26|3@0+ (1,0) [0|7] "" ICC
 SG_ PLGM_SoundRemdngReq_EHU : 29|3@0+ (1,0) [0|7] "" ICC
 SG_ PLGM_FctEnaRes : 30|1@0+ (1,0) [0|1] "" ICC
 SG_ PLGM_SysFltIndcn : 31|1@0+ (1,0) [0|1] "" ICC
 SG_ PLGM_TrActnHandCmd : 33|2@0+ (1,0) [0|3] "" ICC
 SG_ PLGM_TrSwtStsIndcn : 36|3@0+ (1,0) [0|7] "" ICC
 SG_ PLGM_TrLtchStsIndcn : 39|3@0+ (1,0) [0|7] "" ICC
 SG_ PLGM_TrSwtTrigOpenReq : 40|1@0+ (1,0) [0|1] "" ICC
 SG_ PLGM_OperMod : 42|2@0+ (1,0) [0|3] "" ICC
 SG_ PLGM_TrSwtSts : 43|1@0+ (1,0) [0|1] "" ICC
 SG_ PLGM_LimpHomeSts : 44|1@0+ (1,0) [0|1] "" ICC
 SG_ PLGM_DrvrSwtSts : 45|1@0+ (1,0) [0|1] "" ICC
 SG_ PLGM_TrInnrSwtSts : 47|2@0+ (1,0) [0|3] "" ICC
 SG_ PLGM_AntipinchSts : 48|1@0+ (1,0) [0|1] "" ICC
 SG_ PLGM_TrSts : 49|1@0+ (1,0) [0|1] "" ICC
 SG_ PLGM_OTAInhbRdy : 51|2@0+ (1,0) [0|3] "" ICC
 SG_ PLGM_OTARdy_Fb : 53|2@0+ (1,0) [0|3] "" ICC
 SG_ PLGM_Tindcn_NTC : 63|8@0+ (1,-40) [-40|100] "Degree Celsius" ICC

BO_ 1138 TBOX_0x472: 8 GW
 SG_ TBOX_472_CheckSum : 7|8@0+ (1,0) [0|255] "" ICC
 SG_ TBOX_472_AliveCounter : 11|4@0+ (1,0) [0|14] "" ICC
 SG_ TBOX_GNSSReckoningTi : 23|16@0+ (1,0) [0|65000] "s" ICC
 SG_ TBOX_HorzAccuracy : 39|16@0+ (0.01,0) [0|650] "m" ICC
 SG_ TBOX_GPSSpdOverGnd : 55|16@0+ (0.01,0) [0|655.35] "km/h" ICC

BO_ 1139 TBOX_0x473: 8 GW
 SG_ TBOX_473_CheckSum : 7|8@0+ (1,0) [0|255] "" ICC
 SG_ TBOX_473_AliveCounter : 11|4@0+ (1,0) [0|14] "" ICC
 SG_ TBOX_SatellitesNr : 23|8@0+ (1,0) [0|255] "" ICC
 SG_ TBOX_GPSHDOP : 31|8@0+ (0.1,0) [0|25] "" ICC
 SG_ TBOX_Pitch : 47|16@0+ (0.01,-180) [-180|180] "deg" ICC

BO_ 1140 TBOX_0x474: 8 GW
 SG_ TBOX_ICC_UpdSched : 1|2@0+ (1,0) [0|3] "" ICC
 SG_ TBOX_OTAReq_BMS : 17|2@0+ (1,0) [0|3] "" ICC
 SG_ TBOX_OTAReq_VCU : 19|2@0+ (1,0) [0|3] "" ICC
 SG_ TBOX_OTAReq_ECC : 21|2@0+ (1,0) [0|3] "" ICC
 SG_ TBOX_OTAReq_OBC : 23|2@0+ (1,0) [0|3] "" ICC
 SG_ TBOX_OTAReq_MCU_F : 25|2@0+ (1,0) [0|3] "" ICC
 SG_ TBOX_OTAReq_MCU_R : 27|2@0+ (1,0) [0|3] "" ICC
 SG_ TBOX_OTAReq_ADAS : 29|2@0+ (1,0) [0|3] "" ICC
 SG_ TBOX_OTAReq_FCM : 31|2@0+ (1,0) [0|3] "" ICC
 SG_ TBOX_OTAReq_GW : 33|2@0+ (1,0) [0|3] "" ICC
 SG_ TBOX_OTAReq_EPS : 35|2@0+ (1,0) [0|3] "" ICC
 SG_ TBOX_OTAReq_ESP : 37|2@0+ (1,0) [0|3] "" ICC
 SG_ TBOX_OTAReq_iBooster : 39|2@0+ (1,0) [0|3] "" ICC
 SG_ TBOX_OTAReq_SCM : 41|2@0+ (1,0) [0|3] "" ICC
 SG_ TBOX_OTAReq_ICC : 43|2@0+ (1,0) [0|3] "" ICC
 SG_ TBOX_OTAReq_OHC : 45|2@0+ (1,0) [0|3] "" ICC
 SG_ TBOX_OTAReq_BCM : 47|2@0+ (1,0) [0|3] "" ICC
 SG_ TBOX_OTAReq_CIM : 49|2@0+ (1,0) [0|3] "" ICC
 SG_ TBOX_OTAReq_PKC : 51|2@0+ (1,0) [0|3] "" ICC
 SG_ TBOX_OTAReq_PLGM : 53|2@0+ (1,0) [0|3] "" ICC
 SG_ TBOX_OTAReq_TRM : 55|2@0+ (1,0) [0|3] "" ICC
 SG_ TBOX_OTAReq_DSMC : 57|2@0+ (1,0) [0|3] "" ICC
 SG_ TBOX_OTAReq_PSM : 59|2@0+ (1,0) [0|3] "" ICC
 SG_ TBOX_OTAReq_VSP : 61|2@0+ (1,0) [0|3] "" ICC
 SG_ TBOX_OTAReq_TBOX : 63|2@0+ (1,0) [0|3] "" ICC

CM_ SG_ 54 TBOX_RemSeekCarCtrlCmd "Remote vehicle locating control command";
CM_ SG_ 54 TBOX_RemClsTrCmd "Close electric tail gate command remotely";
CM_ SG_ 54 TBOX_RemDrvrSeatVentnCmd "Remote driver seat ventilation command";
CM_ SG_ 54 TBOX_RemDrvrSeatHeatgCmd "Remote driver seat heating command";
CM_ SG_ 54 TBOX_RemSetWelFct "Remotely set opening and closing seat courtesy function and steering wheel courtesy function";
CM_ SG_ 54 TBOX_RemPassSeatVentnCmd "Remote passenger seat ventilation command";
CM_ SG_ 54 TBOX_RemPassSeatHeatgCmd "Remote passenger seat heating command";
CM_ SG_ 54 TBOX_ClsAVMFct_ICC "Turn off ICC remote panoramic function";
CM_ SG_ 54 TBOX_ClsRemAVMFct_AVAP "Turn off AVAP signal remote panoramic function";
CM_ SG_ 54 TBOX_RemSetFolwMeFct_BCM "Remotely set BCM follow me home function, headlamp delay off time";
CM_ SG_ 54 TBOX_RemSetCtrlLockFct_PKC "Remote setting opening and closing inductive PEPS unlocking function";
CM_ SG_ 54 TBOX_RemSetKickSnsrFct "Remote setting turns on and off the foot kick sensor function";
CM_ SG_ 54 TBOX_VideoCtrlReq "Video control request";
CM_ SG_ 54 TBOX_VoiceBlowerLimReq "Voice Blower Limit Rquest";
CM_ SG_ 54 TBOX_RemCtrlCmdFb "TBOX remote control command feedback";
CM_ SG_ 54 TBOX_CtrlReMirrReq "Control rearview mirror request";
CM_ SG_ 54 TBOX_eCallMuteSt "Emergency Call Mute status";
CM_ SG_ 54 TBOX_eCallSt "eCall status";
CM_ BO_ 54 "IBUS1, NoMsgSendType, sent by GW";
CM_ SG_ 68 ICC_FaderSet "Forward/backward balance adjustmentFront/rear audio fader set.";
CM_ SG_ 68 ICC_MediaSrcSet "Main media audio sourceMedia Source Set.";
CM_ SG_ 68 ICC_LeRiBalSet "Left and right balance adjustmentLeft/Right Audio Balance set.";
CM_ SG_ 68 ICC_NavSrcSet "Navigation sound sourceNavi source set.Navi source set.";
CM_ SG_ 68 ICC_MidFrqAudioSet "Middle range adjustmentMid frequency audio set.";
CM_ SG_ 68 ICC_BeepSrcSet "Prompt sound sourceBeep source set.";
CM_ SG_ 68 ICC_LoFrqAudioSet "Low-range adjustmentLow frequency audio set.";
CM_ SG_ 68 ICC_VrTtsSrcSet "Voice and notification sound sourceVoice & Notification Source Set";
CM_ SG_ 68 ICC_HiFrqAudioSet "High range adjustmentHigh frequency audio set.";
CM_ SG_ 68 ICC_AlertSrcSet "Alert audio source";
CM_ SG_ 68 ICC_AlertVolSet "Alert volume setting";
CM_ SG_ 68 ICC_ChimeSrcSet "Alarm sound sourceChime Source Set";
CM_ SG_ 68 ICC_PhnSrcSet "Telephone audio sourcePhone Source Set";
CM_ SG_ 68 ICC_HiTrebFrqAudioSet "ICC to AMP for 5 Band Equalizing";
CM_ SG_ 68 ICC_RTSrcSet "Telephone sound sourceRingtone Source Set";
CM_ SG_ 68 ICC_SubBassFrqAudioSet "ICC to AMP for 5 Band Equalizing";
CM_ BO_ 68 "IBUS1, NoMsgSendType, sent by ICC";
CM_ SG_ 70 ICC_FolwMeHomeTiSet "Central control with me home time setting";
CM_ SG_ 70 ICC_IntrLampTiSet "Central control interior lamp control delay time setting";
CM_ SG_ 70 ICC_BluetoothWifiKeyPaySucFlg "Bluetooth/wifi/smart key/mobile payment success sign";
CM_ SG_ 70 ICC_BluetoothWifiKeyPay "NFC operation mode";
CM_ SG_ 70 ICC_MaiVolSet "Main media volume setting";
CM_ SG_ 70 ICC_MuteCtrl "Silence controlMute all speakers.";
CM_ SG_ 70 ICC_ChimeVolSet "Alarm sound volume settingChime volume set.";
CM_ SG_ 70 ICC_IESSModReq "IESS mode selection requestIESS Model write request to IESS.";
CM_ SG_ 70 ICC_VSCModReq "Volume Speed Gear SelectionVehicle Speed Compensation mode(on/off) request.";
CM_ SG_ 70 ICC_HFTVolSet "Hands-free phone volume settingHFM(hand free mode), RT(ring tone) and Tbox-I/B call volume set.";
CM_ SG_ 70 ICC_EmgyCallSet "Emergency BroadcastingT_boxEcall(emergency call) set (mute all speakers).";
CM_ SG_ 70 ICC_SurrndCtrl "Surround sound controlStereo or surround set.";
CM_ SG_ 70 ICC_NavVolSet "Navigation volume settingNavi volume adjustment.";
CM_ SG_ 70 ICC_GetVoltReq "Obtain internal working voltage of power amplifierGet Amplifier internal voltage request";
CM_ SG_ 70 ICC_RTVolSet "Ring volume settingRT(ring tone) volume set.";
CM_ SG_ 70 ICC_GetDTCInfo "Obtain amplifier diagnosis resultGet the DTC result of AMP";
CM_ SG_ 70 ICC_GetSwVer "Obtain power amplifier software versionGet the SW version of AMP";
CM_ SG_ 70 ICC_VrTtsVolSet "Voice and notification volume settingsVoice & Notification Source volume set";
CM_ SG_ 70 ICC_GetHwVer "Obtain power amplifier hardware versionGet the HW version of AMP";
CM_ SG_ 70 ICC_GetTempReq "Obtain internal temperature of amplifierGet temperature Value request";
CM_ BO_ 70 "IBUS1, NoMsgSendType, sent by ICC";
CM_ SG_ 72 AMP_Ch1DTCInfo "CH1 Diagnostic resultAmplifier output channel 1 DTC informatio.";
CM_ SG_ 72 AMP_Ch2DTCInfo "CH2 Diagnostic resultAmplifier output channel 2 DTC information.";
CM_ SG_ 72 AMP_Ch3DTCInfo "CH3 Diagnostic resultsAmplifier output channel 3 DTC information.";
CM_ SG_ 72 AMP_Ch4DTCInfo "CH4 diagnostic resultAmplifier output channel 4 DTC information.";
CM_ SG_ 72 AMP_Ch5DTCInfo "CH5 Diagnostic resultAmplifier output channel 5 DTC information.";
CM_ SG_ 72 AMP_Ch6DTCInfo "CH6 Diagnostic resultAmplifier output channel 6 DTC information.";
CM_ SG_ 72 AMP_Ch7DTCInfo "CH7 Diagnostic resultAmplifier output channel 7 DTC information.";
CM_ SG_ 72 AMP_Ch8DTCInfo "CH8 Diagnostic resultsAmplifier output channel 8 DTC information.";
CM_ SG_ 72 AMP_IntT "Internal temperatureAmplifier internal temperature.";
CM_ SG_ 72 AMP_IntVolt "Internal VoltageAmplifier internal voltage.";
CM_ SG_ 72 AMP_IntTSts "Internal temperature stateThe value of AMP temperature status.";
CM_ SG_ 72 AMP_PhnSrcSts "Telephone audio source statusPhone Source State";
CM_ SG_ 72 AMP_VrTtsSrcSet "Voice and notification sound source statusVoice & Notification Source State";
CM_ SG_ 72 AMP_RTVolSet "Ring volume RT(ring tone) volume status.";
CM_ SG_ 72 AMP_RTSrcSts "Telephone sound source statusRingtone Source State";
CM_ SG_ 72 AMP_VrTtsVolSet "Voice and notification volumeVoice & Notification Source volume status.";
CM_ SG_ 72 AMP_ChimeSrcSts "Alarm sound source stateChime Source State";
CM_ SG_ 72 AMP_AlertVolSetSts "Alert volume";
CM_ SG_ 72 AMP_AlertSrcSet "Alert audio source status";
CM_ BO_ 72 "IBUS1, NoMsgSendType, sent by AMP";
CM_ SG_ 73 AMP_BalSetSts "Left/right balance adjustment stateBalance setting.";
CM_ SG_ 73 AMP_VSCModSts "Volume speed gearVehicle Speed Compensation on/off.";
CM_ SG_ 73 AMP_SurrndCtrlSts "Surrounding sound control stateStereo or surround state.";
CM_ SG_ 73 AMP_FaderSetSts "Forward and backward balance adjustment stateFade setting.";
CM_ SG_ 73 AMP_EmgyCallSetSts "Emergency Broadcasting stateT_box Ecall(emergency call) status (mute all speakers).";
CM_ SG_ 73 AMP_IESSModSts "IESS mode stateIESS model status feedback to HUT.";
CM_ SG_ 73 AMP_LoFrqAudioSetSts "Low-range adjustment stateLow frequency audio setting.";
CM_ SG_ 73 AMP_BeepSrcSts "State of sound sourceBeep source status.";
CM_ SG_ 73 AMP_MidFrqAudioSetSts "Middle range adjustment stateMid frequency audio setting.";
CM_ SG_ 73 AMP_MediaSrcSts "Master audio source statusMedia Source State";
CM_ SG_ 73 AMP_HiFrqAudioSetSts "High-tone range adjustment stateHigh frequency audio setting.";
CM_ SG_ 73 AMP_NavSrcSts "Navigation audio source stateNavi state imformation";
CM_ SG_ 73 AMP_HFTVolSetSts "Hands-free phone volumeHFM(hand free mode), RT(ring tone) and Tbox-I/B call volume set status.";
CM_ SG_ 73 AMP_MuteCtrlSts "Silence control stateMute/Unmute all speakers.";
CM_ SG_ 73 AMP_NavVolSetSts "Navigation volumeNavi volume adjustment.";
CM_ SG_ 73 AMP_MaiVolSetSts "Main media volumeMain volume step.";
CM_ SG_ 73 AMP_ChimeVolSetSts "Alarm sound volumeChime volume set status.";
CM_ BO_ 73 "IBUS1, NoMsgSendType, sent by AMP";
CM_ SG_ 74 AMP_GetHutInfoSts "Obtain host initialization informationGet HUT Status.";
CM_ SG_ 74 AMP_HiTrebFrqAudioSetSts "Feedback signals from AMP to ICC for 5-Band Equalizing";
CM_ SG_ 74 AMP_SubBassFrqAudioSetSts "Feedback signals from AMP to ICC for 5-Band Equalizing";
CM_ BO_ 74 "IBUS1, NoMsgSendType, sent by AMP";
CM_ SG_ 76 ICC_BluetoothMACwifi "Bluetooth MAC address/wifi AP and key (7 bytes MAC address/WIFI AP and keyLength of SSID: 8: 1:32 bytes.Bluetooth default name is ARCFOX, with a maximum of 248 8-bit-byte UTF8 encoded characters.)";
CM_ BO_ 76 "IBUS1, NoMsgSendType, sent by ICC";
CM_ SG_ 78 ICC_abdEnaReq "adb enable request";
CM_ SG_ 78 ICC_RiFrntWinCtrl "Front passenger side window control";
CM_ SG_ 78 ICC_LeReWinCtrl "Left rear window control";
CM_ SG_ 78 ICC_RiReWinCtrl "Right rear side window control";
CM_ SG_ 78 ICC_LeFrntWinCtrl "Driver's window control";
CM_ SG_ 78 ICC_FrntWshrCtrl "Front washing control";
CM_ SG_ 78 ICC_FrntWiprCtrl "Front wiper control";
CM_ SG_ 78 ICC_ReWiprCtrl "Rear wiper control";
CM_ SG_ 78 ICC_PosnLampCtrl "Position lamp control";
CM_ SG_ 78 ICC_HiBeamCtrl "High beam control";
CM_ SG_ 78 ICC_LoBeamCtrl "Dipped beam control";
CM_ SG_ 78 ICC_ReWshrCtrl "Rear washing control";
CM_ SG_ 78 ICC_TrunkLockCtrl "Trunk lid control";
CM_ SG_ 78 ICC_SunroofPercCtrlCmdReq "Sunroof horizontal opening control command request";
CM_ SG_ 78 ICC_FrntFogLampCtrl "Central control front fog lamp control";
CM_ SG_ 78 ICC_ReFogLampCtrl "Central control rear fog lamp control";
CM_ SG_ 78 ICC_ReDefrstOpenReq "Rear defrosting ON request";
CM_ SG_ 78 ICC_SunshadeCtrlReq "Sunshade control request";
CM_ SG_ 78 ICC_CentrLockCtrl "Central control screen central control lock control";
CM_ SG_ 78 ICC_MirrCmd "Central control exterior rearview mirror control";
CM_ SG_ 78 ICC_ReMirrAutoFoldSet "Automatic folding setting of central control rearview mirror locking";
CM_ SG_ 78 ICC_SunroofshadePercCtrlCmdReq "Horizontal opening mark positionSunroof or shade control select.";
CM_ SG_ 78 ICC_RainClsdSunroofSet "Central control screen closing sunroof setting in rainy days";
CM_ SG_ 78 ICC_ArmedClsdWinSet "Setting of central control screen flocking window";
CM_ SG_ 78 ICC_OffUnlckSet "Automatic unlocking setting of central control flameout";
CM_ SG_ 78 ICC_DoorUnlockSet "Door unlocking setting";
CM_ BO_ 78 "IBUS1, NoMsgSendType, sent by ICC";
CM_ SG_ 82 ICC_WIFIAPAuthentMechanism "WIFI AP authentication mechanism";
CM_ SG_ 82 ICC_SetMaxPosnCmd_PLGM "Central control setting of rear door maximum opening height commandReset maximum height by touchscreen.";
CM_ SG_ 82 ICC_TrActnCmd "Central control command to open and close the rear doorOpen or close item trunk by touch or voice.";
CM_ SG_ 82 ICC_Ota_Inst "Response of OTA installation";
CM_ SG_ 82 ICC_DrvrMirrTurnDwnAllwd "Automatic downturning setting of exterior rearview mirror";
CM_ SG_ 82 ICC_Updcomp "ICC update complited";
CM_ BO_ 82 "IBUS1, cyclic every 100 ms, sent by ICC";
CM_ SG_ 88 TBOX_58_SSecOC_Fresh_Byte0 "Short SecOC Fresh signal byte 0 on CAN";
CM_ SG_ 88 TBOX_58_SSecOC_MAC_Byte0 "Short SecOC MAC signal byte 0 on CAN";
CM_ SG_ 88 TBOX_58_SSecOC_MAC_Byte1 "Short SecOC MAC signal byte 1 on CAN";
CM_ SG_ 88 TBOX_58_SSecOC_MAC_Byte2 "Short SecOC MAC signal byte 2 on CAN";
CM_ BO_ 88 "IBUS1, CE every 100 ms, sent by GW";
CM_ SG_ 89 ACU_59_CheckSum "ACU_59_CheckSum (E2E data ID: 0x98)";
CM_ SG_ 89 ACU_59_AliveCounter "ACU_0x59_Message counterACU_59_AliveCounter";
CM_ SG_ 89 ACU_FrntCrashOutpSts "Front Crash Status";
CM_ SG_ 89 ACU_RiSideCrashOutpSts "Right Side Crash Status";
CM_ SG_ 89 ACU_LeSideCrashOutpSts "Left Side Crash Status";
CM_ SG_ 89 ACU_RearCrashOutpSts "Rear Crash Status";
CM_ SG_ 89 ACU_RollovrCrashOutpSts "Rollover Crash Status";
CM_ SG_ 89 ACU_Crash_cfm "Crash confirm signal";
CM_ BO_ 89 "IBUS1, CE every 50 ms, sent by GW";
CM_ SG_ 98 DSMC_DrvrSeatMemRecallFb "Driver seat memory recall feedback";
CM_ SG_ 98 DSMC_DrvrSeatWelFctSetFb "Driver seat courtesy function setting feedback";
CM_ SG_ 98 DSMC_DrvrSeatAntithftFctSetFb "Driver seat anti-theft function setting feedback";
CM_ SG_ 98 DSMC_ReMirrAutoDwnFlipFb "Automatic downturn feedback of reversing rearview mirror";
CM_ SG_ 98 DSMC_DrvrSeatMemDataUpdFb "Driver seat memory information update complete feedback";
CM_ BO_ 98 "IBUS1, NoMsgSendType, sent by GW";
CM_ SG_ 100 PLGM_UsrSetTrMaxHeiResFb "The result feedback of the user setting the maximum opening height of the rear door If user customize the maximum height, PLG give feedback to ICC to indicate result on screen.";
CM_ SG_ 100 PLGM_RemTrCtrlFbInfo "Remote tailgate control feedback information";
CM_ SG_ 100 PLGM_LtchMotRtrnSig "Rear door lock motor return signal";
CM_ BO_ 100 "IBUS1, NoMsgSendType, sent by GW";
CM_ SG_ 144 ICC_PairingCmd "Status of login UID of vehicle end account";
CM_ SG_ 144 ICC_VehAccountLoginUIDSts "Status of login UID of vehicle end account";
CM_ SG_ 144 ICC_VehAccountLoginUID "User account login UID";
CM_ SG_ 144 ICC_SeatLocnMemOperCmd "Seat position memory operation command";
CM_ SG_ 144 ICC_AutoLockUnlockCmd "Status of login UID of vehicle end account";
CM_ BO_ 144 "IBUS1, NoMsgSendType, sent by ICC";
CM_ SG_ 146 ICC_SteerWhlYDirDataSyncnCmd "Steering wheel column Y direction position data synchronization command";
CM_ SG_ 146 ICC_SteerWhlZDirDataSyncnCmd "Steering wheel column Z direction position data synchronization command";
CM_ SG_ 146 ICC_SteerWhlElecAdjSwtSts "Electric adjustment handle for steering wheel switch status.";
CM_ SG_ 146 ICC_SteerWhlHeatgSwtSts "Steering wheel heating switch statesteering wheel heating switch signal.";
CM_ BO_ 146 "IBUS1, NoMsgSendType, sent by ICC";
CM_ SG_ 148 ICC_LeReMirrXDirDataSyncnCmd "Left rearview mirrorxdirection position data synchronization command";
CM_ SG_ 148 ICC_LeReMirrYDirDataSyncnCmd "Left rearview mirror Y direction position data synchronization command";
CM_ SG_ 148 ICC_RiReMirrXDirDataSyncnCmd "Right rearview mirrorxdirection position data synchronization command";
CM_ SG_ 148 ICC_RiReMirrYDirDataSyncnCmd "Right rearview mirror Y direction position data synchronization command";
CM_ BO_ 148 "IBUS1, NoMsgSendType, sent by ICC";
CM_ SG_ 150 ICC_DrvrSeatSldDataSyncnCmd "Driver seat slide position data synchronization command";
CM_ SG_ 150 ICC_DrvrSeatHeiDataSyncnCmd "Driver seat height position data synchronization command";
CM_ SG_ 150 ICC_DrvrSeatBackDataSyncnCmd "Driver seat backrest position data synchronization command";
CM_ SG_ 150 ICC_DrvrSeatCushAgPosn "Driver's seat cushion angle position";
CM_ BO_ 150 "IBUS1, NoMsgSendType, sent by ICC";
CM_ SG_ 237 BMS_OverallStatus_CheckSum "Checksum(E2E data ID: 0x22)";
CM_ SG_ 237 BMS_OverallStatus_AliveCounter "Rolling counter";
CM_ SG_ 237 BMS_OperationStates "BMS operational states";
CM_ SG_ 237 BMS_BallancingStatus "BMS balancing status";
CM_ SG_ 237 BMS_ErrorCategory_CAT0 "Escalation level of an error";
CM_ SG_ 237 BMS_ErrorCategory_CAT1 "Escalation level of an error";
CM_ SG_ 237 BMS_ErrorCategory_CAT2 "Escalation level of an error";
CM_ SG_ 237 BMS_ErrorCategory_CAT3 "Escalation level of an error";
CM_ SG_ 237 BMS_ErrorCategory_CAT4 "Escalation level of an error";
CM_ SG_ 237 BMS_ErrorCategory_CAT5 "Escalation level of an error";
CM_ SG_ 237 BMS_ErrorCategory_CAT6 "Escalation level of an error";
CM_ SG_ 237 BMS_ErrorCategory_CAT7 "Escalation level of an error";
CM_ SG_ 237 BMS_ErrorCategory_CAT8 "Escalation level of an error";
CM_ SG_ 237 BMS_HardwareStatus_OK "BMS Hardware OK Flag, Internal Temp. And and Voltages are okey";
CM_ SG_ 237 BMS_ErrorCategory_Mem_Empty "BMS Error memory is empty and OK";
CM_ SG_ 237 BMS_ConfigurationStatus_OK "BMS Configuration was successful";
CM_ SG_ 237 BMS_MeasurementModules_OK "BMS Measurement Modules OK";
CM_ SG_ 237 BMS_BatteryGeneralStatus_OK "BMS Battery status OK";
CM_ SG_ 237 BMS_SDIL_Sts "BMS Service Disconnect status";
CM_ SG_ 237 BMS_CL30C_Sts "BMS Clamp 30 status";
CM_ SG_ 237 BMS_CL15_Sts "BMS Clamp 15 status";
CM_ SG_ 237 BMS_HVIL_OK "BMS BMS HV Interlock OK";
CM_ SG_ 237 BMS_HV_ContactorsStatus_OK "BMS High Voltage / Main contactors OK";
CM_ SG_ 237 BMS_SW_Status_OK "BMS Algorithm status OK";
CM_ SG_ 237 BMS_CurrentSensor_OK "BMS IVT (Current Sensor) OK";
CM_ SG_ 237 BMS_IsolatoinStatus_OK "BMS Insolation and IMD OK";
CM_ SG_ 237 BMS_StateMAchine_Status "Status of system state machine";
CM_ SG_ 237 BMS_BDU_Status "Status of battery disconnect unit";
CM_ BO_ 237 "IBUS1, cyclic every 20 ms, sent by GW";
CM_ SG_ 274 YRS_112_CheckSum "YRS_112_Message Checksum (E2E data ID: 0xA1)";
CM_ SG_ 274 YRS_112_AliveCounter "YRS_112_ AliveCounter";
CM_ SG_ 274 YRS_YawRateCalSts "Yaw rate sensor calibration state Indicates Yaw Rate Sensor Calibration State.";
CM_ SG_ 274 YRS_YawRateSnsrSts "Status of yaw rate sensor Indicates Yaw Rate Sensor State.";
CM_ SG_ 274 YRS_LatSnsrSts "Status of lateral sensor Indicates Lateral Sensor State.";
CM_ SG_ 274 YRS_LatAcce "Lateral acceleration (left positive, right negative, Real Value = raw value-offset)Indicates Lateral Acceleration.";
CM_ SG_ 274 YRS_YawRate "Indicates the yaw rate (counterclockwise positive, clockwise negative, Real Value = raw value-offset)Indicates Yaw Rate.";
CM_ BO_ 274 "IBUS1, cyclic every 10 ms, sent by GW";
CM_ SG_ 275 YRS_113_CheckSum "YRS_113_Message Checksum (E2E data ID: 0xB8)";
CM_ SG_ 275 YRS_113_AliveCounter "YRS_113_AliveCounter";
CM_ SG_ 275 YRS_LgtSnsrSts "Status of lateral sensorIndicates Lateral Sensor State.";
CM_ SG_ 275 YRS_LgtAcce "Longitudinal acceleration (Forward positive, Backward negative, Real Value = raw value-offset)Indicates Longitudinal Acceleration";
CM_ BO_ 275 "IBUS1, cyclic every 10 ms, sent by GW";
CM_ SG_ 276 ESP_114_CheckSum "ESP_114_Message checksum (E2E data ID: 0x72)";
CM_ SG_ 276 ESP_114_AliveCounter "EP_114 _Message counter";
CM_ SG_ 276 ESP_OTARdy_Fb "ESP OTA ready status feedback";
CM_ SG_ 276 ESP_FltIndcn_DTC "ESP/TCS fault indication Signal indicates failure monitoring of ESP function. Not used for ABS";
CM_ SG_ 276 ESP_ActvSig_VDC "ESP activation signal VDC operating When ESP is active shall the system send out a bus signal. Not used for ABS.";
CM_ SG_ 276 ESP_ActvSig_TCS "TCS activation signal TCS operating(including DTC operating)When TCS is active shall the system send out a bus signal. Not used for ABS.";
CM_ SG_ 276 ESP_ActvSig_EBD "EBD activation signal indicating EBD in active control or not.";
CM_ SG_ 276 ESP_ActvSig_DTC "DTC activation signal indicate DTC in active control or not.";
CM_ SG_ 276 ESP_WarningOn "ESP brake fault turning on request With this signal ESP requests the warning in the dashboard.";
CM_ SG_ 276 ESP_Actvndcn_CDD "CDD operation indication indicating CDD is working or not.";
CM_ SG_ 276 ESP_FltIndcn_CDD "CDD fault indication indicating CDD is available or not.";
CM_ SG_ 276 ESP_ActvIndcn_ABA "ABA working indication ABA is active.";
CM_ SG_ 276 ESP_FltIndcn_ABA "ABA fault indication the ABA function is available.";
CM_ SG_ 276 ESP_ActvIndcn_ABP "ABP operation indication Prefill (ABP) is active.";
CM_ SG_ 276 ESP_FltIndcn_ABP "ABP fault indication Prefill (ABP) is available.";
CM_ SG_ 276 ESP_ActvIndcn_AEB "AEB operation indication ESP is excuting AEB braking function.";
CM_ SG_ 276 ESP_FltIndcn_AEB "AEB fault indication AEB is available.";
CM_ SG_ 276 ESP_ActvIndcn_AWB "AWB operation indication AWB is active(brake jerk).";
CM_ SG_ 276 ESP_FltIndcn_AWB "AWB fault indication AWB is available. Feedback of AWB activation for ACC.";
CM_ SG_ 276 ESP_VehStandstillIndcn "Vehicle stop indication indicating whether the vehicle is standstill or not; must not be set until standstill is surely reached.";
CM_ SG_ 276 ESP_BrkOverTIndcn "Brake disc high temperature indication , set 1 to exit ACC function indicating brake temperature too high or not.";
CM_ SG_ 276 ESP_FltIndcn_VDC "ESP/TCS fault indication Signal indicates failure monitoring of ESP function. Not used for ABS";
CM_ SG_ 276 ESP_ActvIndcn_CDD_AP "ECS Active indication_CDD_APWhen VLC AP is active shall the system send out a bus signal.";
CM_ SG_ 276 ESP_FltIndcn_CDD_AP "Signal from ESC indicates whether CDD_AP is activated When VLC AP is active shall the system send out a bus signal.";
CM_ BO_ 276 "IBUS1, cyclic every 20 ms, sent by GW";
CM_ SG_ 277 ESP_115_CheckSum "ESP_115_Message checksum (E2E data ID: 0x8A)";
CM_ SG_ 277 ESP_115_AliveCounter "EP_115 _Message counter";
CM_ SG_ 277 ESP_WhlSpdVld_RF "Effective right front wheel speed Validty of signal 'WHEEL_SPEED_FRONT_RIGHT_ACC '";
CM_ SG_ 277 ESP_WhlSpd_RF "Right front wheel speed Wheel speed of the front right wheel.";
CM_ SG_ 277 ESP_WhlMovgDir_RF "Front right wheel movement direction (positive forward and negative backward)Front Right wheel Moving direction.";
CM_ SG_ 277 ESP_WhlMovgDir_LF "Front left wheel movement direction (positive forward and negative backward)Front left wheel Moving direction.";
CM_ SG_ 277 ESP_WhlSpdVld_LF "Effective position of left front wheel speed Validty of signal 'WHEEL_SPEED_FRONT_LEFT_ACC'";
CM_ SG_ 277 ESP_WhlSpd_LF "Left front wheel speed Wheel speed of the front left wheel.";
CM_ BO_ 277 "IBUS1, cyclic every 10 ms, sent by GW";
CM_ SG_ 336 MCU_F_150_CheckSum "Front MCU_150_Message checksum(E2E data ID: 0x29)";
CM_ SG_ 336 MCU_F_150_AliveCounter "MCU_150_Message Counter FrontMCU_F_150_AliveCounter";
CM_ SG_ 336 MCU_F_CrtTqVld "Effective torque of front drive motorMotorFTorquevalidflag";
CM_ SG_ 336 MCU_F_CrtRotDir "Current rotation direction of front drive motorMotorFRotingdirection";
CM_ SG_ 336 MCU_F_CrtSpd "Current speed of front drive motorMotorFSpeed";
CM_ SG_ 336 MCU_F_CrtSpdSigVld "Effective position of front drive motor current speed signalMotorFSpeedsignalvalidflag";
CM_ SG_ 336 MCU_F_CrtTq "Current torque of front drive motorMotorFTorque";
CM_ SG_ 336 MCU_F_CrtMod "Current operating mode of front drive motorMotorFworkingmode";
CM_ SG_ 336 MCU_F_HVActvDchaSts "High-voltage active discharge state of front MCUHVActiveDischargeState";
CM_ SG_ 336 MCU_F_SlipCtrlActMode "the Anti-Slip Control (ASC or ASR on german) state";
CM_ SG_ 336 MCU_F_AlrmLamp_FS "Warning lamp_front drive motor (functional safety)";
CM_ SG_ 336 MCU_F_HVChkEndFlg "High voltage detection completion flag of front MCUMCUFHVCheckStates";
CM_ BO_ 336 "IBUS1, cyclic every 10 ms, sent by GW";
CM_ SG_ 337 MCU_R_151_CheckSum "Rear MCU_151_Message checksum (E2E data ID: 0x34)";
CM_ SG_ 337 MCU_R_151_AliveCounter "Rear MCU_151_Message counterMCU_R_151_AliveCounter";
CM_ SG_ 337 MCU_R_CrtTqVld "Effective torque of rear drive motorMotorRTorquevalidflag";
CM_ SG_ 337 MCU_R_CrtRotDir "Current rotation direction of rear drive motorMotorRRotingdirection";
CM_ SG_ 337 MCU_R_CrtSpd "Current speed of rear drive motorMotorRSpeed";
CM_ SG_ 337 MCU_R_CrtSpdSigVld "Effective position of current speed signal of rear drive motorMotorRSpeedsignalvalidflag";
CM_ SG_ 337 MCU_R_CrtTq "Current torque of rear drive motorMotorRTorque";
CM_ SG_ 337 MCU_R_CrtMod "Current working mode of rear drive motorMotorRworkingmode";
CM_ SG_ 337 MCU_R_Decoup_State "Disconnect status";
CM_ SG_ 337 MCU_R_HVActvDchaSts "High-voltage active discharge state of rear MCUHVActiveDischargeState";
CM_ SG_ 337 MCU_R_SlipCtrlActMode "the Anti-Slip Control (ASC or ASR on german) state";
CM_ SG_ 337 MCU_R_AlrmLamp_FS "Warning lamp_rear drive motor (functional safety)";
CM_ SG_ 337 MCU_R_HVChkEndFlg "High voltage detection completion flag of rear drive motor controllerMCURHVCheckStates";
CM_ SG_ 337 ACU_159_CheckSum "ACU_0x159_Message Checksum ( E2E data ID: 0x97)";
CM_ SG_ 337 ACU_159_AliveCounter "ACU_0x159_Message counterACU_159_AliveCounter";
CM_ SG_ 337 ACU_Pass_OCS_St "Passenger Occupant Status OCS (not for China)";
CM_ SG_ 337 ACU_AirBagSysAlrmLampSts "State of warning lamp of airbag system";
CM_ SG_ 337 ACU_Pass_Airbag_LED "Passenger LED Status";
CM_ SG_ 337 ACU_Drvr_Occpt_St "Driver Occupant Status";
CM_ SG_ 337 ACU_BucSwtStFrntDrvr "Buckle switch state front driver";
CM_ SG_ 337 ACU_BucSwtStFrntPass "Buckle switch state front passenger";
CM_ SG_ 337 ACU_SeatTrkPosnSwtFrntDrvr "Seat Track Position Sensor Front Driver";
CM_ SG_ 337 ACU_SeatTrkPosnSwtFrntPass "Seat Track Position Sensor Front Passenger";
CM_ BO_ 337 "IBUS1, cyclic every 10 ms, sent by GW";
CM_ SG_ 372 TBOX_174_CheckSum "TBOX_174_message checksum (E2E Data ID: 0x66)";
CM_ SG_ 372 TBOX_174_AliveCounter "TBOX_174_message counter";
CM_ SG_ 372 TBOX_XAcce "X Acceleration";
CM_ SG_ 372 TBOX_XVelocity "X Velocity";
CM_ SG_ 372 TBOX_XAgrRate "X Angular Rate";
CM_ BO_ 372 "IBUS1, cyclic every 100 ms, sent by GW";
CM_ SG_ 373 TBOX_175_CheckSum "TBOX_175_message checksum (E2E Data ID: 0x67)";
CM_ SG_ 373 TBOX_175_AliveCounter "TBOX_175_message counter";
CM_ SG_ 373 TBOX_YAcce "Y Acceleration";
CM_ SG_ 373 TBOX_YVelocity "Y Velocity";
CM_ SG_ 373 TBOX_YAgrRate "Y Angular Rate";
CM_ BO_ 373 "IBUS1, cyclic every 100 ms, sent by GW";
CM_ SG_ 374 TBOX_176_CheckSum "TBOX_176_message checksum (E2E Data ID: 0x64)";
CM_ SG_ 374 TBOX_176_AliveCounter "TBOX_176_message counter";
CM_ SG_ 374 TBOX_ZAcce "Z Acceleration";
CM_ SG_ 374 TBOX_ZVelocity "Z Velocity";
CM_ SG_ 374 TBOX_ZAgrRate "Z Angular Rate";
CM_ BO_ 374 "IBUS1, cyclic every 100 ms, sent by GW";
CM_ SG_ 377 TBOX_179_CheckSum "TBOX_179_message checksum (E2E Data ID: 0x6B)";
CM_ SG_ 377 TBOX_179_AliveCounter "TBOX_179_message counter";
CM_ SG_ 377 TBOX_Heading "Vehicle heading";
CM_ SG_ 377 TBOX_HeadingStdDev "Vehicle heading Std Dev";
CM_ BO_ 377 "IBUS1, cyclic every 100 ms, sent by GW";
CM_ SG_ 440 ESP_1B8_CheckSum "ESP _1B8_Message checksum (E2E data ID: 0xC1)";
CM_ SG_ 440 ESP_1B8_AliveCounter "EP_1B8_Message counterESP_1B8_AliveCounter";
CM_ SG_ 440 ESP_ModFbSig "ESP mode feedback signal ESP mode feedback signal";
CM_ SG_ 440 ESP_ModSwtAllw "Whether ESP allows switching mode ESP Special terrain mode switch allowed";
CM_ SG_ 440 ESP_ActvVehHldFlg "ESP actively builds the brake stop vehicle flag position Flag whether the vehicle is actively held by ESP pressure built up.";
CM_ SG_ 440 ESP_VehSecuCdn "Vehicle safety condition .Indicates security states when request security condition.";
CM_ SG_ 440 ESP_BrkFStsFlg "Whether ESP has brake force Flag whether ESP there is brake force present.";
CM_ SG_ 440 ESP_CddApOpsDirMovmt "CDD_AP flag for identification of opposite direction motion Flag whether CDDAP recognises an opposite direction movement.";
CM_ SG_ 440 ESP_VehStopSts "Vehicle stop signal (fully stationary)Flag whether vehicle is in stop.";
CM_ SG_ 440 ESP_VehStandstillSts "Vehicle stop signal (v < 3 km/h)flag whether vehicle is in standstill.";
CM_ SG_ 440 ESP_RoadSlopVld "Whether the slope signal is Valid";
CM_ SG_ 440 ESP_AEBRdy "AEB ready status signal from ESP";
CM_ SG_ 440 ESPACCRdy "ACC ready status signal from ESP";
CM_ SG_ 440 ESP_ParkRdy "Park ready status signal from ESP";
CM_ SG_ 440 ESP_ReAEBRdy "ReAEB ready status signal from ESP";
CM_ SG_ 440 ESP_SpclTerrainModFltIndcn "ESP all-terrain mode fault indication ATM Available";
CM_ SG_ 440 ESP_DrvOffStRdy "Does the drive off flag be supported in the current LSMLSM confirmation that all conditions are fullfilled to support parking maneuver";
CM_ SG_ 440 ESP_TarLSMSts "LSM status of ESP request";
CM_ SG_ 440 ESP_RoadSlop "Road gradient";
CM_ BO_ 440 "IBUS1, cyclic every 20 ms, sent by GW";
CM_ SG_ 450 EPS_1C2_CheckSum "EPS_1C2_Message check ( E2E data ID: 0x90)";
CM_ SG_ 450 EPS_1C2_AliveCounter "EP_1C2 _Message counterEPS_1C2_AliveCounter";
CM_ SG_ 450 EPS_AbortFb "EPS control interruption reason";
CM_ SG_ 450 EPS_SteerWhlAgSig "Steering wheel angle signal (counterclockwise as positive, clockwise as negative)Steering wheel angle left is positive, right is negative.";
CM_ SG_ 450 EPS_SteerAgSnsrCalSts "Calibration state of rotation angle sensor SAS Calibration status.";
CM_ SG_ 450 EPS_SteerWhlAgSigVld "Effective bit of steering wheel angle signal indicate Steer Wheel Angle signal valid or not.";
CM_ SG_ 450 EPS_SteerWhlRotSpdDir "Steering wheel speed direction Rotation speed direction of the steering wheel.";
CM_ SG_ 450 EPS_SteerWhlRotSpdVld "Effective Position of Steering Wheel Speed";
CM_ SG_ 450 EPS_AdasLatCtrlSts "EPS system available state Electrical Power Steering Available Status.";
CM_ SG_ 450 EPS_AdasLatCtrlStsVld "EPS system available state Electrical Power Steering Available valid Status.";
CM_ SG_ 450 EPS_SteerWhlRotSpd "Steering wheel speed (counterclockwise is positive, clockwise is negative)Rotation speed of the steering wheel.";
CM_ SG_ 450 EPS_AsscMotCrtTq "Current torque of EPS booster motor";
CM_ BO_ 450 "IBUS1, cyclic every 10 ms, sent by GW";
CM_ SG_ 552 MCU_F_228_CheckSum "checksum(E2E data ID: 0x85)";
CM_ SG_ 552 MCU_F_228_AliveCounter "MCU_xx_Message Counter FrontMCU_F_xxxAliveCounter";
CM_ SG_ 552 MCU_F_BoostEnStat "Status indicator on boost mode enable";
CM_ SG_ 552 MCU_F_ActDampStat "Active damping state";
CM_ SG_ 552 MCU_F_OTARdy_Fb "MCU_F OTA ready status feedback";
CM_ SG_ 552 MCU_F_BoostModActCounter "Counter on boost mode activations";
CM_ SG_ 552 MCU_F_ActSafeSt "Actual safe state from MCU_F";
CM_ SG_ 552 MCU_F_ActDampTq "Active damping torque";
CM_ SG_ 552 MCU_F_PhaCrt "Front drive motor phase current (effective value)MotorFPhasecurrent";
CM_ BO_ 552 "IBUS1, cyclic every 10 ms, sent by GW";
CM_ SG_ 553 MCU_R_229_CheckSum "checksum(E2E data ID: 0x86)";
CM_ SG_ 553 MCU_R_229_AliveCounter "MCU_xx_Message Counter FrontMCU_R_xxxAliveCounter";
CM_ SG_ 553 MCU_R_BoostEnStat "Status indicator on boost mode enable";
CM_ SG_ 553 MCU_R_ActDampStat "Active damping state";
CM_ SG_ 553 MCU_R_OTARdy_Fb "MCU_R OTA ready status feedback";
CM_ SG_ 553 MCU_R_BoostModActCounter "Counter on boost mode activations";
CM_ SG_ 553 MCU_R_ActSafeSt "Actual safe state from MCU_R";
CM_ SG_ 553 MCU_R_ActDampTq "Active damping torque";
CM_ SG_ 553 MCU_R_PhaCrt "Rear drive motor phase current (effective value)MotorFPhasecurrent";
CM_ BO_ 553 "IBUS1, cyclic every 10 ms, sent by GW";
CM_ SG_ 564 VCU_214_234_CheckSum "VCU_214_Message checksum (E2E data ID: 0x12)";
CM_ SG_ 564 VCU_214_234_AliveCounter "VCU_214_Packet counterVCU_214_AliveCounter";
CM_ SG_ 564 VCU_RdyLamp "READY lamp";
CM_ SG_ 564 VCU_BrkLampCtrlSts "Stop lamp control state";
CM_ SG_ 564 VCU_RemWakeUpEndFlg "Terminal wake-up end flag bit";
CM_ SG_ 564 VCU_StgyGearSig "Strategy gear signal";
CM_ SG_ 564 VCU_ShiftMisoper "Gear misoperation";
CM_ SG_ 564 VCU_GearSigVld "Effective bit of gear signal";
CM_ SG_ 564 VCU_GearSig "Gear signal";
CM_ SG_ 564 VCU_ACCRdy "ACC ready signal from VCU";
CM_ SG_ 564 VCU_ParkRdy "Park ready signal from VCU";
CM_ SG_ 564 VCU_APSPercVld "Effective position of accelerator pedal opening";
CM_ SG_ 564 VCU_VehSt "State of complete vehicle";
CM_ SG_ 564 VCU_APSPerc "Accelerator pedal opening";
CM_ SG_ 564 VCU_BrkSig "Brake signal";
CM_ SG_ 564 VCU_BrkSigVld "Effective bit of brake signal";
CM_ SG_ 564 VCU_DrvModSigFb "Driving mode signal feedback to ICC";
CM_ SG_ 564 VCU_DrvModShiftMisoper "Driving mode switching error operation";
CM_ SG_ 564 VCU_SpclTerrainModEnaSig "All-terrain driving mode enable signal";
CM_ BO_ 564 "IBUS1, cyclic every 10 ms, sent by GW";
CM_ SG_ 616 ESP_268_CheckSum "ESP_268_Message checksum ( E2E data ID: 0x7B)";
CM_ SG_ 616 ESP_268_AliveCounter "EP_268 _Message counterESP_268_AliveCounter";
CM_ SG_ 616 ESP_DynoModSts "Status signal of Dyno Mode";
CM_ SG_ 616 ESP_SysSts_EPB "EPB stateStatus of EPB system.";
CM_ SG_ 616 ESP_FltIndcn_EPB "EPB system error indicationindicating EPB is available or not.";
CM_ SG_ 616 ESP_Actvndcn_EPB "EPB operation indicationIndicating the working state of EPB funtion.";
CM_ SG_ 616 EPB_WarnMsg01 "Prompt information to inform the driver of the next operationAdditional warning message to inform the driver how to do the next step.";
CM_ SG_ 616 EPB_WarnMsg02 "Prompt message to inform the driver of the next operation, the seat belt is not fastened or the door is not closedAdditional warning message to inform the driver how to do the next step when seatbelt not attached or the door not closed.";
CM_ SG_ 616 ESP_YawRateStabnAvl "Lateral stability signal (whether the lateral stability of the needle is available.If 0x0: None, the needle lateral VMC function is not available)";
CM_ SG_ 616 EPB_WarnMsg04 "Prompt message to inform the driver of the next operation, and the parking gradient exceeds the thresholdAdditional warning message to inform the driver to park the car on the slope with gentle incline.";
CM_ SG_ 616 ESP_EPBSwtichPosition "EPB switch state";
CM_ SG_ 616 ESP_EPBSwtichPositionValid "Effective bit of EPB switch state";
CM_ BO_ 616 "IBUS1, cyclic every 20 ms, sent by GW";
CM_ SG_ 627 TBOX_V2L_TrEna "TBOX_V2LTrunkEnable";
CM_ SG_ 627 TBOX_V2L_ChrgPortEna "TBOX_V2LChargePortEnable";
CM_ SG_ 627 TBOX_V2V_Ena "TBOX_V2VEnable";
CM_ SG_ 627 TBOX_V2H_Ena "TBOX_V2HEnable";
CM_ SG_ 627 TBOX_V2G_Ena "TBOX_V2GEnable";
CM_ BO_ 627 "IBUS1, NoMsgSendType, sent by GW";
CM_ BO_ 649 "IBUS1, cyclic every 200 ms, sent by GW";
CM_ SG_ 673 SCM_0x2A1_CheckSum "SCM_2A1_Message checksum (E2E data ID: 0xF2)";
CM_ SG_ 673 SCM_0x2A1_AliveCounter "SCM_2A1_Message counterSCM_2A1_AliveCounter";
CM_ SG_ 673 SCM_SuspFb "Suspension set feedback";
CM_ SG_ 673 SCM_OTARdy_Fb "SCM OTA ready status feedback";
CM_ SG_ 673 SCM_Err_sts "SCM error status";
CM_ BO_ 673 "IBUS1, cyclic every 50 ms, sent by GW";
CM_ SG_ 684 IBS_StateOfCharge "State of Charge";
CM_ SG_ 684 IBS_StateOfHealth "State of Health, age of battery";
CM_ SG_ 684 IBS_EstVoltaDrop "State of Function, predicted battery voltage for next crank";
CM_ SG_ 684 IBS_OptChargeVolt "Recommended charge voltage for battery";
CM_ SG_ 684 IBS_AvgRi "Average of internal resistance";
CM_ BO_ 684 "IBUS1, cyclic every 100 ms, sent by GW";
CM_ SG_ 743 ECC_CooltLvlWarn "Coolant level Warning to HMI";
CM_ BO_ 743 "IBUS1, cyclic every 100 ms, sent by GW";
CM_ SG_ 756 BMS_Bat_measure_Coulomb_Ctr "measured values [As]";
CM_ SG_ 756 BMS_Bat_measure_Energy "measured values IVT [Wh]";
CM_ SG_ 756 BMS_Bat_measure_Power "measured values IVT [KW]";
CM_ SG_ 756 BMS_Bat_Bus_measure_Temperature "measured valuesIVT";
CM_ BO_ 756 "IBUS1, cyclic every 100 ms, sent by GW";
CM_ SG_ 757 BMS_Bat_SoC_usable "Usable SoC value output [%]";
CM_ SG_ 757 BMS_Bat_Actual_Pack_Capacity "Actual system capacity [kWh]";
CM_ SG_ 757 BMS_Bat_SOH "Actual aging [%]";
CM_ SG_ 757 BMS_Bat_SOC_Real "Real SOC of HV battery (%)";
CM_ BO_ 757 "IBUS1, cyclic every 100 ms, sent by GW";
CM_ SG_ 767 VCU_2FF_CheckSum "VCU_2FF_Message checksum (0xE7)VCU_2FF_CheckSum";
CM_ SG_ 767 VCU_2FF_AliveCounter "VCU_0x139_AliveCounter";
CM_ SG_ 767 VCU_WrkShpModFB "Workshop Mode Feedback from VCU";
CM_ SG_ 767 VCU_ACC_PA_MinA "VCU minimum acceleration for ACC and parking functions";
CM_ SG_ 767 VCU_ACC_PA_MaxA "VCU maximum acceleration for ACC and parking functions";
CM_ SG_ 767 VCU_WrkShpModAvlbSts "Workshop Mode Availability Status from VCU";
CM_ BO_ 767 "IBUS1, cyclic every 100 ms, sent by GW";
CM_ SG_ 783 ICC_QuickBootMode "ICC to send VCU to enable quick boot mode where ICC does not power down, but just turns the screen blank.";
CM_ BO_ 783 "IBUS1, cyclic every 1000 ms, sent by ICC";
CM_ SG_ 792 ESP_318_CheckSum "ESP318_Message Checksum ( E2E data ID: 0x79)";
CM_ SG_ 792 ESP_318_AliveCounter "ESP 3318_Message counterESP_318_AliveCounter";
CM_ SG_ 792 ESP_BrkPedlStsVld "Effective position of brake pedal state validity of BRAKE_STATUS_ESP.";
CM_ SG_ 792 ESP_BrkPedlSts "Brake pedal state indicating brake pedal activated by driver or not.";
CM_ SG_ 792 ESP_VehSpdVld "ABS_ESC signal indicates whether the vehicle speed is valid When the diagnostic have set the failure code on this signal the value wil be 2.";
CM_ SG_ 792 ESP_SysActv "ESP works effectively Is used to indicate to the driver that the system is currently active. Not used for ABS.";
CM_ SG_ 792 ESP_LampSwtOffIndcn "ESP OFF indication Signal indicates to light up 'TCS/ESP off' lamp.-manual switch off of ESP function (on/off switch).Not used for ABS.";
CM_ SG_ 792 ESP_FltIndcn_EBD "EBD fault indication Signal indicates to light up EBD lamp.";
CM_ SG_ 792 ESP_FltIndcn_ABS "ABS fault indication Signal indicates to light up ABS lamp.";
CM_ SG_ 792 ESP_MilgRollgCntr_ODO "Mileage statistical pulse Odometer rolling count 1 pulse/bit. The value shall be set to zero at every ignition off and if the counter reach max value it starts from zero again.";
CM_ SG_ 792 ESP_VehSpd "Speed signal";
CM_ SG_ 792 ESP_IninModSigIndcn "The signal needs to cover the time of ESP and ABS fault signals caused by self-inspection. Signal indicates if ESP or ABS is in initialization mode or not.";
CM_ SG_ 792 ESP_FltIndcn_TCS "ESP/TCS fault indication Signal indicates failure monitoring of ESP function. Not used for ABS";
CM_ SG_ 792 ESP_CtrlSts_HDC "Indicate that the HDC is on/off or working, and the ADAS receives this signal to determine whether the ACC is off. HDC control(Off/On, not active braking/On, active braking).";
CM_ SG_ 792 ESP_AvlIndcn_HDC "Effective bit of HDC indicating HDC is available or not.";
CM_ SG_ 792 ESP_NoBrkP "When the vehicle is stationary, whether the function has braking force or not, whether it is braking.no brake pressure applied; generally it regards wheel cylinder presure.";
CM_ SG_ 792 ESP_RDAEnaFlg "ESP remote driving function enable flag position";
CM_ BO_ 792 "IBUS1, cyclic every 20 ms, sent by GW";
CM_ BO_ 797 "IBUS1, NoMsgSendType, sent by ICC";
CM_ BO_ 799 "IBUS1, cyclic every 200 ms, sent by ICC";
CM_ BO_ 809 "IBUS1, NoMsgSendType, sent by ICC";
CM_ SG_ 812 ICC_SchedUpdate_Selection "64 bit signed integer representing Unix epoch time (number of seconds since 01/01/1970)";
CM_ BO_ 812 "IBUS1, NoMsgSendType, sent by ICC";
CM_ SG_ 819 BCM_333_CheckSum "BCM333_message checksum ( 0xCB)BCM_333_CheckSum";
CM_ SG_ 819 BCM_333_AliveCounter "BCM333_Packet counterBCM_333_AliveCounter";
CM_ SG_ 819 BCM_KL15_Off_Announcement "Before switching off the KL15 (5s), this signal gets active to inform other ECUs that the KL15 will be disabled in 5seconds if there are still no triggers to keep it active";
CM_ SG_ 819 BCM_IG1Sts "IG1 state";
CM_ SG_ 819 BCM_PwrMod "Power mode";
CM_ SG_ 819 BCM_PwrModVld "Effective value of power mode";
CM_ SG_ 819 BCM_BrkSwtSts "Brake switch status";
CM_ SG_ 819 BCM_IG1StsVld_CAPE "Effective value of IG1 state";
CM_ SG_ 819 BCM_IG2StsVld_CAPE "Effective value of IG2 state";
CM_ SG_ 819 BCM_KL30s_L "Logical State of KL30";
CM_ SG_ 819 BCM_IG2Sts "IG2 state";
CM_ SG_ 819 BCM_InteriorSwtSt "Interior switch status from LIN1";
CM_ BO_ 819 "IBUS1, cyclic every 50 ms, sent by GW";
CM_ SG_ 821 BCM_335_CheckSum "BCM_335_Message checksum ( 0xD4)BCM_335_CheckSum";
CM_ SG_ 821 BCM_335_AliveCounter "BC_335_Message counterBCM_335_AliveCounter";
CM_ SG_ 821 BCM_WiprInSrvPosn "Whether the electronic wiper is in the service position";
CM_ SG_ 821 BCM_IntLampTiSetSts "Central control interior lamp door control delay time setting state";
CM_ SG_ 821 BCM_WaterPosnSnsrSwtSts "Condition of level sensor switch";
CM_ SG_ 821 BCM_FrntFogLampOutpCmd "Front fog lamp output command";
CM_ SG_ 821 BCM_LicPlateLampOutpCmd "License plate lamp output command";
CM_ SG_ 821 BCM_EnaSts_ADB "ADB enable";
CM_ SG_ 821 BCM_PwrSaveOutpCmd "Power saving output command";
CM_ SG_ 821 BCM_ExtLampSwtSts "Outside lamp switch status";
CM_ SG_ 821 BCM_HornOutpCmd "Horn output command";
CM_ SG_ 821 BCM_HornSwtSts "Horn switch state";
CM_ SG_ 821 BCM_WelLampOutpCmd "Approach lamp output command";
CM_ SG_ 821 BCM_FolwMeHomeSts "Follow me home state";
CM_ SG_ 821 BCM_FrntFogLampSwtSts "Front fog lamp switch state";
CM_ SG_ 821 BCM_ReFogLampSwtSts "Rear fog lamp switch state";
CM_ SG_ 821 BCM_ReWiprBackSwtSts "State of rear wiper return switch";
CM_ SG_ 821 BCM_RainClsSunroofSetSts "Central control screen closing sunroof setting state in rainy days";
CM_ SG_ 821 BCM_MirrLockAutoSetSts "Central control rearview mirror locking automatic folding setting state";
CM_ SG_ 821 BCM_FrntWshrOutpCmd "Front washing output command";
CM_ SG_ 821 BCM_DangerAlrmLampSwtSts "Hazard warning lamp switch state";
CM_ SG_ 821 BCM_ReDefrstHeatgCmd "Rear defrosting heating command";
CM_ SG_ 821 BCM_RvsLampOutpCmd "Reverse lamp output command";
CM_ SG_ 821 BCM_IntLampOutpCmd "Output state of internal lamp";
CM_ SG_ 821 BCM_LeTrunLampOutpCmd "Left turn signal lamp output command";
CM_ SG_ 821 BCM_RiTrunLampOutpCmd "Right turn signal lamp output command";
CM_ SG_ 821 BCM_ReWiprOutpCmd "Rear wiper output command";
CM_ SG_ 821 BCM_ReWshrOutpCmd "Rear washer output command";
CM_ SG_ 821 BCM_BrkLampSwtSts "Brake lamp switch state";
CM_ SG_ 821 BCM_HiBeamOutpCmd "High beam output command";
CM_ SG_ 821 BCM_LoBeamOutpCmd "Low beam output command";
CM_ SG_ 821 BCM_PosnLampOutpCmd "Position lamp output command";
CM_ SG_ 821 BCM_BrkLampOutpCmd "Brake lamp output command";
CM_ SG_ 821 BCM_ReFogLampOutpCmd "Rear fog lamp output command";
CM_ SG_ 821 BCM_FrntWiprSpd "Front wiper speed";
CM_ SG_ 821 BCM_EnaReq_ADB "ADB enable state feedback";
CM_ SG_ 821 BCM_VehAmbBri "Ambient light detection value output";
CM_ BO_ 821 "IBUS1, cyclic every 50 ms, sent by GW";
CM_ SG_ 822 ICC_336_Checksum "EHU336_Message checksum ( 0xE5)EHU_336_Checksum";
CM_ SG_ 822 ICC_336_AliveCounter "EHU336_Message CounterEHU_336_AliveCounter";
CM_ SG_ 822 ICC_SetAtmLampBri "Set the ambient light brightness";
CM_ SG_ 822 ICC_SuspSet "Suspension set";
CM_ SG_ 822 ICC_AtmLampOpenCmd "Atmosphere lamp opening command";
CM_ SG_ 822 ICC_SteerAssiSet "Steering Assist set";
CM_ SG_ 822 ICC_SetStorageBriLvl "Set brightness of storage lights";
CM_ SG_ 822 ICC_HDCSwtSig "HDC switch signalHDC switch, pressed or not.";
CM_ SG_ 822 ICC_ESPSwtSig "ESP switch signalESP switch, pressed or not.";
CM_ SG_ 822 ICC_ReqCalifModHMIBtn "California HMI button";
CM_ SG_ 822 ICC_SpdLimOffs "Speed limit deviation (reserved)";
CM_ SG_ 822 ICC_iTPMSResetSig "iTPMS reset signal";
CM_ SG_ 822 ICC_WIFIOnOffSig "Send WIFI ON/OFF signal to TBOX";
CM_ SG_ 822 ICC_LeMirrAlrmLampFlt "Left reflector warning lamp fault";
CM_ SG_ 822 ICC_RiMirrAlrmLampFlt "Right reflector warning lamp fault";
CM_ SG_ 822 ICC_PhoneSt "Phone is being usedPhone status";
CM_ SG_ 822 ICC_SpeechSt "Speech statusIndication of someone talking to a vehicle application, like navigation.";
CM_ SG_ 822 ICC_RemReqFb "Feeback signal to TBOX_RemSWH_Req from ICC to TBOX";
CM_ SG_ 822 ICC_SpdLimFdb "Feeback signal to TBOX_SpdLim from ICC to TBOX";
CM_ SG_ 822 ICC_OTARdy_Fb "ICC OTA ready status feedback";
CM_ BO_ 822 "IBUS1, cyclic every 100 ms, sent by ICC";
CM_ SG_ 823 OHC_FctCrtSts "Current status of ambient light function";
CM_ SG_ 823 OHC_CrtGroup4RearComp "Current state of rear compartment light";
CM_ SG_ 823 OHC_SplyGroup5OutpSts "Output state of reading light power supply";
CM_ SG_ 823 OHC_CrtGroup3Storage "Storage light current status";
CM_ SG_ 823 OHC_CrtGroup1Standard "Ambient light current status";
CM_ SG_ 823 OHC_CrtGroup2Footwell "Footwell light current status";
CM_ SG_ 823 OHC_CrtBri "Current brightness of ambient light";
CM_ BO_ 823 "IBUS1, cyclic every 100 ms, sent by GW";
CM_ SG_ 835 BCM_343_CheckSum "BCM3343_Message checksum ( 0xD7)BCM_343_CheckSum";
CM_ SG_ 835 BCM_343_AliveCounter "BCM3343_Message counterBCM_343_AliveCounter";
CM_ SG_ 835 BCM_RemReqFb "Remote request feedback";
CM_ SG_ 835 BCM_APASwSts "APA switch state";
CM_ SG_ 835 BCM_FrntHoodLidSts "Status of front engine hood";
CM_ SG_ 835 BCM_SunroofAntipinchSts "Sunroof anti-pinch state";
CM_ SG_ 835 BCM_FrntDrDoorLockSts "Driver door lock state";
CM_ SG_ 835 BCM_TrRelsSwtSts "State of micro switch of tail gate";
CM_ SG_ 835 BCM_LockAllDoorCmd "Four door locking output command";
CM_ SG_ 835 BCM_DrFrntDoorSts "Lock StATUS driver Door used as central lock information";
CM_ SG_ 835 BCM_PasFrntDoorSts "Lock Status Passinger Front Door used as central lock information";
CM_ SG_ 835 BCM_AntithftSts "Body anti-theft state";
CM_ SG_ 835 BCM_CenLockSwtSts "Central control lock switch state";
CM_ SG_ 835 BCM_DoorUnlockSetFb "Door unlocking setting feedback";
CM_ SG_ 835 BCM_RiReDoorSts "State of RR door";
CM_ SG_ 835 BCM_LeReDoorSts "State of left rear door";
CM_ SG_ 835 BCM_LeFrntWinSts "Opening and closing state of left front window";
CM_ SG_ 835 BCM_RiFrntWinSts "Opening and closing state of right front window";
CM_ SG_ 835 BCM_LeReWinSts "Opening and closing state of left rear window";
CM_ SG_ 835 BCM_RiReWinSt "Opening and closing state of right rear window";
CM_ SG_ 835 BCM_SunroofSts "Opening and closing status of sunroof";
CM_ SG_ 835 BCM_FolwMeSetStsFb "Follow me home setting status feedback";
CM_ SG_ 835 BCM_DrvrDoorUnlckOutpCmd "Driver door unlocking output command";
CM_ SG_ 835 BCM_PassDoorUnlckOutpCmd "Passenger door unlocking output command";
CM_ SG_ 835 BCM_LeDRLOutpCmd "Left daytime running lamp output command";
CM_ SG_ 835 BCM_RiDRLOutpCmd "Right daytime running lamp output command";
CM_ SG_ 835 BCM_ArmedClsWinSetSts "Central control screen control window setting state";
CM_ SG_ 835 BCM_OffAutoUnlckSetSts "Automatic unlocking setting state of central control flameout";
CM_ SG_ 835 BCM_WarnVbrnSts "BCM vibration alarm activated state";
CM_ SG_ 835 BCM_SunroofPosnInfo "Sunroof opening information";
CM_ SG_ 835 BCM_SunroofOpenAr "Sunroof opening area";
CM_ SG_ 835 BCM_SteerWhlVbrnAlrmAvl "Whether steering wheel vibration alarm is available";
CM_ SG_ 835 BCM_SunroofRunngSts "Sunroof operation state";
CM_ SG_ 835 BCM_MirrCmd "Exterior rearview mirror control";
CM_ BO_ 835 "IBUS1, cyclic every 50 ms, sent by GW";
CM_ SG_ 840 TRM_348_CheckSum "TRM_348_Message Verification ( 0xF7)TRM_348_CheckSum";
CM_ SG_ 840 TRM_348_AliveCounter "TRM_348_AliveCounter";
CM_ SG_ 840 TRM_OTARdy_Fb "TRM OTA ready status feedback";
CM_ SG_ 840 TRM_TrailerSts "Trailer status";
CM_ SG_ 840 TRM_WakeupSrc "Wakeup source";
CM_ SG_ 840 TRM_IndcrLeSts "Indicator left status";
CM_ SG_ 840 TRM_IndcrRiSts "Indicator right status";
CM_ SG_ 840 TRM_TailLiLeSts "Tail light left status";
CM_ SG_ 840 TRM_TailLiRiSts "Tail light right status";
CM_ SG_ 840 TRM_StopLiSts "Stop light status";
CM_ SG_ 840 TRM_RvsSts "Reverse status";
CM_ SG_ 840 TRM_FogLiSts "Fog light status";
CM_ SG_ 840 TRM_HitchSts "Hitch status";
CM_ BO_ 840 "IBUS1, cyclic every 100 ms, sent by GW";
CM_ SG_ 852 MCU_R_354_CheckSum "MCU_R_354_Message checksum(E2E data ID: 0xB4)";
CM_ SG_ 852 MCU_R_354_AliveCounter "Rear MCU life signal";
CM_ SG_ 852 MCU_R_ReqZeroTqFlg "Rear MCU request zero torque flag bit";
CM_ SG_ 852 MCU_R_CrtSts "Current state of rear drive motorMotorRState";
CM_ SG_ 852 MCU_R_MaxPwrGennTq "Maximum braking torque of rear drive motorMotorRMaximumGeneratingTorque.";
CM_ SG_ 852 MCU_R_MaxElecTq "Maximum driving torque of rear drive motorMotorRMaximumMotoringTorque.";
CM_ SG_ 852 MCU_R_MOT_T "Temperature of rear drive motor";
CM_ SG_ 852 MCU_R_IGBTT "Rear MCU IGBT temperatureMCURIGBTTemperature.";
CM_ BO_ 852 "IBUS1, cyclic every 10 ms, sent by GW";
CM_ SG_ 853 MCU_F_355_CheckSum "MCU_F_355_Message checksum(E2E data ID: 0xB5)";
CM_ SG_ 853 MCU_F_355_AliveCounter "Front MCU life signal";
CM_ SG_ 853 MCU_F_ReqZeroTqFlg "Front MCU request zero torque flag";
CM_ SG_ 853 MCU_F_CrtSts "Current state of front drive motorMotorFState";
CM_ SG_ 853 MCU_F_MaxPwrGennTq "Maximum braking torque of front drive motorMotorFMaximumGeneratingTorque.";
CM_ SG_ 853 MCU_F_MaxElecTq "Maximum driving torque of front drive motorMotorFMaximumMotoringTorque.";
CM_ SG_ 853 MCU_F_MOT_T "Temperature of front drive motorMotorFTemerature.";
CM_ SG_ 853 MCU_F_IGBTT "Front MCU IGBT temperatureMCUFIGBTTemperature.";
CM_ BO_ 853 "IBUS1, cyclic every 10 ms, sent by GW";
CM_ SG_ 856 VCU_358_CheckSum "VCU_0x358_Message Check (E2E data ID: 0x47)";
CM_ SG_ 856 VCU_358_AliveCounter "VCU_0x358_Message counter";
CM_ SG_ 856 VCU_KickdwnFlg "status of kickdown function";
CM_ SG_ 856 VCU_EPedlEnaSig "E-Pedal enable signal (TBD if required)";
CM_ SG_ 856 VCU_ComLostFlt_ESP "VCU and ESP communication related faults";
CM_ SG_ 856 VCU_ComFlt_iBooster "VCU and iBooster communication failure_U101587_E03";
CM_ SG_ 856 VCU_RegenLvlFb "Coasting Mode settings (Off, Normal, high) feedback to ICC";
CM_ SG_ 856 VCU_AccelModFb "Acceleration Mode setting (Low/Mid/High) feedback to ICC";
CM_ SG_ 856 VCU_EPedlStsFb "Pedal Comport Setting (One Pedal Drive / Roll / Creep) feedback to ICC";
CM_ SG_ 856 VCU_CcTrgSpdDisp "Cruise Control Target Speed display";
CM_ SG_ 856 VCU_Sts_CC_ICC "ACC status";
CM_ SG_ 856 VCU_CCIconDisp "ACC icon color";
CM_ SG_ 856 VCU_DispSpdUnit_CC "CC display speed unit";
CM_ SG_ 856 VCU_BoostEnStat "Boost Enable Status";
CM_ SG_ 856 VCU_OTARdy_Fb "VCU OTA ready status feedback";
CM_ SG_ 856 VCU_OTA_ECUInhb_Req "VCU OTA inhibit request to ECUs";
CM_ SG_ 856 VCU_OTAVehCdnChk_ASIL "ASIL A group OTA vehicle condition check status";
CM_ SG_ 856 VCU_OTAVehInhb_ASIL_Fb "ASIL A group OTA vehicle Inhibit feedback";
CM_ BO_ 856 "IBUS1, cyclic every 100 ms, sent by GW";
CM_ SG_ 868 BCM_364_CheckSum "BCM_364_Message checksum (0xD3)BCM_364_CheckSum";
CM_ SG_ 868 BCM_364_AliveCounter "BCM_364_Message counterBCM_364_AliveCounter";
CM_ SG_ 868 BCM_OTARdy_Fb "BCM OTA ready status feedback";
CM_ SG_ 868 BCM_SBRMatStPass "SBR mat state of the passenger seat";
CM_ SG_ 868 BCM_BucSwtSt2ndRowLeft "Buckle switch state 2nd row left";
CM_ SG_ 868 BCM_BucSwtSt2ndRowMid "Buckle switch state 2nd row mid";
CM_ SG_ 868 BCM_BucSwtSt2ndRowRight "Buckle switch state 2nd row right";
CM_ SG_ 868 BCM_BucSwtSt3rdRowLeft "Buckle switch state 3rd row left";
CM_ SG_ 868 BCM_BucSwtSt3rdRowRight "Buckle switch state 3rd row right";
CM_ SG_ 868 BCM_SBRMatSt2ndRowLeft "SBR mat state 2nd row left";
CM_ SG_ 868 BCM_SBRMatSt2ndRowMid "SBR mat state 2nd row mid";
CM_ SG_ 868 BCM_SBRMatSt2ndRowRight "SBR mat state 2nd row right";
CM_ SG_ 868 BCM_SBRMat3rdRowLeft "SBR mat state 3rd row left";
CM_ SG_ 868 BCM_SBRMat3rdRowRight "SBR mat state 3rd row right";
CM_ BO_ 868 "IBUS1, cyclic every 100 ms, sent by GW";
CM_ SG_ 871 PKC_PhnPairQR_1 "Phone paring via QR code, signal 1";
CM_ SG_ 871 PKC_PhnPairQR_2 "Phone paring via QR code, signal 2";
CM_ SG_ 871 PKC_PhnPairQR_3 "Phone paring via QR code, signal 3";
CM_ SG_ 871 PKC_PhnPairQR_4 "Phone paring via QR code, signal 4";
CM_ SG_ 871 PKC_PhnPairQR_5 "Phone paring via QR code, signal 5";
CM_ SG_ 871 PKC_PhnPairQR_6 "Phone paring via QR code, signal 6";
CM_ SG_ 871 PKC_PhnPairQR_7 "Phone paring via QR code, signal 7";
CM_ SG_ 871 PKC_PhnPairQR_8 "Phone paring via QR code, signal 8";
CM_ BO_ 871 "IBUS1, NoMsgSendType, sent by GW";
CM_ SG_ 872 PKC_PhnPairQR_9 "Phone paring via QR code, signal 9";
CM_ SG_ 872 PKC_PhnPairQR_10 "Phone paring via QR code, signal 10";
CM_ SG_ 872 PKC_PhnPairQR_11 "Phone paring via QR code, signal 11";
CM_ SG_ 872 PKC_PhnPairQR_12 "Phone paring via QR code, signal 12";
CM_ SG_ 872 PKC_PhnPairQR_13 "Phone paring via QR code, signal 13";
CM_ SG_ 872 PKC_PhnPairQR_14 "Phone paring via QR code, signal 14";
CM_ SG_ 872 PKC_PhnPairQR_15 "Phone paring via QR code, signal 15";
CM_ SG_ 872 PKC_PhnPairQR_16 "Phone paring via QR code, signal 16";
CM_ BO_ 872 "IBUS1, NoMsgSendType, sent by GW";
CM_ SG_ 883 ECC_CrtSts "ECC current state";
CM_ SG_ 883 ECC_IninSts "ECC initialization state";
CM_ SG_ 883 ECC_PwrSysHeatMngtSts "Power system thermal management state";
CM_ SG_ 883 ECC_ACSts "A/C state";
CM_ SG_ 883 ECC_AirClnSts "Air purification state";
CM_ SG_ 883 ECC_WindSpdSts "Wind speed state";
CM_ SG_ 883 ECC_BackRowAirOutlModSts "Rear exhaust mode state";
CM_ SG_ 883 ECC_DrvrTSetSts "Main driving temperature setting state";
CM_ SG_ 883 ECC_PassTSetSts "Temperature setting state of front passenger";
CM_ SG_ 883 ECC_HeatSts "HEAT state";
CM_ SG_ 883 ECC_AUTOSts "A/C AUTO state";
CM_ SG_ 883 ECC_SYNCSts "SYNC state";
CM_ SG_ 883 ECC_InfoSysWrmColdDisp "Display of heating and cooling degree of entertainment system";
CM_ SG_ 883 ECC_CircSts "Cycle state";
CM_ SG_ 883 ECC_ParticleConcVld "Effective position of particle concentration";
CM_ SG_ 883 ECC_OutdT "Ambient temperature outside the vehicle";
CM_ SG_ 883 ECC_OutdTVld "Effective position of ambient temperature outside vehicle";
CM_ SG_ 883 ECC_MaxFrntDefrst "Max Front defrosting";
CM_ SG_ 883 ECC_HeatMngtSysFlt "Fault of thermal management system";
CM_ SG_ 883 ECC_HeatMngtFctLim "Requirement for Thermal Management Function of Occupant Compartment";
CM_ SG_ 883 ECC_DrvrAirOutlMod "Driver Air Outlet Mode";
CM_ SG_ 883 ECC_PassAirOutlMod "Front passenger air-out mode";
CM_ SG_ 883 ECC_RemSts "Operating status of remote A/C";
CM_ SG_ 883 ECC_OTAInhbRdy "OTA pre-condition and Inhibiting of all OTA relevant ECUs";
CM_ BO_ 883 "IBUS1, cyclic every 100 ms, sent by GW";
CM_ SG_ 888 ECC_MCUFCooltFlow "Front drive motor coolant flow";
CM_ SG_ 888 ECC_MCURCooltFlow "Rear drive motor coolant flow";
CM_ SG_ 888 ECC_LeOutlUpDwnMotActvSts "Operating state of upper/lower motor of left air outlet";
CM_ SG_ 888 ECC_LeOutlLeRiMotActvSts "Operating state of left/right motor of left air outlet";
CM_ SG_ 888 ECC_LeOutlDamprMotActvSts "Operating state of left air vent damper motor";
CM_ SG_ 888 ECC_MidLeOutlUpDwnMotActvSts "Operating state of upper and lower motors at middle left air outlet";
CM_ SG_ 888 ECC_MidLeOutlLeRiMotActvSts "Operating state of left/right motor at middle left air outlet";
CM_ SG_ 888 ECC_MidLeOutlDamprMotActvSts "Operating state of middle left air outlet damper motor";
CM_ SG_ 888 ECC_MidRiOutlUpDwnMotActvSts "Operating state of upper and lower motors of middle right air outlet";
CM_ SG_ 888 ECC_MidRiOutlLeRiMotActvSts "Operating state of left/right motor at middle right air outlet";
CM_ SG_ 888 ECC_MidRiOutlDamprMotActvSts "Operating state of middle right air vent damper motor";
CM_ SG_ 888 ECC_RiOutlUpDwnMotActvSts "Operating state of upper and lower motors of right air outlet";
CM_ SG_ 888 ECC_RiOutlLeRiMotActvSts "Operating state of left/right motor of right air outlet";
CM_ SG_ 888 ECC_RiOutlDamprMotActvSts "Operating state of right air vent damper motor";
CM_ BO_ 888 "IBUS1, cyclic every 100 ms, sent by GW";
CM_ SG_ 890 ICC_LeOutlUpDwnMotActvCmd "Left air outlet upper and lower motor operating instruction";
CM_ SG_ 890 ICC_LeOutlLeRiMotActvCmd "Left/right motor operating command of left air vent";
CM_ SG_ 890 ICC_LeOutlDamprMotActvCmd "Left air vent damper motor operating instruction";
CM_ SG_ 890 ICC_MidLeOutlUpDwnMotActvCmd "Middle left air outlet upper and lower motor operating instruction";
CM_ SG_ 890 ICC_MidLeOutlLeRiMotActvCmd "Middle left air outlet left and right motor action command";
CM_ SG_ 890 ICC_MidLeOutlDamprMotActvCmd "Middle left air vent damper motor operating instruction";
CM_ SG_ 890 ICC_MidRiOutlUpDwnMotActvCmd "Operation command of upper and lower motors of middle right air outlet";
CM_ SG_ 890 ICC_MidRiOutlLeRiMotActvCmd "Middle right air outlet left and right motor action command";
CM_ SG_ 890 ICC_MidRiOutlDamprMotActvCmd "Middle right air vent damper motor operating command";
CM_ SG_ 890 ICC_RiOutlUpDwnMotActvCmd "Right air outlet upper and lower motor operating instructions";
CM_ SG_ 890 ICC_RiOutlLeRiMotActvCmd "Right air vent left and right motor action command";
CM_ SG_ 890 ICC_RiOutlDamprMotActvCmd "Right air vent damper motor operating instruction";
CM_ BO_ 890 "IBUS1, cyclic every 100 ms, sent by ICC";
CM_ SG_ 897 RAC_OnOff "On Off button";
CM_ SG_ 897 RAC_BackRowAirOutlModReq "Rear exhaust mode request";
CM_ SG_ 897 RAC_VolInc "Volume up";
CM_ SG_ 897 RAC_VolDec "Volume reduction";
CM_ SG_ 897 RAC_VolCtrl "Silence control";
CM_ SG_ 897 RAC_TempCtrlnc "Temperature Control increase";
CM_ SG_ 897 RAC_TempCtrDec "Temperature Control decrease";
CM_ SG_ 897 RAC_BlowCtrInc "Blower control increase";
CM_ SG_ 897 RAC_BlowCtrDec "Blower control decrease";
CM_ SG_ 897 RAC_AirOutlLeftBtn "Air Outlet control left button";
CM_ SG_ 897 RAC_AirOutlRightBtn "Air Outlet control right button";
CM_ SG_ 897 RAC_SeatHRearLeftBtn "Seat Heating Button Rear left";
CM_ SG_ 897 RAC_SeatHRearRightBtn "Seat Heating Button Rear right";
CM_ BO_ 897 "IBUS1, cyclic every 100 ms, sent by RAC";
CM_ SG_ 898 BMS_372_382_CheckSum "BMS_372_Message checksum (E2E data ID: 0x1C);";
CM_ SG_ 898 BMS_372_382_AliveCounter "BMS_372 _Message counterBMS_372_AliveCounter";
CM_ SG_ 898 BMS_OTARdy_Fb "BMS OTA ready status feedback";
CM_ SG_ 898 BMS_CellMinT "Minimum temperature of single cell";
CM_ SG_ 898 BMS_CellDiffT "Single cell temperature range";
CM_ SG_ 898 BMS_CellMaxT "Maximum temperature of single cell";
CM_ SG_ 898 BMS_BattAvrgT "Average temperature of battery pack";
CM_ SG_ 898 BMS_PwrBattHeatgMngDmd "Power battery thermal management requirements";
CM_ SG_ 898 BMS_ECCSysAllwDwnPwrCmd "Allowable power reduction instruction of A/C system";
CM_ SG_ 898 BMS_BattInlTDmd "Water inlet temperature requirements of battery pack";
CM_ BO_ 898 "IBUS1, cyclic every 100 ms, sent by GW";
CM_ SG_ 899 MCU_F_383_CheckSum "Message checksum(E2E data ID: 0x28)";
CM_ SG_ 899 MCU_F_383_AliveCounter "AliveCounter";
CM_ SG_ 899 MCU_F_ParkLockStatus_EV "Park lock system status";
CM_ SG_ 899 MCU_F_PrkLckStatNrmlOp_EV "PL engagement status";
CM_ BO_ 899 "IBUS1, cyclic every 100 ms, sent by GW";
CM_ SG_ 900 ICC_PreHeatDepartSet "Preheating depart set";
CM_ SG_ 900 ICC_MonPreHeatDepartSet "Preheating depart set_Monday";
CM_ SG_ 900 ICC_TuePreHeatDepartSet "Preheating depart set_Tuesday";
CM_ SG_ 900 ICC_WedPreHeatDepartSet "Preheating depart set_Wednesday";
CM_ SG_ 900 ICC_ThuPreHeatDepartSet "Preheating depart set_Thursday";
CM_ SG_ 900 ICC_FriPreHeatDepartSet "Preheating depart set_Friday";
CM_ SG_ 900 ICC_SatPreHeatDepartSet "Preheating depart set_Saturday";
CM_ SG_ 900 ICC_SunPreHeatDepartSet "Preheating depart set_Sunday";
CM_ SG_ 900 ICC_PreHeatDepartTi1_Mins "Time for preheating_Minutes";
CM_ SG_ 900 ICC_SchedChargSet "Scheduled Charging Set";
CM_ SG_ 900 ICC_MonSchedChargSet "Scheduled Charging set_Monday";
CM_ SG_ 900 ICC_TueSchedChargSet "Scheduled Charging set_Tuesday";
CM_ SG_ 900 ICC_WedSchedChargSet "Scheduled Charging set_Wednesday";
CM_ SG_ 900 ICC_ThuSchedChargSet "Scheduled Charging set_Thursday";
CM_ SG_ 900 ICC_FriSchedChargSet "Scheduled Charging set_Friday";
CM_ SG_ 900 ICC_SatSchedChargSet "Scheduled Charging set_Saturday";
CM_ SG_ 900 ICC_SunSchedChargSet "Scheduled Charging set_Sunday";
CM_ SG_ 900 ICC_PreHeatDepartTi1_Hr "Time for preheating_Hour";
CM_ SG_ 900 ICC_PreHeatDepartTi2_Hr "Time for preheating_Hour";
CM_ SG_ 900 ICC_PreHeatDepartTi2_Mins "Time for preheating_Minutes";
CM_ SG_ 900 ICC_PreHeatDepartSetFb "feedback signal from ICC to TBOX";
CM_ BO_ 900 "IBUS1, cyclic every 100 ms, sent by ICC";
CM_ SG_ 902 BCM_HeatedSteerWhlSt "Heated Steering wheel status";
CM_ SG_ 902 BCM_RealCurrent "Heated Steering wheel_Real current";
CM_ SG_ 902 BCM_RealT "Heated Steering wheel_Real Temp";
CM_ SG_ 902 BCM_HSWCURspEror "HSWCU_Response Error";
CM_ SG_ 902 BCM_HeatedSteerWhlSCF "Heated Steering wheel_SCF";
CM_ SG_ 902 BCM_HeatedSteerWhlOCF "Heated Steering wheel_OCF";
CM_ SG_ 902 BCM_HeatedSteerWhlThPro "Heated Steering wheel_ThProtect";
CM_ SG_ 902 BCM_ECUFail "Heated Steering wheel_ECUFailure";
CM_ BO_ 902 "IBUS1, cyclic every 100 ms, sent by GW";
CM_ SG_ 912 ESP_390_CheckSum "ESP_390_Message Checksum (Data ID: 0x33)";
CM_ SG_ 912 ESP_390_AliveCounter "EP_390_Message CounterESP_390_AliveCounter";
CM_ SG_ 912 ESP_TPMS_CalSts "Calibrations status(CalibrationStatus)";
CM_ SG_ 912 ESP_TPMS_WarnLampFL "Warning Lamp for TPMS Front left(PosWLampFL_indirect)";
CM_ SG_ 912 ESP_TPMS_WarnLampFR "Warning Lamp for TPMS Front right(PosWLampFR_indirect)";
CM_ SG_ 912 ESP_TPMS_WarnLampRL "Warning Lamp for TPMS Rear Left(PosWLampRL_indirect)";
CM_ SG_ 912 ESP_TPMS_WarnLampRR "Warning Lamp for TPMS Rear right(PosWLampRR_indirect)";
CM_ SG_ 912 ESP_TPMS_CalPrevnSts "Calibrations status(CalibrationPreventStatus)";
CM_ BO_ 912 "IBUS1, cyclic every 200 ms, sent by GW";
CM_ SG_ 913 BMS_330_391_CheckSum "BMS_330_Message checksum (E2E data ID: 0x3F)";
CM_ SG_ 913 BMS_330_391_AliveCounter "BMS_330_AliveCounter";
CM_ SG_ 913 BMS_VehInsulFltDisp "Vehicle insulation fault display";
CM_ SG_ 913 BMS_PwrBattSysFltDisp "Power battery system fault display";
CM_ SG_ 913 BMS_PwrBattRmngCpSOC "Remaining SOC";
CM_ SG_ 913 BMS_PwrBattAvlCp "Power battery capacity in kWh";
CM_ SG_ 913 BMS_CellMinTAlrm "cell temperature too low";
CM_ SG_ 913 BMS_PwrBattThermRunawayAlrm "Thermal Runaway detected";
CM_ SG_ 913 BMS_PwrBattOverT "cell temperature too high";
CM_ SG_ 913 BMS_PwrBattInsulSts "Traction battery insulation state";
CM_ BO_ 913 "IBUS1, cyclic every 50 ms, sent by GW";
CM_ SG_ 965 AMP_OTAInhbRdy "TA pre-condition and Inhibiting of all OTA relevant ECUs";
CM_ BO_ 965 "IBUS1, cyclic every 100 ms, sent by AMP";
CM_ SG_ 992 VCU_reqFullEDUCooltFlow "Full EDU/MCU coolant flow request signal";
CM_ SG_ 992 VCU_HVEMBoostModSt "HV EM Boost Mode Status";
CM_ SG_ 992 VCU_MaxBoostCntr "Max Boost counter";
CM_ SG_ 992 VCU_BoostEnStatCoded "Boost Enable Status Coded";
CM_ BO_ 992 "IBUS1, cyclic every 1000 ms, sent by GW";
CM_ SG_ 1131 TBOX_46B_CheckSum "TBOX_46B_message checksum ( 0xAA)TBOX_46B_CheckSum";
CM_ SG_ 1131 TBOX_46B_AliveCounter "TBOX_46B_message counterTBOX_46B_AliveCounter";
CM_ SG_ 1131 TBOX_GPSGeoEllips "GPS_dAlt_Geo_vs_Ellips";
CM_ SG_ 1131 TBOX_GPSLongDirection "GPS_Long_Direction";
CM_ SG_ 1131 TBOX_GPSLatDirection "GPS_Lat_Direction";
CM_ SG_ 1131 TBOX_SysSts "System Status";
CM_ SG_ 1131 TBOX_GPSCourseAg "GPS_Course_Angle";
CM_ BO_ 1131 "IBUS1, cyclic every 500 ms, sent by GW";
CM_ SG_ 1133 TBOX_46D_CheckSumm "TBOX_46D_message checksum ( 0x04)TBOX_46D_CheckSum";
CM_ SG_ 1133 TBOX_46D_AliveCounter "TBOX_46D_message counterTBOX_46D_AliveCounter";
CM_ SG_ 1133 TBOX_GPSEpochWeekNur "GPS_Epoch_TimeStamp_Week Number";
CM_ SG_ 1133 TBOX_GPSEpochTOW "GPS_Epoch_TimeStamp_TOW";
CM_ BO_ 1133 "IBUS1, cyclic every 500 ms, sent by GW";
CM_ SG_ 1135 TBOX_46F_CheckSum "TBOX_46F_message checksum ( 0xC6)TBOX_46F_CheckSum";
CM_ SG_ 1135 TBOX_46F_AliveCounter "TBOX_46F_message counterTBOX_46F_AliveCounter";
CM_ SG_ 1135 TBOX_VertAccuracy "Estimated Positioning Vertical accuracy";
CM_ SG_ 1135 TBOX_GPSVDOP "GPS_VDOP";
CM_ SG_ 1135 TBOX_GPSFixOK "GPS FIX valid";
CM_ SG_ 1135 TBOX_GNSSVelocity "Estimation of velocity";
CM_ BO_ 1135 "IBUS1, cyclic every 500 ms, sent by GW";
CM_ SG_ 1137 PLGM_UsrSetTrMaxHei "The maximum opening height of the rear door power set by the user (indicating that the stop height is set by the user. In the power mode, the height of the tailgate will not be greater than this value)Indicate customized maximum height.";
CM_ SG_ 1137 PLGM_LeTrPosn "Current height of the tailgate provided by the left stayIndicate the trunk position by percentage.";
CM_ SG_ 1137 PLGM_RiTrPosn "Current height of the tailgate provided by the right stayIndicate the trunk position by percentage.";
CM_ SG_ 1137 PLGM_LiRemdngReq_BCM "Turn signal lamp flashing requestReqeust to BCM for light reminding.";
CM_ SG_ 1137 PLGM_SoundRemdngReq_EHU "Speaker tone requestReqeust to ICC for sound reminding";
CM_ SG_ 1137 PLGM_FctEnaRes "Results of enable/disable of power function of stayIndicate if power lifing and closing function enabled or disabled.";
CM_ SG_ 1137 PLGM_SysFltIndcn "Power tailgate system faultyIndicate if PLG System failure happened., Including ECU,spindle and latch";
CM_ SG_ 1137 PLGM_TrSwtStsIndcn "Rear door switch state signalIndicate trunk status.";
CM_ SG_ 1137 PLGM_TrLtchStsIndcn "State signal of tail door lockIndicate latch status.";
CM_ SG_ 1137 PLGM_TrSwtTrigOpenReq "Rear door outside switch triggered opening requestWhen handle switch pressed, and trunk is fully closed, PLG send request to PEPS, and PEPS receive this signal to check key.";
CM_ SG_ 1137 PLGM_OperMod "Operating mode of controllerIndicate the working mode of PLG after end of line test.";
CM_ SG_ 1137 PLGM_TrSwtSts "State of tail door outer switchIndicate if handle switch is pressed or not.";
CM_ SG_ 1137 PLGM_LimpHomeSts "Limp home stateWhen trunk is open, if one of the spindle cannot work, PLG will stop driving spindles.";
CM_ SG_ 1137 PLGM_DrvrSwtSts "Driver side switch stateIndicate if driver switch is pressed or not.";
CM_ SG_ 1137 PLGM_TrInnrSwtSts "Rear door inner switch stateIndicate the operation to inner switch.";
CM_ SG_ 1137 PLGM_AntipinchSts "Anti-pinch state (whether anti-pinch occurs)Indicate if anti-pinch happened.";
CM_ SG_ 1137 PLGM_TrSts "Trunk state";
CM_ SG_ 1137 PLGM_OTARdy_Fb "PLGM OTA ready status feedback";
CM_ SG_ 1137 PLGM_Tindcn_NTC "Ambient temperature signal (the temperature detected by the temperature sensitive resistor in ECU, the default value of this signal is set to 110 ?)Indicate temperature detected by NTC on board.The default value set as 110?.";
CM_ BO_ 1137 "IBUS1, cyclic every 100 ms, sent by GW";
CM_ SG_ 1138 TBOX_472_CheckSum "TBOX_472_message checksum ( 0x9A)TBOX_472_CheckSum";
CM_ SG_ 1138 TBOX_472_AliveCounter "TBOX_472_message counterTBOX_472_AliveCounter";
CM_ SG_ 1138 TBOX_GNSSReckoningTi "GNSS Dead Reckoning Time";
CM_ SG_ 1138 TBOX_HorzAccuracy "Estimated Positioning horizontal accuracy";
CM_ SG_ 1138 TBOX_GPSSpdOverGnd "GPS_Speed_Over_Ground";
CM_ BO_ 1138 "IBUS1, cyclic every 500 ms, sent by GW";
CM_ SG_ 1139 TBOX_473_CheckSum "TBOX_473_message checksum ( 0x9B)TBOX_473_CheckSum";
CM_ SG_ 1139 TBOX_473_AliveCounter "TBOX_473_message counterTBOX_473_AliveCounter";
CM_ SG_ 1139 TBOX_SatellitesNr "Number of Satellites";
CM_ SG_ 1139 TBOX_GPSHDOP "GPS_HDOP";
CM_ SG_ 1139 TBOX_Pitch "Pitch";
CM_ BO_ 1139 "IBUS1, cyclic every 500 ms, sent by GW";
CM_ SG_ 1140 TBOX_ICC_UpdSched "TBOX needs to inform ICC when that time arrives so that ICC can display the appropriate notification to the driver";
CM_ SG_ 1140 TBOX_OTAReq_BMS "OTA request on BMS (HV mode and HV light mode)";
CM_ SG_ 1140 TBOX_OTAReq_VCU "OTA request on VCU (HV mode and HV light mode)";
CM_ SG_ 1140 TBOX_OTAReq_ECC "OTA request on ECC (HV mode and HV light mode)";
CM_ SG_ 1140 TBOX_OTAReq_OBC "OTA request on OBC (HV mode and HV light mode)";
CM_ SG_ 1140 TBOX_OTAReq_MCU_F "OTA request on MCU_F (HV mode and HV light mode)";
CM_ SG_ 1140 TBOX_OTAReq_MCU_R "OTA request onMCU_R (HV mode and HV light mode)";
CM_ SG_ 1140 TBOX_OTAReq_ADAS "OTA request on ADAS (HV mode and HV light mode)";
CM_ SG_ 1140 TBOX_OTAReq_FCM "OTA request on FCM (HV mode and HV light mode)";
CM_ SG_ 1140 TBOX_OTAReq_GW "OTA request on GW (HV mode and HV light mode)";
CM_ SG_ 1140 TBOX_OTAReq_EPS "OTA request on EPS (HV mode and HV light mode)";
CM_ SG_ 1140 TBOX_OTAReq_ESP "OTA request on ESp (HV mode and HV light mode)";
CM_ SG_ 1140 TBOX_OTAReq_iBooster "OTA request on iBooster (HV mode and HV light mode)";
CM_ SG_ 1140 TBOX_OTAReq_SCM "OTA request on SCM (HV mode and HV light mode)";
CM_ SG_ 1140 TBOX_OTAReq_ICC "OTA request on ICC (HV mode and HV light mode)";
CM_ SG_ 1140 TBOX_OTAReq_OHC "OTA request on OHC (HV mode and HV light mode)";
CM_ SG_ 1140 TBOX_OTAReq_BCM "OTA request on BCM (HV mode and HV light mode)";
CM_ SG_ 1140 TBOX_OTAReq_CIM "OTA request on CIM (HV mode and HV light mode)";
CM_ SG_ 1140 TBOX_OTAReq_PKC "OTA request on PKC (HV mode and HV light mode)";
CM_ SG_ 1140 TBOX_OTAReq_PLGM "OTA request on PLGM (HV mode and HV light mode)";
CM_ SG_ 1140 TBOX_OTAReq_TRM "OTA request on TRM (HV mode and HV light mode)";
CM_ SG_ 1140 TBOX_OTAReq_DSMC "OTA request on DSMC (HV mode and HV light mode)";
CM_ SG_ 1140 TBOX_OTAReq_PSM "OTA request on PSM (HV mode and HV light mode)";
CM_ SG_ 1140 TBOX_OTAReq_VSP "OTA request on VSP (HV mode and HV light mode)";
CM_ SG_ 1140 TBOX_OTAReq_TBOX "OTA request on TBOX (HV mode and HV light mode)";
CM_ BO_ 1140 "IBUS1, CE every 1000 ms, sent by GW";

BA_DEF_ BO_ "GenMsgCycleTime" INT 0 65535;
BA_DEF_DEF_ "GenMsgCycleTime" 0;
BA_ "GenMsgCycleTime" BO_ 82 100;
BA_ "GenMsgCycleTime" BO_ 88 100;
BA_ "GenMsgCycleTime" BO_ 89 50;
BA_ "GenMsgCycleTime" BO_ 237 20;
BA_ "GenMsgCycleTime" BO_ 274 10;
BA_ "GenMsgCycleTime" BO_ 275 10;
BA_ "GenMsgCycleTime" BO_ 276 20;
BA_ "GenMsgCycleTime" BO_ 277 10;
BA_ "GenMsgCycleTime" BO_ 336 10;
BA_ "GenMsgCycleTime" BO_ 337 10;
BA_ "GenMsgCycleTime" BO_ 372 100;
BA_ "GenMsgCycleTime" BO_ 373 100;
BA_ "GenMsgCycleTime" BO_ 374 100;
BA_ "GenMsgCycleTime" BO_ 377 100;
BA_ "GenMsgCycleTime" BO_ 440 20;
BA_ "GenMsgCycleTime" BO_ 450 10;
BA_ "GenMsgCycleTime" BO_ 552 10;
BA_ "GenMsgCycleTime" BO_ 553 10;
BA_ "GenMsgCycleTime" BO_ 564 10;
BA_ "GenMsgCycleTime" BO_ 616 20;
BA_ "GenMsgCycleTime" BO_ 649 200;
BA_ "GenMsgCycleTime" BO_ 673 50;
BA_ "GenMsgCycleTime" BO_ 684 100;
BA_ "GenMsgCycleTime" BO_ 743 100;
BA_ "GenMsgCycleTime" BO_ 756 100;
BA_ "GenMsgCycleTime" BO_ 757 100;
BA_ "GenMsgCycleTime" BO_ 767 100;
BA_ "GenMsgCycleTime" BO_ 783 1000;
BA_ "GenMsgCycleTime" BO_ 792 20;
BA_ "GenMsgCycleTime" BO_ 799 200;
BA_ "GenMsgCycleTime" BO_ 819 50;
BA_ "GenMsgCycleTime" BO_ 821 50;
BA_ "GenMsgCycleTime" BO_ 822 100;
BA_ "GenMsgCycleTime" BO_ 823 100;
BA_ "GenMsgCycleTime" BO_ 835 50;
BA_ "GenMsgCycleTime" BO_ 840 100;
BA_ "GenMsgCycleTime" BO_ 852 10;
BA_ "GenMsgCycleTime" BO_ 853 10;
BA_ "GenMsgCycleTime" BO_ 856 100;
BA_ "GenMsgCycleTime" BO_ 868 100;
BA_ "GenMsgCycleTime" BO_ 883 100;
BA_ "GenMsgCycleTime" BO_ 888 100;
BA_ "GenMsgCycleTime" BO_ 890 100;
BA_ "GenMsgCycleTime" BO_ 897 100;
BA_ "GenMsgCycleTime" BO_ 898 100;
BA_ "GenMsgCycleTime" BO_ 899 100;
BA_ "GenMsgCycleTime" BO_ 900 100;
BA_ "GenMsgCycleTime" BO_ 902 100;
BA_ "GenMsgCycleTime" BO_ 912 200;
BA_ "GenMsgCycleTime" BO_ 913 50;
BA_ "GenMsgCycleTime" BO_ 965 100;
BA_ "GenMsgCycleTime" BO_ 992 1000;
BA_ "GenMsgCycleTime" BO_ 1131 500;
BA_ "GenMsgCycleTime" BO_ 1133 500;
BA_ "GenMsgCycleTime" BO_ 1135 500;
BA_ "GenMsgCycleTime" BO_ 1137 100;
BA_ "GenMsgCycleTime" BO_ 1138 500;
BA_ "GenMsgCycleTime" BO_ 1139 500;
BA_ "GenMsgCycleTime" BO_ 1140 1000;

VAL_ 54 TBOX_RemSeekCarCtrlCmd 0 "without_remote_control" 1 "Remote_flash_lamp" 2 "Sound_horn_remotely" 3 "Remote_flashing_horn" ;
VAL_ 54 TBOX_RemClsTrCmd 0 "without_remote_control" 1 "Remote_open_tailgate" 2 "Remote_close_tailgate" 3 "Reserved" ;
VAL_ 54 TBOX_RemDrvrSeatVentnCmd 0 "Void" 1 "Remote_driver_seat_ventilation_high_gear" 2 "remote_driver_seat_ventilation_middle_gear" 3 "remote_driver_seat_ventilation_low_gear" 4 "remotely_close_driver_seat_ventilation" ;
VAL_ 54 TBOX_RemDrvrSeatHeatgCmd 0 "Void" 1 "remote_driver's_seat_heating_high_gear" 2 "remote_driver_seat_heating_mid_gear" 3 "remote_driver's_seat_heating_low_gear" 4 "remotely_close_driver_seat_heating" ;
VAL_ 54 TBOX_RemSetWelFct 0 "No_remote_setting" 1 "function_on" 2 "function_OFF" 3 "Reserved" ;
VAL_ 54 TBOX_RemPassSeatVentnCmd 0 "without_remote_control" 1 "Open_the_first_position_of_the_passenger_seat_remotely" 2 "Open_the_second_ventilation_gear_of_the_passenger_seat_remotely" 3 "Remote_driving_passenger_seat_ventilation_third_gear" 4 "Remote_closing_passenger_seat_heating" ;
VAL_ 54 TBOX_RemPassSeatHeatgCmd 0 "without_remote_control" 1 "Remote_open_passenger_seat_heating_first_gear" 2 "Remote_passenger_seat_heating_second_gear" 3 "Remote_passenger_seat_heating_third_gear" 4 "Remote_closing_passenger_seat_heating" ;
VAL_ 54 TBOX_ClsAVMFct_ICC 0 "without_remote_control" 1 "Turn_off_ICC" ;
VAL_ 54 TBOX_ClsRemAVMFct_AVAP 0 "without_remote_control" 1 "Turn_off_AVAP" ;
VAL_ 54 TBOX_RemSetFolwMeFct_BCM 0 "No_remote_setting" 1 "Follow_Me_Home_function_OFF" 2 "headlamp_delay:15_s" 3 "Headlamp_delay:30_s" 4 "Headlamp_delay:45_s" 5 "Headlamp_delay_60_s" ;
VAL_ 54 TBOX_RemSetCtrlLockFct_PKC 0 "No_remote_setting" 1 "function_on" 2 "function_OFF" 3 "Reserved" ;
VAL_ 54 TBOX_RemSetKickSnsrFct 0 "No_remote_setting" 1 "function_on" 2 "function_OFF" 3 "Reserved" ;
VAL_ 54 TBOX_VideoCtrlReq 0 "No_remote_view_command" 1 "panoramic" 2 "Left_side" 3 "Right" 4 "Front_side" 5 "Rear_side" 6 "Turn_off_views" 7 "Reserved" ;
VAL_ 54 TBOX_VoiceBlowerLimReq 0 "No_request" 1 "Request" ;
VAL_ 54 TBOX_RemCtrlCmdFb 0 "Void" 1 "Successful" 2 "Failed" 3 "Reserved" ;
VAL_ 54 TBOX_CtrlReMirrReq 0 "without_control" 1 "Unfold_rear-view_mirror" 2 "Folding_rear-view_mirrors" 3 "Invalid_value" ;
VAL_ 54 TBOX_eCallMuteSt 0 "No_actiont" 1 "EcallUnmute" 2 "AutomaticEcallMute" 3 "ManualEcallMute" ;
VAL_ 54 TBOX_eCallSt 0 "eCall_Standby" 1 "eCall_in_Testmode" 2 "eCall_FAILURE" 3 "eCall_DEACTIVATED" 4 "eCall_Active_manual_triggered" 5 "eCall_Active_automatic_triggered" ;
VAL_ 68 ICC_FaderSet 10 "Center" ;
VAL_ 68 ICC_MediaSrcSet 0 "Local_radio" 1 "USB" 2 "BT-A2DP" 3 "Audio_from_3rd_party_Apps" 4 "Carplay_Music" 5 "Carlife_Music" 6 "Internet_radio" 7 "Reserved" ;
VAL_ 68 ICC_LeRiBalSet 10 "Center" ;
VAL_ 68 ICC_NavSrcSet 0 "None" 1 "Local_Navi" 2 "Carplay_Navi" 3 "CarLife_Navi" 4 "Carplay_Notification" 5 "CarLife_Notification" ;
VAL_ 68 ICC_BeepSrcSet 0 "None" 1 "Beep" ;
VAL_ 68 ICC_VrTtsSrcSet 0 "None" 1 "Native_VR" 2 "CarPlay_Siri" 3 "Native_TTS" 4 "CarLife_VR" ;
VAL_ 68 ICC_AlertSrcSet 0 "None" 1 "Local_Notification" ;
VAL_ 68 ICC_AlertVolSet 63 "Invalid_Value" ;
VAL_ 68 ICC_ChimeSrcSet 0 "None" 1 "Chime_FL/FR" 2 "Chime_Specific_all" 3 "Reserved" ;
VAL_ 68 ICC_PhnSrcSet 0 "None" 1 "CarPlay_Phone" 2 "Bluetooth_phone_call" 3 "i-call/e-call" ;
VAL_ 68 ICC_RTSrcSet 0 "None" 1 "CarPlay_Alert_for_ringtone" 2 "Bluetooth_Phone_Ringtone" 3 "i-CALL_Ringtone" ;
VAL_ 70 ICC_FolwMeHomeTiSet 0 "Not_Use" 1 "0" 2 "15" 3 "30" 4 "45" 5 "60" ;
VAL_ 70 ICC_IntrLampTiSet 0 "Not_Use" 1 "0" 2 "15" 3 "30" 4 "45" 5 "60" ;
VAL_ 70 ICC_BluetoothWifiKeyPaySucFlg 0 "NC" 1 "Bluetooth_Mode_Success" 2 "Wifi_Mode_Success" 3 "Smart_key_payment_success_flag" 4 "mobile_payment_success_flag" ;
VAL_ 70 ICC_BluetoothWifiKeyPay 0 "NC" 1 "NFC_Bluetooth_Mode" 2 "NFC_Wifi_Mode" 3 "NFC_NFC_Smart_Key" 4 "NFC_Mobile_Payment" ;
VAL_ 70 ICC_MaiVolSet 63 "Invalid_Value" ;
VAL_ 70 ICC_MuteCtrl 0 "Unmute" 1 "Mute" ;
VAL_ 70 ICC_ChimeVolSet 0 "Chime_Volume_Step_1" 1 "Chime_Volume_Step_2" 2 "Chime_Volume_Step_3" 3 "Chime_Volume_Step_4" 4 "Chime_Volume_Step_5" 5 "Chime_Volume_Step_6" 6 "Chime_Volume_Step_7" 7 "Chime_Volume_Step_8" 8 "Chime_Volume_Step_9" 9 "Chime_Volume_Step_10" 15 "Invalid" ;
VAL_ 70 ICC_IESSModReq 0 "iESS_Off" 1 "iESS_Mode_1" 2 "iESS_Mode_2" 3 "iESS_Mode_3" ;
VAL_ 70 ICC_VSCModReq 0 "Off" 1 "Low" 2 "Mid" 3 "High" ;
VAL_ 70 ICC_HFTVolSet 63 "Invalid" ;
VAL_ 70 ICC_EmgyCallSet 0 "OFF" 1 "ON" ;
VAL_ 70 ICC_SurrndCtrl 0 "Stereo" 1 "Surround" ;
VAL_ 70 ICC_NavVolSet 63 "Invalid" ;
VAL_ 70 ICC_GetVoltReq 0 "No_Action" 1 "Action" ;
VAL_ 70 ICC_RTVolSet 63 "Invalid" ;
VAL_ 70 ICC_GetDTCInfo 0 "No_Action" 1 "Action" ;
VAL_ 70 ICC_GetSwVer 0 "No_Action" 1 "Action" ;
VAL_ 70 ICC_VrTtsVolSet 63 "Invalid" ;
VAL_ 70 ICC_GetHwVer 0 "No_Action" 1 "Action" ;
VAL_ 70 ICC_GetTempReq 0 "No_Action" 1 "Action" ;
VAL_ 72 AMP_Ch1DTCInfo 0 "No_Error_In_This_Channel" 1 "Short_To_Ground/Short_To_ACC/_Open_Load_Error" ;
VAL_ 72 AMP_Ch2DTCInfo 0 "No_Error_In_This_Channel" 1 "Short_To_Ground/Short_To_ACC/_Open_Load_Error" ;
VAL_ 72 AMP_Ch3DTCInfo 0 "No_Error_In_This_Channel" 1 "Short_To_Ground/Short_To_ACC/_Open_Load_Error" ;
VAL_ 72 AMP_Ch4DTCInfo 0 "No_Error_In_This_Channel" 1 "Short_To_Ground/Short_To_ACC/_Open_Load_Error" ;
VAL_ 72 AMP_Ch5DTCInfo 0 "No_Error_In_This_Channel" 1 "Short_To_Ground/Short_To_ACC/_Open_Load_Error" ;
VAL_ 72 AMP_Ch6DTCInfo 0 "No_Error_In_This_Channel" 1 "Short_To_Ground/Short_To_ACC/_Open_Load_Error" ;
VAL_ 72 AMP_Ch7DTCInfo 0 "No_Error_In_This_Channel" 1 "Short_To_Ground/Short_To_ACC/_Open_Load_Error" ;
VAL_ 72 AMP_Ch8DTCInfo 0 "No_Error_In_This_Channel" 1 "Short_To_Ground/Short_To_ACC/_Open_Load_Error" ;
VAL_ 72 AMP_IntT 255 "Invalid" ;
VAL_ 72 AMP_IntVolt 255 "Invalid" ;
VAL_ 72 AMP_IntTSts 0 "Temperature_Normal" 1 "Temperature_Value_Lower_Than_Working_Temperature" 2 "Temperature_Value_Higher_Than_Working_Temperature" 3 "Invalid_Temperature_Value" ;
VAL_ 72 AMP_PhnSrcSts 0 "None" 1 "CarPlay_Phone" 2 "Bluetooth_phone_call" 3 "i-call/e-call" ;
VAL_ 72 AMP_VrTtsSrcSet 0 "None" 1 "Native_VR" 2 "CarPlay_Siri" 3 "Native_TTS" 4 "CarLife_VR" ;
VAL_ 72 AMP_RTVolSet 63 "Invalid" ;
VAL_ 72 AMP_RTSrcSts 0 "None" 1 "CarPlay_Alert_for_ringtone" 2 "Bluetooth_Phone_Ringtone" 3 "i-CALL_Ringtone" ;
VAL_ 72 AMP_VrTtsVolSet 63 "Invalid" ;
VAL_ 72 AMP_ChimeSrcSts 0 "None" 1 "Chime_FL/FR" 2 "Chime_Specific_all" 3 "Reserved" ;
VAL_ 72 AMP_AlertVolSetSts 63 "Invalid_Value" ;
VAL_ 72 AMP_AlertSrcSet 0 "None" 1 "Local_Notification" ;
VAL_ 73 AMP_BalSetSts 10 "Center" ;
VAL_ 73 AMP_VSCModSts 0 "Off" 1 "Low" 2 "Mid" 3 "High" ;
VAL_ 73 AMP_SurrndCtrlSts 0 "Stereo" 1 "Surround" ;
VAL_ 73 AMP_FaderSetSts 10 "Center" ;
VAL_ 73 AMP_EmgyCallSetSts 0 "Off" 1 "On" ;
VAL_ 73 AMP_IESSModSts 0 "IESS_Mode_Off" 1 "IESS_Mode_1" 2 "IESS_Mode_2" 3 "ISS_Mode_3" ;
VAL_ 73 AMP_BeepSrcSts 0 "None" 1 "Beep" ;
VAL_ 73 AMP_MediaSrcSts 0 "Local_radio" 1 "USB" 2 "BT-A2DP" 3 "Audio_from_3rd_party_Apps" 4 "Carplay_Music" 5 "Carlife_Music" 6 "Internet_radio" 7 "Reserved" ;
VAL_ 73 AMP_NavSrcSts 0 "None" 1 "Local_Navi" 2 "Carplay_Navi" 3 "CarLife_Navi" 4 "Carplay_Notification" 5 "CarLife_Notification" ;
VAL_ 73 AMP_HFTVolSetSts 63 "Invalid" ;
VAL_ 73 AMP_MuteCtrlSts 0 "Unmute" 1 "Mute" ;
VAL_ 73 AMP_NavVolSetSts 63 "Invalid" ;
VAL_ 73 AMP_MaiVolSetSts 63 "Invalid" ;
VAL_ 73 AMP_ChimeVolSetSts 0 "Chime_Volume_Step_1" 1 "Chime_Volume_Step_2" 2 "Chime_Volume_Step_3" 3 "Chime_Volume_Step_4" 4 "Chime_Volume_Step_5" 5 "Chime_Volume_Step_6" 6 "Chime_Volume_Step_7" 7 "Chime_Volume_Step_8" 8 "Chime_Volume_Step_9" 9 "Chime_Volume_Step_10" 15 "Invalid" ;
VAL_ 74 AMP_GetHutInfoSts 0 "No_Action" 1 "Action" ;
VAL_ 78 ICC_abdEnaReq 0 "Inactive" 1 "On" 2 "Off" 3 "Reserved" ;
VAL_ 78 ICC_RiFrntWinCtrl 0 "Inactive" 1 "Manual_Up(reserved)" 2 "Manual_Down(reserved)" 5 "Auto_Up" 6 "Auto_Down" 7 "Reserved" ;
VAL_ 78 ICC_LeReWinCtrl 0 "Inactive" 1 "Manual_Up(reserved)" 2 "Manual_Down(reserved)" 5 "Auto_Up" 6 "Auto_Down" 7 "Reserved" ;
VAL_ 78 ICC_RiReWinCtrl 0 "Inactive" 1 "Manual_Up(reserved)" 2 "Manual_Down(reserved)" 5 "Auto_Up" 6 "Auto_Down" 7 "Reserved" ;
VAL_ 78 ICC_LeFrntWinCtrl 0 "Inactive" 1 "Manual_Up(reserved)" 2 "Manual_Down(reserved)" 5 "Auto_Up" 6 "Auto_Down" 7 "Reserved" ;
VAL_ 78 ICC_FrntWshrCtrl 0 "Inactive" 1 "On" 2 "Off" 3 "Reserved" ;
VAL_ 78 ICC_FrntWiprCtrl 0 "Inactive" 1 "OFF" 2 "Point_Move" 3 "Low_low_speed" 4 "High_high_speed" ;
VAL_ 78 ICC_ReWiprCtrl 0 "Inactive" 1 "On" 2 "Off" 3 "Reserved" ;
VAL_ 78 ICC_PosnLampCtrl 0 "Inactive" 1 "Left_Park_On" 2 "Right_Park_On" 3 "All_On" 4 "Off" ;
VAL_ 78 ICC_HiBeamCtrl 0 "Inactive" 1 "On" 2 "Off" 3 "Reserved" ;
VAL_ 78 ICC_LoBeamCtrl 0 "Inactive" 1 "On" 2 "Off" 3 "Reserved" ;
VAL_ 78 ICC_ReWshrCtrl 0 "Inactive" 1 "On" 2 "Off" 3 "Reserved" ;
VAL_ 78 ICC_TrunkLockCtrl 0 "Inactive" 1 "Open" 2 "Close" 3 "Reserved" ;
VAL_ 78 ICC_SunroofPercCtrlCmdReq 127 "Invalid" ;
VAL_ 78 ICC_FrntFogLampCtrl 0 "Inactive" 1 "On" 2 "Off" 3 "Reserved" ;
VAL_ 78 ICC_ReFogLampCtrl 0 "Inactive" 1 "On" 2 "Off" 3 "Reserved" ;
VAL_ 78 ICC_ReDefrstOpenReq 0 "Inactive" 1 "Enable" 2 "Disable" 3 "Reserved" ;
VAL_ 78 ICC_SunshadeCtrlReq 0 "No_Request_No_Request" 1 "Sunshade_Open_Request_Sunshade_Open_Request" 2 "Sunshade_Close_Request_Sunshade_Close_Request" 3 "Reserved" ;
VAL_ 78 ICC_CentrLockCtrl 0 "Inactive" 1 "Unlock" 2 "Lock" 3 "Reserved" ;
VAL_ 78 ICC_MirrCmd 0 "Inactive" 1 "Fold" 2 "Unfold" 3 "Reserved" ;
VAL_ 78 ICC_ReMirrAutoFoldSet 0 "Inactive" 1 "On" 2 "Off" 3 "Reserved" ;
VAL_ 78 ICC_SunroofshadePercCtrlCmdReq 0 "Sunroof" 1 "Sunshade_reserved" ;
VAL_ 78 ICC_RainClsdSunroofSet 0 "Default" 1 "Active" 2 "Inactive" 3 "Reserved" ;
VAL_ 78 ICC_ArmedClsdWinSet 0 "Default" 1 "Active" 2 "Inactive" 3 "Reserved" ;
VAL_ 78 ICC_OffUnlckSet 0 "Default" 1 "Active" 2 "Inactive" 3 "Reserved" ;
VAL_ 78 ICC_DoorUnlockSet 0 "Inactive" 1 "Driver_door" 2 "All_doors" 3 "Reserved" ;
VAL_ 82 ICC_WIFIAPAuthentMechanism 0 "Open" 1 "WPA" 2 "PSK" 3 "Reserved" ;
VAL_ 82 ICC_SetMaxPosnCmd_PLGM 0 "Inactive" ;
VAL_ 82 ICC_TrActnCmd 0 "Inactive" 1 "Open_Request(Touch_Screen_Or_Voice)" 2 "Close_Request(Touch_Screen_Or_Voice)" 3 "Halt" ;
VAL_ 82 ICC_Ota_Inst 0 "Check" 1 "Accept" 2 "Schedule" 3 "Reserved" ;
VAL_ 82 ICC_DrvrMirrTurnDwnAllwd 0 "Inactive" 1 "Left_Active" 2 "Right_Active" 3 "Both_Left_and_Right_Active" ;
VAL_ 82 ICC_Updcomp 0 "Check" 1 "Update_successful" 2 "Update_failed" 3 "Rollback_successful" 4 "Rollback_failed" ;
VAL_ 88 TBOX_RemClsWin_RW_CtrlCmd 126 "No_operation" 127 "Invalid" ;
VAL_ 88 TBOX_California_mode 0 "INIT" 1 "ON" 2 "OFF" 3 "INVALID" ;
VAL_ 88 TBOX_RemClsSunroofCtrlCmd 127 "Invalid" ;
VAL_ 89 ACU_FrntCrashOutpSts 0 "no_crash,_level_0" 1 "front_crash_low,_level_1" 2 "front_crash_high,_level_2" 7 "invalid" ;
VAL_ 89 ACU_RiSideCrashOutpSts 0 "no_crash,_level_0" 1 "right_side_crash_high,_level_2" 2 "unused" 3 "invalid" ;
VAL_ 89 ACU_LeSideCrashOutpSts 0 "no_crash,_level_0" 1 "left_side_crash_high,_level_2" 2 "unused" 3 "invalid" ;
VAL_ 89 ACU_RearCrashOutpSts 0 "no_crash,_level_0" 1 "rear_crash_high,_level_2" 2 "unused" 3 "invalid" ;
VAL_ 89 ACU_RollovrCrashOutpSts 0 "no_crash,_level_0" 1 "rollover_crash,_level_2" 2 "unused" 3 "invalid" ;
VAL_ 89 ACU_Crash_cfm 0 "no_crash" 1 "crash_happened" 2 "not_used" 3 "invalid" ;
VAL_ 98 DSMC_DrvrSeatMemRecallFb 0 "Void" 1 "Successful" 2 "Failed" 3 "No_UID_Data" ;
VAL_ 98 DSMC_DrvrSeatWelFctSetFb 0 "Void" 1 "Inactive" 2 "Active" 3 "Reserved" ;
VAL_ 98 DSMC_DrvrSeatAntithftFctSetFb 0 "Void" 1 "Inactive" 2 "Active" 3 "Reserved" ;
VAL_ 98 DSMC_ReMirrAutoDwnFlipFb 0 "Void" 1 "Left_Mirror" 2 "Right_Mirror" 3 "Both" ;
VAL_ 98 DSMC_DrvrSeatMemDataUpdFb 0 "Void" 1 "Successful" 2 "Failed" 3 "Reserved" ;
VAL_ 100 PLGM_UsrSetTrMaxHeiResFb 0 "Not_Setting" 1 "Successful_Setting" 2 "Failed_Setting" 3 "Reserved" ;
VAL_ 100 PLGM_RemTrCtrlFbInfo 0 "Invalid" 1 "Successful" 2 "Failed" 3 "Processing" ;
VAL_ 100 PLGM_LtchMotRtrnSig 0 "No_Current_Change_No_sudden_change_in_current" 1 "Current_Change_Detected_CinchReturn_Sudden_Change_in_Current_in_Lock_Return" 2 "Current" 3 "Reserved_reservation" ;
VAL_ 144 ICC_PairingCmd 0 "no_action" 1 "Keyfob_pair_command_active" 2 "Phone_pair_over_BLE_active" 3 "Phone_pair_over_NFC_active" ;
VAL_ 144 ICC_VehAccountLoginUIDSts 0 "Reserved" 1 "Switch_to_ICC_current_login_UID" 2 "Switch_to_guest_account" 3 "Reserved" ;
VAL_ 144 ICC_SeatLocnMemOperCmd 0 "Invalid" 1 "write_in_memory_position" 2 "Delete_memory_position" 3 "recall_of_memory_position" 4 "Download" 5 "Stop" ;
VAL_ 144 ICC_AutoLockUnlockCmd 0 "Auto_Unlock/Lock_Disabled" 1 "Auto_Unlock_Enabled" 2 "Auto_Lock_Enabled" 3 "Auto_Unlock/Lock_Enabled" ;
VAL_ 146 ICC_SteerWhlElecAdjSwtSts 0 "Off_default" 1 "Up_adjustment" 2 "Down_downward_adjustment" 3 "Before_forward_adjustment" 4 "After_Backward_Adjustment" 7 "Invalid" ;
VAL_ 146 ICC_SteerWhlHeatgSwtSts 0 "Off_invalid" 1 "On_steering_wheel_heating_switch_signal_valid" 2 "Reserved" 3 "Invalid" ;
VAL_ 237 BMS_OperationStates 0 "BMS_Undefined" 1 "BMS_BOOT" 2 "BMS_PRE_OperatIONAL" 3 "BMS_OperatIONAL" 4 "BMS_PRE_SLEEP" 5 "BMS_Config" ;
VAL_ 237 BMS_BallancingStatus 0 "BMS_BALC_DEActivATED" 1 "BMS_BALC_IDLE" 2 "BMS_BALC_Start" 3 "BMS_BALC_OperatIONAL" 4 "BMS_BALC_STOP" 5 "BMS_BALC_RELAXATION" 15 "BMS_BALC_Undefined" ;
VAL_ 237 BMS_ErrorCategory_CAT0 0 "CATOK" 1 "CATFailure" ;
VAL_ 237 BMS_ErrorCategory_CAT1 0 "CATOK" 1 "CATFailure" ;
VAL_ 237 BMS_ErrorCategory_CAT2 0 "CATOK" 1 "CATFailure" ;
VAL_ 237 BMS_ErrorCategory_CAT3 0 "CATOK" 1 "CATFailure" ;
VAL_ 237 BMS_ErrorCategory_CAT4 0 "CATOK" 1 "CATFailure" ;
VAL_ 237 BMS_ErrorCategory_CAT5 0 "CATOK" 1 "CATFailure" ;
VAL_ 237 BMS_ErrorCategory_CAT6 0 "CATOK" 1 "CATFailure" ;
VAL_ 237 BMS_ErrorCategory_CAT7 0 "CATOK" 1 "CATFailure" ;
VAL_ 237 BMS_ErrorCategory_CAT8 0 "CATOK" 1 "CATFailure" ;
VAL_ 237 BMS_HardwareStatus_OK 0 "InitFail" 1 "OK" ;
VAL_ 237 BMS_ErrorCategory_Mem_Empty 0 "InitFail" 1 "OK" ;
VAL_ 237 BMS_ConfigurationStatus_OK 0 "InitFail" 1 "OK" ;
VAL_ 237 BMS_MeasurementModules_OK 0 "InitFail" 1 "OK" ;
VAL_ 237 BMS_BatteryGeneralStatus_OK 0 "InitFail" 1 "OK" ;
VAL_ 237 BMS_SDIL_Sts 0 "Off" 1 "On" ;
VAL_ 237 BMS_CL30C_Sts 0 "Off" 1 "On" ;
VAL_ 237 BMS_CL15_Sts 0 "Off" 1 "On" ;
VAL_ 237 BMS_HVIL_OK 0 "InitFail" 1 "OK" ;
VAL_ 237 BMS_HV_ContactorsStatus_OK 0 "InitFail" 1 "OK" ;
VAL_ 237 BMS_SW_Status_OK 0 "InitFail" 1 "OK" ;
VAL_ 237 BMS_CurrentSensor_OK 0 "InitFail" 1 "OK" ;
VAL_ 237 BMS_IsolatoinStatus_OK 0 "InitFail" 1 "OK" ;
VAL_ 237 BMS_StateMAchine_Status 1 "not_used" 2 "BMS_initializing" 3 "BMS_Standby" 4 "BMS_precharging" 5 "HV_active" 6 "not_used" 7 "BMS_HV_OFF_Emergency" 8 "BMS_shutdown" ;
VAL_ 237 BMS_BDU_Status 1 "not_used" 2 "BMS_initializing" 3 "BMS_Standby" 4 "BMS_precharging" 5 "HV_active" 6 "not_used" 7 "BMS_HV_OFF_Emergency" 8 "BMS_shutdown" ;
VAL_ 274 YRS_YawRateCalSts 0 "Sensor_Not_Calibrated" 1 "Sensor_Calibrated" ;
VAL_ 274 YRS_YawRateSnsrSts 0 "Initializing" 1 "Valid" 2 "Invalid" 3 "Reserved" ;
VAL_ 274 YRS_LatSnsrSts 0 "Initializing" 1 "Valid" 2 "Invalid" 3 "Reserved" ;
VAL_ 275 YRS_LgtSnsrSts 0 "Initializing" 1 "Valid" 2 "Invalid" 3 "Reserved" ;
VAL_ 276 ESP_OTARdy_Fb 0 "Initial" 1 "Ready" 2 "Not_Ready" 3 "Invalid" ;
VAL_ 276 ESP_FltIndcn_DTC 0 "No_Fault" 1 "Fault" ;
VAL_ 276 ESP_ActvSig_VDC 0 "ESP_Standby" 1 "ESP_Actually_Operating" ;
VAL_ 276 ESP_ActvSig_TCS 0 "TCS_Standby" 1 "TCS_Actually_Operating" ;
VAL_ 276 ESP_ActvSig_EBD 0 "EBD_Not_Active" 1 "EBD_Active" ;
VAL_ 276 ESP_ActvSig_DTC 0 "DTC_Not_Active" 1 "DTC_Active" ;
VAL_ 276 ESP_WarningOn 0 "No_Request" 1 "Yellow_Lamp_Request" 2 "Red_Lamp_Request" 3 "Reserved" ;
VAL_ 276 ESP_Actvndcn_CDD 0 "Not_Active" 1 "Active" ;
VAL_ 276 ESP_FltIndcn_CDD 0 "Available" 1 "Not_Available" ;
VAL_ 276 ESP_ActvIndcn_ABA 0 "Not_Active" 1 "Active" ;
VAL_ 276 ESP_FltIndcn_ABA 0 "Available" 1 "Not_Available" ;
VAL_ 276 ESP_ActvIndcn_ABP 0 "Not_Active" 1 "Active" ;
VAL_ 276 ESP_FltIndcn_ABP 0 "Available" 1 "Not_Available" ;
VAL_ 276 ESP_ActvIndcn_AEB 0 "Not_Active" 1 "Active" ;
VAL_ 276 ESP_FltIndcn_AEB 0 "Available" 1 "Not_Available" ;
VAL_ 276 ESP_ActvIndcn_AWB 0 "Not_Active" 1 "Active" ;
VAL_ 276 ESP_FltIndcn_AWB 0 "Available" 1 "Not_Available" ;
VAL_ 276 ESP_VehStandstillIndcn 0 "Not_Standstill" 1 "Standstill" 2 "Invalid" 3 "Reserved" ;
VAL_ 276 ESP_BrkOverTIndcn 0 "Not_High" 1 "Temp_Too_High" ;
VAL_ 276 ESP_FltIndcn_VDC 0 "No_Fault" 1 "Fault" ;
VAL_ 276 ESP_ActvIndcn_CDD_AP 0 "Not_Active" 1 "Active" ;
VAL_ 276 ESP_FltIndcn_CDD_AP 0 "No_Error" 1 "Error" ;
VAL_ 277 ESP_WhlSpdVld_RF 0 "Initializing" 1 "Valid" 2 "Invalid" 3 "Reserved" ;
VAL_ 277 ESP_WhlMovgDir_RF 0 "Init" 1 "Forward" 2 "Backward" 3 "Stop" 4 "Invalid" ;
VAL_ 277 ESP_WhlMovgDir_LF 0 "Init" 1 "Forward" 2 "Backward" 3 "Stop" 4 "Invalid" ;
VAL_ 277 ESP_WhlSpdVld_LF 0 "Initializing" 1 "Valid" 2 "Invalid" 3 "Reserved" ;
VAL_ 336 MCU_F_CrtTqVld 0 "Initializing" 1 "Valid" 2 "Invalid" 3 "Reserved" ;
VAL_ 336 MCU_F_CrtRotDir 0 "Standstill" 1 "Forward_rotation_(forward_mode)" 2 "Reverse_(reverse_mode)" 3 "Invalid" ;
VAL_ 336 MCU_F_CrtSpd 65535 "Invalid" ;
VAL_ 336 MCU_F_CrtSpdSigVld 0 "Initializing" 1 "Valid" 2 "Invalid" 3 "Reserved" ;
VAL_ 336 MCU_F_CrtTq 2047 "Invalid" ;
VAL_ 336 MCU_F_CrtMod 0 "Initialization_(function)" 1 "LV_ready" 2 "Standby" 3 "reserved" 4 "Torque_mode" 5 "Speed_control" 6 "reserved" 7 "Internal_inverter_error" 8 "reserved" 9 "Service_job" 10 "Postrun:" 11 "Sleep_Ready" 14 "Init_(dbc_init_value)" 15 "Invalid" ;
VAL_ 336 MCU_F_HVActvDchaSts 0 "Not_discharged" 1 "Discharging" 2 "Discharge_complete" 3 "Discharge_failure" 6 "Init_(dbc_init_value)" 7 "Invalid" ;
VAL_ 336 MCU_F_SlipCtrlActMode 0 "Slip_control_deactivated" 1 "Slip_control_idling" 2 "Slip_control_working" 3 "Fault" ;
VAL_ 336 MCU_F_AlrmLamp_FS 0 "Disable" 1 "Enable" ;
VAL_ 336 MCU_F_HVChkEndFlg 0 "Not_completed" 1 "Completed" ;
VAL_ 337 MCU_R_CrtTqVld 0 "Initializing" 1 "Valid" 2 "Invalid" 3 "Reserved" ;
VAL_ 337 MCU_R_CrtRotDir 0 "Standstill" 1 "Forward_rotation_(forward_mode)" 2 "Reverse_(reverse_mode)" 3 "Invalid" ;
VAL_ 337 MCU_R_CrtSpd 65535 "Invalid" ;
VAL_ 337 MCU_R_CrtSpdSigVld 0 "Initializing" 1 "Valid" 2 "Invalid" 3 "Reserved" ;
VAL_ 337 MCU_R_CrtTq 2047 "Invalid" ;
VAL_ 337 MCU_R_CrtMod 0 "Initialization_(function)" 1 "LV_ready" 2 "Standby" 3 "reserved" 4 "Torque_mode" 5 "Speed_control" 6 "reserved" 7 "Internal_inverter_error" 8 "reserved" 9 "Service_job" 10 "Postrun:" 11 "Sleep_Ready" 14 "Init_(dbc_init_value)" 15 "Invalid" ;
VAL_ 337 MCU_R_Decoup_State 0 "Init" 1 "Disconnect" 2 "Connect_in_progress" 3 "Synchronized" 4 "Connected" 5 "Disconnect_in_progress" 6 "Fault_disconnected" 7 "Fault_connected" 8 "Fault_connect_state_unknown" 9 "Connect_conditions_not_fulfilled" ;
VAL_ 337 MCU_R_HVActvDchaSts 0 "Not_discharged" 1 "Discharging" 2 "Discharge_complete" 3 "Discharge_failure" 6 "Init_(dbc_init_value)" 7 "Invalid" ;
VAL_ 337 MCU_R_SlipCtrlActMode 0 "Slip_control_deactivated" 1 "Slip_control_idling" 2 "Slip_control_working" 3 "Fault" ;
VAL_ 337 MCU_R_AlrmLamp_FS 0 "Disable" 1 "Enable" ;
VAL_ 337 MCU_R_HVChkEndFlg 0 "Not_completed" 1 "Completed" ;
VAL_ 337 ACU_Pass_OCS_St 0 "Seat_not_occupied" 1 "Seat_occupied" 2 "Fault" 3 "Invalid" ;
VAL_ 337 ACU_AirBagSysAlrmLampSts 0 "Warning_lamp_off" 1 "Warning_lamp_on" 2 "Warning_lamp_blinking" 3 "Invalid" ;
VAL_ 337 ACU_Pass_Airbag_LED 0 "LED_1_2_OFF/OFF" 1 "LED_1_2_ON/OFF" 2 "LED_1_2_OFF/ON" 3 "LED_1_2_ON/ON" 4 "LED_1_2_Blinking" 7 "Invalid" ;
VAL_ 337 ACU_Drvr_Occpt_St 0 "Seat_not_occupied" 1 "Seat_occupied" 2 "Fault" 3 "invalid" ;
VAL_ 337 ACU_BucSwtStFrntDrvr 0 "Buckled" 1 "Not_Buckled" 2 "Fault" 3 "Invalid" ;
VAL_ 337 ACU_BucSwtStFrntPass 0 "Buckled" 1 "Not_Buckled" 2 "Fault" 3 "Invalid" ;
VAL_ 337 ACU_SeatTrkPosnSwtFrntDrvr 0 "Seat_not_formost_position" 1 "Seat_formost_position" 2 "Fault" 3 "Invalid" ;
VAL_ 337 ACU_SeatTrkPosnSwtFrntPass 0 "Seat_not_formost_position" 1 "Seat_formost_position" 2 "Fault" 3 "Invalid" ;
VAL_ 440 ESP_ModFbSig 0 "Init" 1 "Normal" 2 "Sport" 7 "Invalid" ;
VAL_ 440 ESP_ModSwtAllw 0 "Not_Allowed" 1 "Allowed" ;
VAL_ 440 ESP_ActvVehHldFlg 0 "False" 1 "True" ;
VAL_ 440 ESP_VehSecuCdn 0 "ParkSt_Other" 1 "ParkSt_Reld" 2 "ParkSt_Appld" 3 "ParkSt_Reqd" 4 "ParkSt_ReqToutorOvrdn" ;
VAL_ 440 ESP_BrkFStsFlg 0 "False" 1 "True" ;
VAL_ 440 ESP_CddApOpsDirMovmt 0 "False" 1 "True" ;
VAL_ 440 ESP_VehStopSts 0 "Not_Stop" 1 "Stop" ;
VAL_ 440 ESP_VehStandstillSts 0 "Not_Standstill" 1 "Standstill" ;
VAL_ 440 ESP_EPB_BenchMode 0 "Not_Active" 1 "Active" 2 "Reserved" 3 "Invalid" ;
VAL_ 440 ESP_RoadSlopVld 0 "Initializing" 1 "Valid" 2 "Invalid" 3 "Reserved" ;
VAL_ 440 ESP_AEBRdy 0 "Not_ready" 1 "Ready" 2 "Reserved" 3 "Invalid" ;
VAL_ 440 ESPACCRdy 0 "Not_ready" 1 "Ready" 2 "Reserved" 3 "Invalid" ;
VAL_ 440 ESP_ParkRdy 0 "Not_ready" 1 "Ready" 2 "Reserved" 3 "Invalid" ;
VAL_ 440 ESP_ReAEBRdy 0 "Not_ready" 1 "Ready" 2 "Reserved" 3 "Invalid" ;
VAL_ 440 ESP_SpclTerrainModFltIndcn 0 "Not_Available" 1 "Available" ;
VAL_ 440 ESP_DrvOffStRdy 0 "False" 1 "True" ;
VAL_ 440 ESP_TarLSMSts 0 "LSM_Off" 1 "LSM_On" ;
VAL_ 450 EPS_AbortFb 0 "No_Abort" 1 "Driver_Interference_StrWhl" 6 "EPS_Internal_Failure" 7 "Vehilce_Speed_Exceeds_Limits_When_In_Control" 8 "CAN_communication_issue" 9 "Other_Abort_Reasons" ;
VAL_ 450 EPS_SteerWhlAgSig 65535 "Invalid" ;
VAL_ 450 EPS_SteerAgSnsrCalSts 0 "Uncalibrated" 1 "Calibrated" ;
VAL_ 450 EPS_SteerWhlAgSigVld 0 "Initializing" 1 "Valid" 2 "Invalid" 3 "Reserved" ;
VAL_ 450 EPS_SteerWhlRotSpdDir 0 "Forward_rotation" 1 "Negative_rotation" 2 "No_rotation" 3 "Reserved" ;
VAL_ 450 EPS_SteerWhlRotSpdVld 0 "Initializing" 1 "Valid" 2 "Invalid" 3 "Reserved" ;
VAL_ 450 EPS_AdasLatCtrlSts 0 "Off" 1 "Available_For_Control" 2 "Active" 3 "Failure" ;
VAL_ 450 EPS_AdasLatCtrlStsVld 0 "Initializing" 1 "Valid" 2 "Active" 3 "Reserved" ;
VAL_ 450 EPS_SteerWhlRotSpd 4095 "Invalid" ;
VAL_ 450 EPS_AsscMotCrtTq 255 "Invalid" ;
VAL_ 552 MCU_F_BoostEnStat 0 "Boost_unavailable_-_Limited_by_Coolant_Inlet_Temperature" 1 "Boost_unavailable_-__Limited_by_Coolant_Flow" 2 "Boost_unavailable_-__Limited_by_Stator/Rotor_Temperature" 3 "Boost_unavailable_-_Decoupling_Unit_open" 4 "Boost_available" 5 "Boost_unavailable_-_Limited_By_EM_Shaft_Speed" 6 "Boost_unavailable_-Limited_By_Usage_Counter" 7 "Boost_unavailable_-_Other_Reason" ;
VAL_ 552 MCU_F_ActDampStat 0 "Not_active" 1 "Active" 2 "Error" 3 "Init" ;
VAL_ 552 MCU_F_OTARdy_Fb 0 "Initial" 1 "Ready" 2 "Not_Ready" 3 "Invalid" ;
VAL_ 552 MCU_F_ActSafeSt 0 "None" 1 "ASO" 2 "ASC" 3 "ASC_Emergency" 6 "Initial" 7 "Invalid" ;
VAL_ 552 MCU_F_PhaCrt 4095 "Invalid" ;
VAL_ 553 MCU_R_BoostEnStat 0 "Boost_unavailable_-_Limited_by_Coolant_Inlet_Temperature" 1 "Boost_unavailable_-__Limited_by_Coolant_Flow" 2 "Boost_unavailable_-__Limited_by_Stator/Rotor_Temperature" 3 "Boost_unavailable_-_Decoupling_Unit_open" 4 "Boost_available" 5 "Boost_unavailable_-_Limited_By_EM_Shaft_Speed" 6 "Boost_unavailable_-Limited_By_Usage_Counter" 7 "Boost_unavailable_-_Other_Reason" ;
VAL_ 553 MCU_R_ActDampStat 0 "Not_active" 1 "Active" 2 "Error" 3 "Init" ;
VAL_ 553 MCU_R_OTARdy_Fb 0 "Initial" 1 "Ready" 2 "Not_Ready" 3 "Invalid" ;
VAL_ 553 MCU_R_ActSafeSt 0 "None" 1 "ASO" 2 "ASC" 3 "ASC_Emergency" 6 "Initial" 7 "Invalid" ;
VAL_ 553 MCU_R_PhaCrt 4095 "Invalid" ;
VAL_ 564 VCU_RdyLamp 0 "Not_ready" 1 "Ready" ;
VAL_ 564 VCU_BrkLampCtrlSts 0 "No_request" 1 "lighting_request" ;
VAL_ 564 VCU_RemWakeUpEndFlg 0 "remote_control_not_ended" 1 "remote_control_ended" ;
VAL_ 564 VCU_StgyGearSig 0 "Undefined_initial_value" 1 "gear_P" 2 "gear_N" 3 "R_gear" 4 "gear_D" 5 "Reserved" 6 "gear_E" 7 "gear_S" ;
VAL_ 564 VCU_ShiftMisoper 0 "Normal" 1 "Abnormal" ;
VAL_ 564 VCU_GearSigVld 0 "Initializing" 1 "Valid" 2 "Invalid" 3 "Reserved" ;
VAL_ 564 VCU_GearSig 0 "Undefined_initial_value" 1 "gear_P" 2 "gear_N" 3 "R_gear" 4 "D_gear" 5 "Reserved" 6 "gear_E" 7 "gear_S" ;
VAL_ 564 VCU_ACCRdy 0 "Not_ready" 1 "Ready" ;
VAL_ 564 VCU_ParkRdy 0 "Not_ready" 1 "Ready" ;
VAL_ 564 VCU_APSPercVld 0 "Initializing" 1 "Valid" 2 "Invalid" 3 "Reserved" ;
VAL_ 564 VCU_VehSt 0 "VCUSleep" 1 "WakeUp" 2 "Init/StartUp" 3 "Standby" 4 "Driving" 5 "Charging" 6 "PostConditioning" 7 "HV_Active_Discharge" 8 "Afterrun" 9 "EmgcyOff" 10 "EmgcyOff_ADisch" 11 "Safestate" 65535 "Invalid" ;
VAL_ 564 VCU_BrkSig 0 "brake_pedal_not_pressed" 1 "Brake_pedal_depressed" ;
VAL_ 564 VCU_BrkSigVld 0 "Initializing" 1 "Valid" 2 "Invalid" 3 "Reserved" ;
VAL_ 564 VCU_DrvModSigFb 0 "Eco" 1 "Normal" 2 "Sport" 3 "Custom" 4 "Snow" 5 "Offroad" 6 "Valet" 7 "Invalid" ;
VAL_ 564 VCU_DrvModShiftMisoper 0 "Normal" 1 "Abnormal" ;
VAL_ 564 VCU_SpclTerrainModEnaSig 0 "Not_enabled" 1 "Enable" ;
VAL_ 616 ESP_DynoModSts 0 "Initial" 1 "On" 2 "Off" 3 "Invalid" ;
VAL_ 616 ESP_SysSts_EPB 0 "Undefined" 1 "Released_caliper_is_released" 2 "Closed_caliper_is_clamped" 3 "Releasing_caliper_is_being_released" 4 "Locking_caliper_is_clamping" ;
VAL_ 616 ESP_FltIndcn_EPB 0 "Available" 1 "Not_Available" 2 "In_Diagnosis" 3 "Reserved" ;
VAL_ 616 ESP_Actvndcn_EPB 0 "Off" 1 "On" 2 "Flash" 3 "Reserved" ;
VAL_ 616 EPB_WarnMsg01 0 "Off" 1 "Press_The_Brake_Pedal_First,_Then_Release_The_APB_Button" ;
VAL_ 616 EPB_WarnMsg02 0 "Off" 1 "Press_Keep_The_Seatbelt_Attached_And_The_Door_Closed" ;
VAL_ 616 ESP_YawRateStabnAvl 0 "None" 1 "Full" ;
VAL_ 616 EPB_WarnMsg04 0 "Off" 1 "Park_The_Car_On_The_Slope_With_Gentle_Incline" ;
VAL_ 616 ESP_EPBSwtichPosition 0 "Neutral" 1 "Release" 2 "Apply" 3 "Reserved" ;
VAL_ 616 ESP_EPBSwtichPositionValid 0 "Initializing" 1 "Valid" 2 "Invalid" 3 "Reserved" ;
VAL_ 627 TBOX_ScheduleCharg_Start_Hr 31 "Invalid" ;
VAL_ 627 TBOX_ScheduleCharg_End_Hr 31 "Invalid" ;
VAL_ 627 TBOX_ScheduleCharg_End_Mins 63 "Invalid" ;
VAL_ 627 TBOX_SetSceduleChargTimeFb 0 "Invalid" 1 "Successful" 2 "Failed" 3 "Reserved" ;
VAL_ 627 TBOX_ScheduleCharg_Start_Mins 63 "Invalid" ;
VAL_ 627 TBOX_ScheduleCharg_Status 0 "Description_for_the_value_'0x0'" 1 "Description_for_the_value_'0x1'" 2 "Description_for_the_value_'0x2'" 3 "Description_for_the_value_'0x3'" ;
VAL_ 627 TBOX_V2L_TrEna 0 "No" 1 "Yes" ;
VAL_ 627 TBOX_V2L_ChrgPortEna 0 "No" 1 "Yes" ;
VAL_ 627 TBOX_V2V_Ena 0 "No" 1 "Yes" ;
VAL_ 627 TBOX_V2H_Ena 0 "No" 1 "Yes" ;
VAL_ 627 TBOX_V2G_Ena 0 "No" 1 "Yes" ;
VAL_ 649 VCU_SetSpeedLimitSts 254 "max._speed" 255 "no_speed_limit" ;
VAL_ 673 SCM_SuspFb 0 "Normal" 1 "Sport" 2 "Off_Road" 3 "Invalid" ;
VAL_ 673 SCM_OTARdy_Fb 0 "Initial" 1 "Ready" 2 "Not_Ready" 3 "Invalid" ;
VAL_ 673 SCM_Err_sts 0 "no_error" 1 "ERROR_MODE_1" 2 "ERROR_MODE_2" 3 "ERROR_MODE_3" 7 "Invalid" ;
VAL_ 684 IBS_StateOfCharge 255 "SNA" ;
VAL_ 684 IBS_StateOfHealth 255 "SNA" ;
VAL_ 684 IBS_EstVoltaDrop 255 "SNA" ;
VAL_ 684 IBS_OptChargeVolt 255 "SNA" ;
VAL_ 684 IBS_AvgRi 65535 "SNA" ;
VAL_ 743 ECC_ICCSysSwtCmdFb 0 "Inactive" 1 "Air_Conditioning_power_on_(Short)" 2 "Air_Conditioning_shutdown_(long)" 3 "Reserved" ;
VAL_ 743 ECC_CooltLvlWarn 0 "no_warning" 1 "set_warning" 2 "Reserved" 3 "Invalid" ;
VAL_ 767 VCU_WrkShpModFB 0 "init" 1 "Inactive._EPB_fail" 2 "Inactive._Park_lock_disengage_fail" 3 "Inactive._Rear_axle_Clutch_disengage_fail" 4 "Inactive._Clutch_+_EPB_fail" 5 "Inactive._Clutch_+_Park_lock_fail" 6 "Inactive._Clutch_+_EPB_+_Park_lock_fail" 7 "Inactive._EPB_+_Park_lock_fail" 8 "Inactive._Driver_requested_D_or_R_gear_(give_hier_the_highest_priority_while_checking_in_parallel_with_other_conditions)" 9 "Active" 15 "Invalid" ;
VAL_ 767 VCU_ACC_PA_MinA 65535 "Invalid" ;
VAL_ 767 VCU_ACC_PA_MaxA 65535 "Invalid" ;
VAL_ 767 VCU_WrkShpModAvlbSts 0 "Initial_value" 1 "Not_available" 2 "Available" 3 "Invalid" ;
VAL_ 783 ICC_QuickBootMode 0 "Off" 1 "On" ;
VAL_ 792 ESP_BrkPedlStsVld 0 "Initializing" 1 "Valid" 2 "Invalid" 3 "Reserved" ;
VAL_ 792 ESP_BrkPedlSts 0 "Brake_Pedal_Not_Pressed" 1 "Brake_Pedal_Pressed" ;
VAL_ 792 ESP_VehSpdVld 0 "Initializing" 1 "Valid" 2 "Invalid" 3 "Reserved" ;
VAL_ 792 ESP_SysActv 0 "No_Telltale_Requested" 1 "Telltale_Requested" ;
VAL_ 792 ESP_LampSwtOffIndcn 0 "No_Telltale_Requested" 1 "Telltale_Requested" ;
VAL_ 792 ESP_FltIndcn_EBD 0 "No_Telltale_Requested" 1 "Telltale_Requested" ;
VAL_ 792 ESP_FltIndcn_ABS 0 "No_Telltale_Requested" 1 "Telltale_Requested" ;
VAL_ 792 ESP_IninModSigIndcn 0 "Not_In_Initialization_Mode" 1 "In_Intialization_Mode" ;
VAL_ 792 ESP_FltIndcn_TCS 0 "No_Telltale_Requested" 1 "Telltale_Requested" ;
VAL_ 792 ESP_CtrlSts_HDC 0 "Off" 1 "On_Active_Braking" 2 "On_Not_Active_Braking" 3 "Reserved" ;
VAL_ 792 ESP_AvlIndcn_HDC 0 "Available" 1 "Not_Available" ;
VAL_ 792 ESP_NoBrkP 0 "Exist_Brk_Force" 1 "No_Brk_Force" ;
VAL_ 792 ESP_RDAEnaFlg 0 "Inactive_not_enabled" 1 "Active_enable" ;
VAL_ 797 ICC_ScheduleCharg_Start_Mins 63 "Invalid" ;
VAL_ 797 ICC_ScheduleCharg_End_Mins 63 "Invalid" ;
VAL_ 797 ICC_ScheduleCharg_Start_Hr 31 "Invalid" ;
VAL_ 797 ICC_SetScheduleChargTimeFb 0 "Invalid" 1 "Successful" 2 "Failed" 3 "Reserved" ;
VAL_ 797 ICC_ScheduleCharg_End_Hr 31 "Invalid" ;
VAL_ 799 ICC_SetSpeedLimit 254 "max._speed" 255 "no_speed_limit" ;
VAL_ 809 ICC_AddNewUser 0 "Invalid" 1 "UserID1_(guest_/_default)" 2 "UserID2" 3 "UserID3" 4 "UserID4" 5 "UserID5" 6 "UserID6" 7 "UserID7" 8 "UserID8" 9 "UserID9" 10 "UserID10_(Easy_Entry)" ;
VAL_ 809 ICC_SelectUserID 0 "Invalid" 1 "UserID1_(guest_/_default)" 2 "UserID2" 3 "UserID3" 4 "UserID4" 5 "UserID5" 6 "UserID6" 7 "UserID7" 8 "UserID8" 9 "UserID9" 10 "UserID10_(Easy_Entry)" ;
VAL_ 809 ICC_RemoveUserID 0 "Invalid" 1 "UserID1_(guest_/_default)" 2 "UserID2" 3 "UserID3" 4 "UserID4" 5 "UserID5" 6 "UserID6" 7 "UserID7" 8 "UserID8" 9 "UserID9" 10 "UserID10_(Easy_Entry)" ;
VAL_ 809 ICC_UnassignKey 0 "INVALID" 1 "PKC_PhoneAdvName1" 2 "PKC_PhoneAdvName2" 3 "PKC_PhoneAdvName3" 4 "PKC_PhoneAdvName4" 5 "PKC_PhoneAdvName5" 6 "PKC_PhoneAdvName6" 7 "PKC_PhoneAdvName7" ;
VAL_ 809 ICC_RemoveKey 0 "INVALID" 1 "PKC_PhoneAdvName1" 2 "PKC_PhoneAdvName2" 3 "PKC_PhoneAdvName3" 4 "PKC_PhoneAdvName4" 5 "PKC_PhoneAdvName5" 6 "PKC_PhoneAdvName6" 7 "PKC_PhoneAdvName7" ;
VAL_ 819 BCM_KL15_Off_Announcement 0 "NotAvailable" 1 "No_Announcement" 2 "KL15_shutdown_announced" 3 "Reserved" ;
VAL_ 819 BCM_IG1Sts 0 "NotAvailable" 1 "Inactive" 2 "Active" 3 "Reserved" ;
VAL_ 819 BCM_PwrMod 0 "Off" 1 "ACC_(Reserved)" 2 "IGN_On" 3 "Crank_Pending_(Power_Anti-theft_Certification_Process)" 4 "Run" 5 "Crank_Off_(Reserved)" ;
VAL_ 819 BCM_PwrModVld 0 "Initializing" 1 "Valid" 2 "Invalid" 3 "Reserved" ;
VAL_ 819 BCM_BrkSwtSts 0 "No_Pressed" 1 "Pressed" ;
VAL_ 819 BCM_IG1StsVld_CAPE 0 "Initializing" 1 "Valid" 2 "Invalid" 3 "Reserved" ;
VAL_ 819 BCM_IG2StsVld_CAPE 0 "Initializing" 1 "Valid" 2 "Invalid" 3 "Reserved" ;
VAL_ 819 BCM_KL30s_L 0 "Not_Available" 1 "Inactive" 2 "Active" 3 "Reserved" ;
VAL_ 819 BCM_IG2Sts 0 "Not_Available" 1 "Inactive" 2 "Active" 3 "Reserved" ;
VAL_ 819 BCM_InteriorSwtSt 0 "Inactive" 1 "pressed" ;
VAL_ 821 BCM_WiprInSrvPosn 0 "No" 1 "Yes" ;
VAL_ 821 BCM_IntLampTiSetSts 0 "Not_Use" 1 "0" 2 "15" 3 "30" 4 "45" 5 "60" ;
VAL_ 821 BCM_WaterPosnSnsrSwtSts 0 "Inactive" 1 "Active" ;
VAL_ 821 BCM_FrntFogLampOutpCmd 0 "Off" 1 "On" ;
VAL_ 821 BCM_LicPlateLampOutpCmd 0 "Off" 1 "On" ;
VAL_ 821 BCM_EnaSts_ADB 0 "Inactive" 1 "Active" ;
VAL_ 821 BCM_PwrSaveOutpCmd 0 "Off" 1 "On" ;
VAL_ 821 BCM_ExtLampSwtSts 0 "Off" 1 "Auto" 2 "Position" 3 "Low_Beam" ;
VAL_ 821 BCM_HornOutpCmd 0 "Off" 1 "On" ;
VAL_ 821 BCM_HornSwtSts 0 "Off" 1 "On" ;
VAL_ 821 BCM_WelLampOutpCmd 0 "Off" 1 "On" ;
VAL_ 821 BCM_FolwMeHomeSts 0 "Inactive" 1 "Active" ;
VAL_ 821 BCM_FrntFogLampSwtSts 0 "Inactive" 1 "Active" ;
VAL_ 821 BCM_ReFogLampSwtSts 0 "Inactive" 1 "Active" ;
VAL_ 821 BCM_ReWiprBackSwtSts 0 "Inactive" 1 "Active" ;
VAL_ 821 BCM_RainClsSunroofSetSts 0 "Inactive" 1 "Active" ;
VAL_ 821 BCM_MirrLockAutoSetSts 0 "Off" 1 "On" ;
VAL_ 821 BCM_FrntWshrOutpCmd 0 "Off" 1 "On" ;
VAL_ 821 BCM_DangerAlrmLampSwtSts 0 "Off" 1 "On" ;
VAL_ 821 BCM_ReDefrstHeatgCmd 0 "Off" 1 "On" ;
VAL_ 821 BCM_RvsLampOutpCmd 0 "Off" 1 "On" ;
VAL_ 821 BCM_IntLampOutpCmd 0 "Off" 1 "On" ;
VAL_ 821 BCM_LeTrunLampOutpCmd 0 "Off" 1 "On" ;
VAL_ 821 BCM_RiTrunLampOutpCmd 0 "Off" 1 "On" ;
VAL_ 821 BCM_ReWiprOutpCmd 0 "Off" 1 "On" ;
VAL_ 821 BCM_ReWshrOutpCmd 0 "Off" 1 "On" ;
VAL_ 821 BCM_BrkLampSwtSts 0 "Inactive" 1 "Active" ;
VAL_ 821 BCM_HiBeamOutpCmd 0 "Off" 1 "On" ;
VAL_ 821 BCM_LoBeamOutpCmd 0 "Off" 1 "On" ;
VAL_ 821 BCM_PosnLampOutpCmd 0 "Off" 1 "Left_Park_On" 2 "Right_Park_On" 3 "All_On" ;
VAL_ 821 BCM_BrkLampOutpCmd 0 "Off" 1 "On" ;
VAL_ 821 BCM_ReFogLampOutpCmd 0 "Off" 1 "On" ;
VAL_ 821 BCM_EnaReq_ADB 0 "Inactive" 1 "Active" ;
VAL_ 821 BCM_VehAmbBri 254 "Maximum_value" 255 "Init.value/fault_value" ;
VAL_ 822 ICC_SetAtmLampBri 0 "Level_1" 1 "Level_2" 2 "Level_3" 3 "Level_4" 4 "Level_5" 5 "Level_6" 6 "Level_7" 7 "Level_8" 8 "Level_9" 9 "Level_10" ;
VAL_ 822 ICC_SuspSet 0 "Normal" 1 "Sport" 2 "Off_Road" 3 "Invalid" ;
VAL_ 822 ICC_OTAInhbRdy 0 "Initial" 1 "Inhibit" 2 "Not_Inhibit" 3 "Invalid" ;
VAL_ 822 ICC_AtmLampOpenCmd 0 "turn_off_ambient_light" 1 "turn_on_ambient_light" ;
VAL_ 822 ICC_SteerAssiSet 0 "Initial_value" 1 "Normal" 2 "ECO" 3 "Sport" 7 "Invalid" ;
VAL_ 822 ICC_SetStorageBriLvl 0 "Level_1" 1 "Level_2" 2 "Level_3" 3 "Level_4" 4 "Level_5" 5 "Level_6" 6 "Level_7" 7 "Level_8" 8 "Level_9" 9 "Level_10" ;
VAL_ 822 ICC_HDCSwtSig 0 "No_Pressed" 1 "Pressed" ;
VAL_ 822 ICC_ESPSwtSig 0 "Normal" 1 "Sport" ;
VAL_ 822 ICC_ReqCalifModHMIBtn 0 "Init,_No_request" 1 "Request_California_Mode_OFF" 2 "Request_California_Mode_ON" 3 "Reserved" ;
VAL_ 822 ICC_iTPMSResetSig 0 "no_reset" 1 "reset" 2 "Reserved" 3 "Invalid" ;
VAL_ 822 ICC_WIFIOnOffSig 0 "Invalid" 1 "ON" 2 "OFF" 3 "Reserved" ;
VAL_ 822 ICC_LeMirrAlrmLampFlt 0 "No_Failure" 1 "Failure" ;
VAL_ 822 ICC_RiMirrAlrmLampFlt 0 "No_Failure" 1 "Failure" ;
VAL_ 822 ICC_PhoneSt 0 "Init" 1 "Not_active" 2 "Active" 3 "Error" ;
VAL_ 822 ICC_SpeechSt 0 "Init" 1 "Not_active" 2 "Active" 3 "Error" ;
VAL_ 822 ICC_RemReqFb 0 "Idle" 1 "Successful" 2 "Failed" 3 "Processing" ;
VAL_ 822 ICC_SpdLimFdb 0 "Idle" 1 "Successful" 2 "Failed" 3 "Processing" ;
VAL_ 822 ICC_OTARdy_Fb 0 "Initial" 1 "Ready" 2 "Not_Ready" 3 "Invalid" ;
VAL_ 823 OHC_FctCrtSts 0 "turn_off_ambient_light" 1 "turn_on_ambient_light" 2 "fault_state" 3 "Reserved" ;
VAL_ 823 OHC_CrtGroup4RearComp 0 "Off" 1 "On" 2 "fault" 3 "Reserved" ;
VAL_ 823 OHC_SplyGroup5OutpSts 0 "Off" 1 "On" 2 "fault" 3 "Reserved" ;
VAL_ 823 OHC_CrtBri 0 "Level_1" 1 "Level_2" 2 "Level_3" 3 "Level_4" 4 "Level_5" 5 "Level_6" 6 "Level_7" 7 "Level_8" 8 "Level_9" 9 "Level_10" ;
VAL_ 835 BCM_RemReqFb 0 "Idle" 1 "Successful" 2 "Failed" 3 "Processing" ;
VAL_ 835 BCM_APASwSts 0 "Not_active_Not_enabled" 1 "Active_enable" 2 "Reserved" 3 "Invalid" ;
VAL_ 835 BCM_FrntHoodLidSts 0 "Closed" 1 "Open" ;
VAL_ 835 BCM_SunroofAntipinchSts 0 "Inactive" 1 "Active" ;
VAL_ 835 BCM_FrntDrDoorLockSts 0 "Lock" 1 "Unlock" ;
VAL_ 835 BCM_TrRelsSwtSts 0 "Inactive" 1 "Active" ;
VAL_ 835 BCM_LockAllDoorCmd 0 "Inactive" 1 "Active" ;
VAL_ 835 BCM_DrFrntDoorSts 0 "Closed" 1 "Open" ;
VAL_ 835 BCM_PasFrntDoorSts 0 "Closed" 1 "Open" ;
VAL_ 835 BCM_AntithftSts 0 "Anti_Theft_system_Unset" 1 "Anti_Theft_system_Partially_Set" 2 "Anti_Theft_system_Set" 3 "Anti_Theft_alarm_triggered" ;
VAL_ 835 BCM_CenLockSwtSts 0 "Inactive" 1 "Unlock" 2 "Lock" 3 "Reserved" ;
VAL_ 835 BCM_DoorUnlockSetFb 0 "driver's_door" 1 "All_doors" ;
VAL_ 835 BCM_RiReDoorSts 0 "Closed" 1 "Open" ;
VAL_ 835 BCM_LeReDoorSts 0 "Closed" 1 "Open" ;
VAL_ 835 BCM_LeFrntWinSts 0 "Closed" 1 "Open" ;
VAL_ 835 BCM_RiFrntWinSts 0 "Closed" 1 "Open" ;
VAL_ 835 BCM_LeReWinSts 0 "Closed" 1 "Open" ;
VAL_ 835 BCM_RiReWinSt 0 "Closed" 1 "Open" ;
VAL_ 835 BCM_SunroofSts 0 "Closed" 1 "Open" ;
VAL_ 835 BCM_FolwMeSetStsFb 0 "Follow_Me_Closed" 1 "15" 2 "30" 3 "45" 4 "60" ;
VAL_ 835 BCM_DrvrDoorUnlckOutpCmd 0 "Inactive" 1 "Active" ;
VAL_ 835 BCM_PassDoorUnlckOutpCmd 0 "Inactive" 1 "Active" ;
VAL_ 835 BCM_LeDRLOutpCmd 0 "Off" 1 "On" ;
VAL_ 835 BCM_RiDRLOutpCmd 0 "Off" 1 "On" ;
VAL_ 835 BCM_ArmedClsWinSetSts 0 "Inactive" 1 "Active" ;
VAL_ 835 BCM_OffAutoUnlckSetSts 0 "Inactive" 1 "Active" ;
VAL_ 835 BCM_WarnVbrnSts 0 "Not_Active" 1 "Active" ;
VAL_ 835 BCM_SunroofOpenAr 0 "Horizontal_sliding_zone" 1 "Vertical_inclined_zone" ;
VAL_ 835 BCM_SteerWhlVbrnAlrmAvl 0 "Available" 1 "Not_Available_available" 2 "Failure_failed" 3 "Reserved" ;
VAL_ 835 BCM_SunroofRunngSts 0 "Stopped" 1 "Opening_Tilt" 2 "Closing_Tilt" 3 "Opening_Slide" 4 "Closing_Slide" 5 "Reversing_(AP/Stall)" 6 "Moving_Uninitialized" 7 "Reserved" ;
VAL_ 835 BCM_MirrCmd 0 "Inactive" 1 "Fold" 2 "Unfold" 3 "Not_Used" ;
VAL_ 840 TRM_OTARdy_Fb 0 "Initial" 1 "Ready" 2 "Not_Ready" 3 "Invalid" ;
VAL_ 840 TRM_TrailerSts 0 "trailer_not_connected" 1 "trailer_connected" ;
VAL_ 840 TRM_WakeupSrc 0 "Wake_up_by_CAN" 1 "Wake_up_by_LIN_(USM)" 2 "Wake_up_by_trailer_attach" 3 "Wake_up_by_trailer_detach" ;
VAL_ 840 TRM_IndcrLeSts 0 "indicator_left_ok" 1 "indicator_left_faulty" ;
VAL_ 840 TRM_IndcrRiSts 0 "indicator_right_ok" 1 "indicator_right_faulty" ;
VAL_ 840 TRM_TailLiLeSts 0 "tail_light_left_ok" 1 "tail_light_left_faulty" ;
VAL_ 840 TRM_TailLiRiSts 0 "tail_light_right_ok" 1 "tail_light_right_faulty" ;
VAL_ 840 TRM_StopLiSts 0 "stop_light_ok" 1 "stop_light_faulty" ;
VAL_ 840 TRM_RvsSts 0 "reverse_light_ok" 1 "reverse_light_faulty" ;
VAL_ 840 TRM_FogLiSts 0 "fog_light_ok" 1 "fog_light_faulty" ;
VAL_ 840 TRM_HitchSts 0 "Safety_state_not_set" 1 "Tow-bar_is_unsafe" 2 "Tow-bar_is_safe" 3 "Tow-bar_safety" ;
VAL_ 852 MCU_R_ReqZeroTqFlg 0 "No_request" 1 "With_request" ;
VAL_ 852 MCU_R_CrtSts 0 "Standby_state" 1 "Electric_state" 2 "Generation_state" 3 "Reserved" ;
VAL_ 852 MCU_R_MaxPwrGennTq 1023 "Invalid" ;
VAL_ 852 MCU_R_MaxElecTq 1023 "Invalid" ;
VAL_ 852 MCU_R_MOT_T 511 "Invalid" ;
VAL_ 852 MCU_R_IGBTT 511 "Invalid" ;
VAL_ 853 MCU_F_ReqZeroTqFlg 0 "No_request" 1 "With_request" ;
VAL_ 853 MCU_F_CrtSts 0 "Standby_state" 1 "Electric_state" 2 "Generation_state" 3 "Reserved" ;
VAL_ 853 MCU_F_MaxPwrGennTq 1023 "Invalid" ;
VAL_ 853 MCU_F_MaxElecTq 1023 "Invalid" ;
VAL_ 853 MCU_F_MOT_T 511 "Invalid" ;
VAL_ 853 MCU_F_IGBTT 511 "Invalid" ;
VAL_ 856 VCU_KickdwnFlg 0 "Inactive" 1 "Active" 3 "Invalid" ;
VAL_ 856 VCU_EPedlEnaSig 0 "Not_enabled" 1 "Enable" ;
VAL_ 856 VCU_ComLostFlt_ESP 0 "Normal" 1 "Abnormal" ;
VAL_ 856 VCU_ComFlt_iBooster 0 "Normal" 1 "Abnormal" ;
VAL_ 856 VCU_RegenLvlFb 0 "Off" 1 "Normal" 2 "High" 3 "Invalid" ;
VAL_ 856 VCU_AccelModFb 0 "Low" 1 "Medium_" 2 "High" 3 "Invalid" ;
VAL_ 856 VCU_EPedlStsFb 0 "OnePedalDrive" 1 "Roll" 2 "Creep" 3 "Invalid" ;
VAL_ 856 VCU_CcTrgSpdDisp 255 "no_display" ;
VAL_ 856 VCU_Sts_CC_ICC 0 "Off" 1 "Initialization" 2 "Standby" 3 "Active" 4 "Override" 7 "Deactivation_brake" 8 "Deactivation_other" 9 "Failure_reversible" 10 "Failure_irreversible" ;
VAL_ 856 VCU_CCIconDisp 0 "No_Display" 1 "White" 2 "Green" 3 "Fault" ;
VAL_ 856 VCU_DispSpdUnit_CC 0 "KMH" 1 "MPH" ;
VAL_ 856 VCU_BoostEnStat 0 "Default" 1 "Boost_unavailable:_Max_activation_number_exceeded" 2 "Boost_unavailable:_Drive_Mode" 3 "Boost_unavailable:_EDU_Coolant_Inlet_Temperature" 4 "Boost_unavailable:_EDU_Coolant_Flow" 5 "Boost_unavailable:_EDU_Stator/_Rotor_Temperature" 6 "Boost_unavailable:_EDU_Decoupling_Unit_open" 7 "Boost_unavailable:_Battery_limitation" 8 "Boost_available" 9 "Boost_active" 10 "Boost_unavailable:_vehicle_not_in_standstil" 11 "Boost_unavailable:_multiple_causes" 15 "invalid" ;
VAL_ 856 VCU_OTARdy_Fb 0 "Initial" 1 "Ready" 2 "Not_Ready" 3 "Invalid" ;
VAL_ 856 VCU_OTA_ECUInhb_Req 0 "Init" 1 "Inhibit_Request" 2 "No_Inhibit_request" 3 "Invalid" ;
VAL_ 856 VCU_OTAVehCdnChk_ASIL 0 "OTA_veh_cond_not_ok" 1 "OTA_veh_cond_ok" 2 "Fault" 3 "Invalid" ;
VAL_ 856 VCU_OTAVehInhb_ASIL_Fb 0 "Inhibition_not_ok" 1 "Inhibition_ok" 2 "Reserved" 3 "Invalid" ;
VAL_ 868 BCM_OTARdy_Fb 0 "Initial" 1 "Ready" 2 "Not_Ready" 3 "Invalid" ;
VAL_ 868 BCM_OTAInhbRdy 0 "Initial" 1 "Inhibit" 2 "Not_Inhibit" 3 "Invalid" ;
VAL_ 868 BCM_SBRMatStPass 0 "Seat_not_occupied" 1 "Seat_occupied" 2 "Fault" 3 "Invalid" ;
VAL_ 868 BCM_BucSwtSt2ndRowLeft 0 "Buckled" 1 "Not_buckled" 2 "Fault" 3 "Invalid" ;
VAL_ 868 BCM_BucSwtSt2ndRowMid 0 "Buckled" 1 "Not_buckled" 2 "Fault" 3 "Invalid" ;
VAL_ 868 BCM_BucSwtSt2ndRowRight 0 "Buckled" 1 "Not_buckled" 2 "Fault" 3 "Invalid" ;
VAL_ 868 BCM_BucSwtSt3rdRowLeft 0 "Buckled" 1 "Not_buckled" 2 "Fault" 3 "Invalid" ;
VAL_ 868 BCM_BucSwtSt3rdRowRight 0 "Buckled" 1 "Not_buckled" 2 "Fault" 3 "Invalid" ;
VAL_ 868 BCM_SBRMatSt2ndRowLeft 0 "Seat_not_occupied" 1 "Seat_occupied" 2 "Fault" 3 "Invalid" ;
VAL_ 868 BCM_SBRMatSt2ndRowMid 0 "Seat_not_occupied" 1 "Seat_occupied" 2 "Fault" 3 "Invalid" ;
VAL_ 868 BCM_SBRMatSt2ndRowRight 0 "Seat_not_occupied" 1 "Seat_occupied" 2 "Fault" 3 "Invalid" ;
VAL_ 868 BCM_SBRMat3rdRowLeft 0 "Seat_not_occupied" 1 "Seat_occupied" 2 "Fault" 3 "Invalid" ;
VAL_ 868 BCM_SBRMat3rdRowRight 0 "Seat_not_occupied" 1 "Seat_occupied" 2 "Fault" 3 "Invalid" ;
VAL_ 883 ECC_CrtSts 0 "Load_initialization" 1 "Low-voltage_state" 2 "Local_high_voltage_state" 3 "Local_charge_state" 4 "Remote_working_state" 5 "High_voltage_discharge_state" 6 "Delay_state" ;
VAL_ 883 ECC_IninSts 0 "Incomplete_initialization" 1 "initialization_completed" ;
VAL_ 883 ECC_PwrSysHeatMngtSts 0 "No_action" 1 "Self_circulation_state" 2 "Forced_cooling" 3 "Reserved" ;
VAL_ 883 ECC_ACSts 0 "Off_state" 1 "ON_state" ;
VAL_ 883 ECC_AirClnSts 0 "Not_ON" 1 "On" ;
VAL_ 883 ECC_WindSpdSts 0 "Windless_gear" 1 "First_gear_of_wind_speed" 2 "Wind_speed_second_gear" 3 "third_gear_of_wind_speed" 4 "wind_speed_fourth_gear" 5 "Wind_speed_fifth_gear" 6 "Wind_speed_six" 7 "Wind_speed_seven_gear" ;
VAL_ 883 ECC_BackRowAirOutlModSts 0 "Rear_face_blowing" 1 "Face_blowing_foot_blowing_of_rear_row" 2 "Foot_blowing_of_rear_row" 3 "Back_row_cutoff" ;
VAL_ 883 ECC_DrvrTSetSts 0 "Inactive" 36 "18℃" 37 "18.5℃" 38 "19℃" 39 "19.5℃" 40 "20℃" 41 "20.5℃" 42 "21℃" 43 "21.5℃" 44 "22℃" 45 "22.5℃" 46 "23℃" 47 "23.5℃" 48 "24℃" 49 "24.5℃" 50 "25℃" 51 "25.5℃" 52 "26℃" 53 "26.5℃" 54 "27℃" 55 "27.5℃" 56 "28℃" 57 "28.5℃" 58 "29℃" 59 "29.5℃" 60 "30℃" 61 "30.5℃" 62 "31℃" 63 "31.5℃" 64 "32℃" 255 "Invalid" ;
VAL_ 883 ECC_PassTSetSts 0 "Inactive" 36 "18℃" 37 "18.5℃" 38 "19℃" 39 "19.5℃" 40 "20℃" 41 "20.5℃" 42 "21℃" 43 "21.5℃" 44 "22℃" 45 "22.5℃" 46 "23℃" 47 "23.5℃" 48 "24℃" 49 "24.5℃" 50 "25℃" 51 "25.5℃" 52 "26℃" 53 "26.5℃" 54 "27℃" 55 "27.5℃" 56 "28℃" 57 "28.5℃" 58 "29℃" 59 "29.5℃" 60 "30℃" 61 "30.5℃" 62 "31℃" 63 "31.5℃" 64 "32℃" 255 "Invalid" ;
VAL_ 883 ECC_HeatSts 0 "Off_state" 1 "ON_state" ;
VAL_ 883 ECC_AUTOSts 0 "Off" 1 "On" ;
VAL_ 883 ECC_SYNCSts 0 "Off" 1 "On" ;
VAL_ 883 ECC_InfoSysWrmColdDisp 0 "No_action" 1 "Natural_wind" 2 "Cold_air" 3 "Hot_air" ;
VAL_ 883 ECC_CircSts 0 "Inner_circulation_state" 1 "outer_circulation_state" ;
VAL_ 883 ECC_ParticleConcVld 0 "Initializing" 1 "Valid" 2 "Invalid" 3 "Reserved" ;
VAL_ 883 ECC_OutdT 255 "Invalid" ;
VAL_ 883 ECC_OutdTVld 0 "Initializing" 1 "Valid" 2 "Invalid" 3 "Reserved" ;
VAL_ 883 ECC_MaxFrntDefrst 0 "Not_opened" 1 "Open" ;
VAL_ 883 ECC_HeatMngtSysFlt 0 "Normal" 1 "Fault" ;
VAL_ 883 ECC_HeatMngtFctLim 0 "Functional" 1 "function_limit" ;
VAL_ 883 ECC_DrvrAirOutlMod 0 "Reserved" 1 "driver_face_blowing_mode" 2 "driver_face_blowing/foot_blowing_mode" 3 "Driver_foot_blowing_mode" 4 "driver_foot/window_mode" 5 "Window_blowing_mode" ;
VAL_ 883 ECC_PassAirOutlMod 0 "Reserved" 1 "front_passenger_face_blowing_mode" 2 "front_passenger_face_blowing/foot_blowing_mode" 3 "Front_passenger_foot_mode" 4 "Front_passenger_foot/window_mode" ;
VAL_ 883 ECC_RemSts 0 "Standby" 1 "Working" 2 "Fault" 3 "Reserved" ;
VAL_ 883 ECC_OTAInhbRdy 0 "Initial" 1 "Inhibit" 2 "Not_Inhibit" 3 "Invalid" ;
VAL_ 888 ECC_LeOutlUpDwnMotActvSts 0 "No_Action" 1 "Level_1_upwards_by_100%" 2 "Level_2_upwards_80%" 3 "Level_3_upwards_60%" 4 "Level_4_upwards_40%" 5 "Level_5_up_20%" 6 "Level_6_positive_direction" 7 "Level_7_adjustment_downward_20%" 8 "Level_8_adjustment_downward_40%" 9 "Level_9_adjustment_downward_60%" 10 "Level_10_Adjustment_Downward_by_80%" 11 "Level_11_Adjust_downward_100%" 15 "Invalid" ;
VAL_ 888 ECC_LeOutlLeRiMotActvSts 0 "No_Action" 1 "Level_1_to_the_left_100%" 2 "Level_2_to_the_left_80%" 3 "Level_3_left_adjustment_60%" 4 "Level_4_adjustment_to_the_left_40%" 5 "Level_5_to_the_left_20%" 6 "Level_6_positive_direction" 7 "Level_7_adjusted_to_the_right_by_20%" 8 "Level_8_adjustment_to_the_right_40%" 9 "Level_9_adjustment_to_the_right_60%" 10 "Level_10_adjust_80%_to_the_right" 11 "Level_11_adjusting_100%_to_the_right" 12 "closed" 15 "Invalid" ;
VAL_ 888 ECC_LeOutlDamprMotActvSts 0 "No_Action" 1 "Level_1_Throttle_opening_0%" 2 "Level_2_throttle_opening_10%" 3 "Level_3_Throttle_Opening_20%" 4 "Level_4_Throttle_Opening_30%" 5 "Level_5_Throttle_Opening_40%" 6 "Level_6_throttle_opening_50%" 7 "Level_7_throttle_opening_60%" 8 "Level_8_Throttle_70%" 9 "Level_9_throttle_opening_80%" 10 "Level_10_throttle_openning_90%" 11 "Level_11_throttle_opening_100%" 15 "Invalid" ;
VAL_ 888 ECC_MidLeOutlUpDwnMotActvSts 0 "No_Action" 1 "Level_1_upwards_by_100%" 2 "Level_2_upwards_80%" 3 "Level_3_upwards_60%" 4 "Level_4_upwards_40%" 5 "Level_5_up_20%" 6 "Level_6_positive_direction" 7 "Level_7_adjustment_downward_20%" 8 "Level_8_adjustment_downward_40%" 9 "Level_9_adjustment_downward_60%" 10 "Level_10_Adjustment_Downward_by_80%" 11 "Level_11_Adjust_downward_100%" 15 "Invalid" ;
VAL_ 888 ECC_MidLeOutlLeRiMotActvSts 0 "No_Action" 1 "Level_1_to_the_left_100%" 2 "Level_2_to_the_left_80%" 3 "Level_3_left_adjustment_60%" 4 "Level_4_adjustment_to_the_left_40%" 5 "Level_5_to_the_left_20%" 6 "Level_6_positive_direction" 7 "Level_7_adjusted_to_the_right_by_20%" 8 "Level_8_adjustment_to_the_right_40%" 9 "Level_9_adjustment_to_the_right_60%" 10 "Level_10_adjust_80%_to_the_right" 11 "Level_11_adjusting_100%_to_the_right" 12 "closed" 15 "Invalid" ;
VAL_ 888 ECC_MidLeOutlDamprMotActvSts 0 "No_Action" 1 "Level_1_Throttle_opening_0%" 2 "Level_2_throttle_opening_10%" 3 "Level_3_Throttle_Opening_20%" 4 "Level_4_Throttle_Opening_30%" 5 "Level_5_Throttle_Opening_40%" 6 "Level_6_throttle_opening_50%" 7 "Level_7_throttle_opening_60%" 8 "Level_8_Throttle_70%" 9 "Level_9_throttle_opening_80%" 10 "Level_10_throttle_openning_90%" 11 "Level_11_throttle_opening_100%" 15 "Invalid" ;
VAL_ 888 ECC_MidRiOutlUpDwnMotActvSts 0 "No_Action" 1 "Level_1_upwards_by_100%" 2 "Level_2_upwards_80%" 3 "Level_3_upwards_60%" 4 "Level_4_upwards_40%" 5 "Level_5_up_20%" 6 "Level_6_positive_direction" 7 "Level_7_adjustment_downward_20%" 8 "Level_8_adjustment_downward_40%" 9 "Level_9_adjustment_downward_60%" 10 "Level_10_Adjustment_Downward_by_80%" 11 "Level_11_Adjust_downward_100%" 15 "Invalid" ;
VAL_ 888 ECC_MidRiOutlLeRiMotActvSts 0 "No_Action" 1 "Level_1_to_the_left_100%" 2 "Level_2_to_the_left_80%" 3 "Level_3_left_adjustment_60%" 4 "Level_4_adjustment_to_the_left_40%" 5 "Level_5_to_the_left_20%" 6 "Level_6_positive_direction" 7 "Level_7_adjusted_to_the_right_by_20%" 8 "Level_8_adjustment_to_the_right_40%" 9 "Level_9_adjustment_to_the_right_60%" 10 "Level_10_adjust_80%_to_the_right" 11 "Level_11_adjusting_100%_to_the_right" 12 "closed" 15 "Invalid" ;
VAL_ 888 ECC_MidRiOutlDamprMotActvSts 0 "No_Action" 1 "Level_1_Throttle_opening_0%" 2 "Level_2_throttle_opening_10%" 3 "Level_3_Throttle_Opening_20%" 4 "Level_4_Throttle_Opening_30%" 5 "Level_5_Throttle_Opening_40%" 6 "Level_6_throttle_opening_50%" 7 "Level_7_throttle_opening_60%" 8 "Level_8_Throttle_70%" 9 "Level_9_throttle_opening_80%" 10 "Level_10_throttle_openning_90%" 11 "Level_11_throttle_opening_100%" 15 "Invalid" ;
VAL_ 888 ECC_RiOutlUpDwnMotActvSts 0 "No_Action" 1 "Level_1_upwards_by_100%" 2 "Level_2_upwards_80%" 3 "Level_3_upwards_60%" 4 "Level_4_upwards_40%" 5 "Level_5_up_20%" 6 "Level_6_positive_direction" 7 "Level_7_adjustment_downward_20%" 8 "Level_8_adjustment_downward_40%" 9 "Level_9_adjustment_downward_60%" 10 "Level_10_Adjustment_Downward_by_80%" 11 "Level_11_Adjust_downward_100%" 15 "Invalid" ;
VAL_ 888 ECC_RiOutlLeRiMotActvSts 0 "No_Action" 1 "Level_1_to_the_left_100%" 2 "Level_2_to_the_left_80%" 3 "Level_3_left_adjustment_60%" 4 "Level_4_adjustment_to_the_left_40%" 5 "Level_5_to_the_left_20%" 6 "Level_6_positive_direction" 7 "Level_7_adjusted_to_the_right_by_20%" 8 "Level_8_adjustment_to_the_right_40%" 9 "Level_9_adjustment_to_the_right_60%" 10 "Level_10_adjust_80%_to_the_right" 11 "Level_11_adjusting_100%_to_the_right" 12 "closed" 15 "Invalid" ;
VAL_ 888 ECC_RiOutlDamprMotActvSts 0 "No_Action" 1 "Level_1_Throttle_opening_0%" 2 "Level_2_throttle_opening_10%" 3 "Level_3_Throttle_Opening_20%" 4 "Level_4_Throttle_Opening_30%" 5 "Level_5_Throttle_Opening_40%" 6 "Level_6_throttle_opening_50%" 7 "Level_7_throttle_opening_60%" 8 "Level_8_Throttle_70%" 9 "Level_9_throttle_opening_80%" 10 "Level_10_throttle_openning_90%" 11 "Level_11_throttle_opening_100%" 15 "Invalid" ;
VAL_ 890 ICC_LeOutlUpDwnMotActvCmd 0 "No_Action" 1 "Level_1_upwards_by_100%" 2 "Level_2_upwards_80%" 3 "Level_3_upwards_60%" 4 "Level_4_upwards_40%" 5 "Level_5_up_20%" 6 "Level_6_positive_direction" 7 "Level_7_adjustment_downward_20%" 8 "Level_8_adjustment_downward_40%" 9 "Level_9_adjustment_downward_60%" 10 "Level_10_Adjustment_Downward_by_80%" 11 "Level_11_Adjust_downward_100%" 15 "Invalid" ;
VAL_ 890 ICC_LeOutlLeRiMotActvCmd 0 "No_Action" 1 "Level_1_to_the_left_100%" 2 "Level_2_to_the_left_80%" 3 "Level_3_left_adjustment_60%" 4 "Level_4_adjustment_to_the_left_40%" 5 "Level_5_to_the_left_20%" 6 "Level_6_positive_direction" 7 "Level_7_adjusted_to_the_right_by_20%" 8 "Level_8_adjustment_to_the_right_40%" 9 "Level_9_adjustment_to_the_right_60%" 10 "Level_10_adjust_80%_to_the_right" 11 "Level_11_adjusting_100%_to_the_right" 12 "Closed" 15 "Invalid" ;
VAL_ 890 ICC_LeOutlDamprMotActvCmd 0 "No_Action" 1 "Level_1_Throttle_opening_0%" 2 "Level_2_throttle_opening_10%" 3 "Level_3_Throttle_Opening_20%" 4 "Level_4_Throttle_Opening_30%" 5 "Level_5_Throttle_Opening_40%" 6 "Level_6_throttle_opening_50%" 7 "Level_7_throttle_opening_60%" 8 "Level_8_Throttle_70%" 9 "Level_9_throttle_opening_80%" 10 "Level_10_throttle_openning_90%" 11 "Level_11_throttle_opening_100%" 15 "Invalid" ;
VAL_ 890 ICC_MidLeOutlUpDwnMotActvCmd 0 "No_Action" 1 "Level_1_upwards_by_100%" 2 "Level_2_upwards_80%" 3 "Level_3_upwards_60%" 4 "Level_4_upwards_40%" 5 "Level_5_up_20%" 6 "Level_6_positive_direction" 7 "Level_7_adjustment_downward_20%" 8 "Level_8_adjustment_downward_40%" 9 "Level_9_adjustment_downward_60%" 10 "Level_10_Adjustment_Downward_by_80%" 11 "Level_11_Adjust_downward_100%" 15 "Invalid" ;
VAL_ 890 ICC_MidLeOutlLeRiMotActvCmd 0 "No_Action" 1 "Level_1_to_the_left_100%" 2 "Level_2_to_the_left_80%" 3 "Level_3_left_adjustment_60%" 4 "Level_4_adjustment_to_the_left_40%" 5 "Level_5_to_the_left_20%" 6 "Level_6_positive_direction" 7 "Level_7_adjusted_to_the_right_by_20%" 8 "Level_8_adjustment_to_the_right_40%" 9 "Level_9_adjustment_to_the_right_60%" 10 "Level_10_adjust_80%_to_the_right" 11 "Level_11_adjusting_100%_to_the_right" 12 "Closed" 15 "Invalid" ;
VAL_ 890 ICC_MidLeOutlDamprMotActvCmd 0 "No_Action" 1 "Level_1_Throttle_opening_0%" 2 "Level_2_throttle_opening_10%" 3 "Level_3_Throttle_Opening_20%" 4 "Level_4_Throttle_Opening_30%" 5 "Level_5_Throttle_Opening_40%" 6 "Level_6_throttle_opening_50%" 7 "Level_7_throttle_opening_60%" 8 "Level_8_Throttle_70%" 9 "Level_9_throttle_opening_80%" 10 "Level_10_throttle_openning_90%" 11 "Level_11_throttle_opening_100%" 15 "Invalid" ;
VAL_ 890 ICC_MidRiOutlUpDwnMotActvCmd 0 "No_Action" 1 "Level_1_upwards_by_100%" 2 "Level_2_upwards_80%" 3 "Level_3_upwards_60%" 4 "Level_4_upwards_40%" 5 "Level_5_up_20%" 6 "Level_6_positive_direction" 7 "Level_7_adjustment_downward_20%" 8 "Level_8_adjustment_downward_40%" 9 "Level_9_adjustment_downward_60%" 10 "Level_10_Adjustment_Downward_by_80%" 11 "Level_11_Adjust_downward_100%" 15 "Invalid" ;
VAL_ 890 ICC_MidRiOutlLeRiMotActvCmd 0 "No_Action" 1 "Level_1_to_the_left_100%" 2 "Level_2_to_the_left_80%" 3 "Level_3_left_adjustment_60%" 4 "Level_4_adjustment_to_the_left_40%" 5 "Level_5_to_the_left_20%" 6 "Level_6_positive_direction" 7 "Level_7_adjusted_to_the_right_by_20%" 8 "Level_8_adjustment_to_the_right_40%" 9 "Level_9_adjustment_to_the_right_60%" 10 "Level_10_adjust_80%_to_the_right" 11 "Level_11_adjusting_100%_to_the_right" 12 "Closed" 15 "Invalid" ;
VAL_ 890 ICC_MidRiOutlDamprMotActvCmd 0 "No_Action" 1 "Level_1_Throttle_opening_0%" 2 "Level_2_throttle_opening_10%" 3 "Level_3_Throttle_Opening_20%" 4 "Level_4_Throttle_Opening_30%" 5 "Level_5_Throttle_Opening_40%" 6 "Level_6_throttle_opening_50%" 7 "Level_7_throttle_opening_60%" 8 "Level_8_Throttle_70%" 9 "Level_9_throttle_opening_80%" 10 "Level_10_throttle_openning_90%" 11 "Level_11_throttle_opening_100%" 15 "Invalid" ;
VAL_ 890 ICC_RiOutlUpDwnMotActvCmd 0 "No_Action" 1 "Level_1_upwards_by_100%" 2 "Level_2_upwards_80%" 3 "Level_3_upwards_60%" 4 "Level_4_upwards_40%" 5 "Level_5_up_20%" 6 "Level_6_positive_direction" 7 "Level_7_adjustment_downward_20%" 8 "Level_8_adjustment_downward_40%" 9 "Level_9_adjustment_downward_60%" 10 "Level_10_Adjustment_Downward_by_80%" 11 "Level_11_Adjust_downward_100%" 15 "Invalid" ;
VAL_ 890 ICC_RiOutlLeRiMotActvCmd 0 "No_Action" 1 "Level_1_to_the_left_100%" 2 "Level_2_to_the_left_80%" 3 "Level_3_left_adjustment_60%" 4 "Level_4_adjustment_to_the_left_40%" 5 "Level_5_to_the_left_20%" 6 "Level_6_positive_direction" 7 "Level_7_adjusted_to_the_right_by_20%" 8 "Level_8_adjustment_to_the_right_40%" 9 "Level_9_adjustment_to_the_right_60%" 10 "Level_10_adjust_80%_to_the_right" 11 "Level_11_adjusting_100%_to_the_right" 12 "Closed" 15 "Invalid" ;
VAL_ 890 ICC_RiOutlDamprMotActvCmd 0 "No_Action" 1 "Level_1_Throttle_opening_0%" 2 "Level_2_throttle_opening_10%" 3 "Level_3_Throttle_Opening_20%" 4 "Level_4_Throttle_Opening_30%" 5 "Level_5_Throttle_Opening_40%" 6 "Level_6_throttle_opening_50%" 7 "Level_7_throttle_opening_60%" 8 "Level_8_Throttle_70%" 9 "Level_9_throttle_opening_80%" 10 "Level_10_throttle_openning_90%" 11 "Level_11_throttle_opening_100%" 15 "Invalid" ;
VAL_ 897 RAC_OnOff 0 "No_Pressed" 1 "Pressed" 2 "Long_Press" 3 "Reserved" ;
VAL_ 897 RAC_ReOperPanSts 0 "off" 1 "on" ;
VAL_ 897 RAC_ReOperPanLockSts 0 "off" 1 "on" ;
VAL_ 897 RAC_BackRowAirOutlModReq 0 "Inactive" 1 "Rear_face_blowing" 2 "Face_blowing_foot_blowing_of_rear_row" 3 "Rear_row_foot_blowing" 4 "Rear_row_cutoff" ;
VAL_ 897 RAC_VolInc 0 "No_Pressed" 1 "Pressed" 2 "Long_Press" 3 "Reserved" ;
VAL_ 897 RAC_VolDec 0 "No_Pressed" 1 "Pressed" 2 "Long_Press" 3 "Reserved" ;
VAL_ 897 RAC_VolCtrl 0 "Inactive" 1 "Unmute" 2 "Mute" 3 "Reserved" ;
VAL_ 897 RAC_TempCtrlnc 0 "No_Pressed" 1 "Pressed" 2 "Long_Press" 3 "Reserved" ;
VAL_ 897 RAC_TempCtrDec 0 "No_Pressed" 1 "Pressed" 2 "Long_Press" 3 "Reserved" ;
VAL_ 897 RAC_BlowCtrInc 0 "No_Pressed" 1 "Pressed" 2 "Long_Press" 3 "Reserved" ;
VAL_ 897 RAC_BlowCtrDec 0 "No_Pressed" 1 "Pressed" 2 "Long_Press" 3 "Reserved" ;
VAL_ 897 RAC_AirOutlLeftBtn 0 "No_Pressed" 1 "Pressed" 2 "Long_Press" 3 "Reserved" ;
VAL_ 897 RAC_AirOutlRightBtn 0 "No_Pressed" 1 "Pressed" 2 "Long_Press" 3 "Reserved" ;
VAL_ 897 RAC_SeatHRearLeftBtn 0 "No_Pressed" 1 "Pressed" 2 "Long_Press" 3 "Reserved" ;
VAL_ 897 RAC_SeatHRearRightBtn 0 "No_Pressed" 1 "Pressed" 2 "Long_Press" 3 "Reserved" ;
VAL_ 898 BMS_OTARdy_Fb 0 "Initial" 1 "Ready" 2 "Not_Ready" 3 "Invalid" ;
VAL_ 898 BMS_CellMinT 255 "Invalid" ;
VAL_ 898 BMS_CellMaxT 255 "Invalid" ;
VAL_ 898 BMS_BattAvrgT 255 "Invalid" ;
VAL_ 898 BMS_PwrBattHeatgMngDmd 0 "BMS_initialisation" 1 "Heating_demand" 2 "Cooling_demand" 3 "cycling" ;
VAL_ 898 BMS_ECCSysAllwDwnPwrCmd 0 "Power_reduction_not_allowed" 1 "Power_reduction_allowed" ;
VAL_ 898 BMS_BattInlTDmd 255 "Invalid" ;
VAL_ 899 MCU_F_ParkLockStatus_EV 0 "Setup" 1 "Normal" 2 "Ready_for_shutdown" 3 "Shutdown_active" 4 "Shutdown_finished" 5 "Teachin_start_condition_failed" 6 "Teachin_start_conditions_ok" 7 "Teachin_active" 8 "Teachin_failed" 15 "Error" ;
VAL_ 899 MCU_F_PrkLckStatNrmlOp_EV 0 "state_undefined" 1 "Parklock_engaged" 2 "Parklock_disengaged" 5 "Parklock_in_Transition" 6 "Reserved" 7 "Error" ;
VAL_ 900 ICC_PreHeatDepartSet 0 "init" 1 "Deactivated" 2 "Start_now" 3 "Start_with_timer" ;
VAL_ 900 ICC_MonPreHeatDepartSet 0 "FALSE" 1 "TRUE" ;
VAL_ 900 ICC_TuePreHeatDepartSet 0 "FALSE" 1 "TRUE" ;
VAL_ 900 ICC_WedPreHeatDepartSet 0 "FALSE" 1 "TRUE" ;
VAL_ 900 ICC_ThuPreHeatDepartSet 0 "FALSE" 1 "TRUE" ;
VAL_ 900 ICC_FriPreHeatDepartSet 0 "FALSE" 1 "TRUE" ;
VAL_ 900 ICC_SatPreHeatDepartSet 0 "FALSE" 1 "TRUE" ;
VAL_ 900 ICC_SunPreHeatDepartSet 0 "FALSE" 1 "TRUE" ;
VAL_ 900 ICC_SchedChargSet 0 "init" 1 "Deactivated" 2 "Start_now" 3 "Start_with_timer" ;
VAL_ 900 ICC_MonSchedChargSet 0 "FALSE" 1 "TRUE" ;
VAL_ 900 ICC_TueSchedChargSet 0 "FALSE" 1 "TRUE" ;
VAL_ 900 ICC_WedSchedChargSet 0 "FALSE" 1 "TRUE" ;
VAL_ 900 ICC_ThuSchedChargSet 0 "FALSE" 1 "TRUE" ;
VAL_ 900 ICC_FriSchedChargSet 0 "FALSE" 1 "TRUE" ;
VAL_ 900 ICC_SatSchedChargSet 0 "FALSE" 1 "TRUE" ;
VAL_ 900 ICC_SunSchedChargSet 0 "FALSE" 1 "TRUE" ;
VAL_ 900 ICC_PreHeatDepartSetFb 0 "Invalid" 1 "Successful" 2 "Failed" 3 "Reserved" ;
VAL_ 902 BCM_HeatedSteerWhlSt 0 "OFF_status" 1 "SWH_ON" 2 "Reserved" 3 "Invalid" ;
VAL_ 902 BCM_RealT 0 "no_signal" 127 "Sensor_fault" ;
VAL_ 902 BCM_HSWCURspEror 0 "No_Error" 1 "Error" ;
VAL_ 902 BCM_HeatedSteerWhlSCF 0 "Normal" 1 "LowRes_or_Shurtcut" ;
VAL_ 902 BCM_HeatedSteerWhlOCF 0 "Normal" 1 "Hi-Res_or_Open" ;
VAL_ 902 BCM_HeatedSteerWhlThPro 0 "Normal" 1 "Thermostat_open" ;
VAL_ 902 BCM_ECUFail 0 "OK" 1 "Failure" ;
VAL_ 912 ESP_TPMS_CalSts 0 "RTE_E_CALIB_PROGRESS_NONE" 1 "RTE_E_CALIB_PROGRESS_INIT" 2 "RTE_E_CALIB_PROGRESS_ONGOING" 3 "RTE_E_CALIB_PROGRESS_ENDED" 4 "RTE_E_CALIB_PROGRESS_FAILED" 7 "Signal_Invalid" ;
VAL_ 912 ESP_TPMS_WarnLampFL 0 "No_warning" 1 "general_warning" 2 "Low_pressure_warning" 3 "not_used_Quick_leakage" 6 "Sensor_failure" 7 "Invalid" ;
VAL_ 912 ESP_TPMS_WarnLampFR 0 "No_warning" 1 "not_used_High_pressure_warning" 2 "Low_pressure_warning" 3 "not_used_Quick_leakage" 6 "Sensor_failure" 7 "Invalid" ;
VAL_ 912 ESP_TPMS_WarnLampRL 0 "No_warning" 1 "not_used_High_pressure_warning" 2 "Low_pressure_warning" 3 "not_used_Quick_leakage" 6 "Sensor_failure" 7 "Invalid" ;
VAL_ 912 ESP_TPMS_WarnLampRR 0 "No_warning" 1 "not_used_High_pressure_warning" 2 "Low_pressure_warning" 3 "not_used_Quick_leakage" 6 "Sensor_failure" 7 "Invalid" ;
VAL_ 912 ESP_TPMS_CalPrevnSts 0 "RTE_E_CALIB_PREVENT_NO_PREVENT" 1 "RTE_E_CALIB_PREVENT_CHECK_TIRES" 2 "RTE_E_CALIB_PREVENT_VEHICLE_IS_MOVING" 3 "RTE_E_CALIB_PREVENT_UNAVAILABLE" ;
VAL_ 913 BMS_VehInsulFltDisp 0 "Normal" 1 "Abnormal" ;
VAL_ 913 BMS_PwrBattSysFltDisp 0 "Normal" 1 "Abnormal" ;
VAL_ 913 BMS_PwrBattAvlCp 65535 "Invalid" ;
VAL_ 913 BMS_CellMinTAlrm 0 "No_fault" 1 "Fault" ;
VAL_ 913 BMS_PwrBattThermRunawayAlrm 0 "No_Thermal_Runaway" 1 "Thermal_Runaway_Detected" ;
VAL_ 913 BMS_PwrBattOverT 0 "Normal" 1 "Abnormal" ;
VAL_ 913 BMS_PwrBattInsulSts 0 "Initial_value" 1 "Not_thermally_insulated" 2 "Thermally_insulated" 3 "Thermal_insulation_is_on_for_the_power_battery_is_at_low_temperature" ;
VAL_ 965 AMP_OTAInhbRdy 0 "Initial" 1 "Inhibit" 2 "Not_Inhibit" 3 "Invalid" ;
VAL_ 992 VCU_reqFullEDUCooltFlow 0 "Default" 1 "Active" 2 "Inactive" 3 "Invalid" ;
VAL_ 992 VCU_HVEMBoostModSt 0 "Default" 1 "Allowed" 2 "Denied" 3 "Invalid" ;
VAL_ 992 VCU_MaxBoostCntr 1023 "Invalid" ;
VAL_ 992 VCU_BoostEnStatCoded 8191 "Invalid" ;
VAL_ 1135 TBOX_GPSFixOK 0 "Invalid" 1 "Valid" ;
VAL_ 1135 TBOX_GNSSVelocity 131071 "Invalid_Value" ;
VAL_ 1137 PLGM_UsrSetTrMaxHei 0 "Inactive" ;
VAL_ 1137 PLGM_LiRemdngReq_BCM 0 "No_Blink" 1 "Open" 2 "Closed" 3 "Set_MaxHeight_Successfully" ;
VAL_ 1137 PLGM_SoundRemdngReq_EHU 0 "No_whistle" 1 "moving_process_opening" 2 "Set_maxHeight_successfully" 3 "For_Anti-pinch" 4 "moving_process_closing" 5 "Key_fob/smartphone_in_trunk" ;
VAL_ 1137 PLGM_FctEnaRes 0 "Inactive" 1 "Active" ;
VAL_ 1137 PLGM_SysFltIndcn 0 "No_Failure" 1 "Failure_happened" ;
VAL_ 1137 PLGM_TrActnHandCmd 0 "Inactive" 1 "Open_Request_(Pulling_Up_By_Hand)" 2 "Close_Request_(Pulling_Down_By_Hand)" 3 "Reserved" ;
VAL_ 1137 PLGM_TrSwtStsIndcn 0 "Trunk_Closed" 1 "Trunk_Open_Fully" 2 "Trunk_Halt" 3 "Trunk_Opening" 4 "Trunk_Closing" ;
VAL_ 1137 PLGM_TrLtchStsIndcn 0 "Full_Latched_PawlSwOff_tail_door_lock_full_locking_state" 1 "HalfLatched_StrikerLeverSwOn_LockProcess_The_tail_door_lock_is_half-locked" 2 "Open_PawlSwOn_tail_door_lock_fully_open_state" 3 "Initializing_the_door_lock_power-on_initialization_process" 4 "HalfLatched_StrikerLeverSwOn_Release" 5 "Snowload_tail_door_lock_'snow_load'_state" ;
VAL_ 1137 PLGM_TrSwtTrigOpenReq 0 "Inactive" 1 "Active" ;
VAL_ 1137 PLGM_OperMod 0 "Not_Learnt" 1 "Learnt,_But_Shipping_Mode,_With_Power_Lifting_Or_Closing_Function_Forbidden" 2 "Learnt,_With_Maximum_Height_Customization_Allowed" 3 "Reserved" ;
VAL_ 1137 PLGM_TrSwtSts 0 "Inactive" 1 "Active" ;
VAL_ 1137 PLGM_LimpHomeSts 0 "Inactive" 1 "Active" ;
VAL_ 1137 PLGM_DrvrSwtSts 0 "Inactive" 1 "Active" ;
VAL_ 1137 PLGM_TrInnrSwtSts 0 "Inactive" 1 "ShortPressed_TriggerTrunkAction" 2 "LongPressed_SetUserMaxHeight" 3 "Reserved" ;
VAL_ 1137 PLGM_AntipinchSts 0 "No_Pinch" 1 "Anti-pinch_Happened" ;
VAL_ 1137 PLGM_TrSts 0 "Closed" 1 "Open" ;
VAL_ 1137 PLGM_OTAInhbRdy 0 "Initial" 1 "Inhibit" 2 "Not_Inhibit" 3 "Invalid" ;
VAL_ 1137 PLGM_OTARdy_Fb 0 "Initial" 1 "Ready" 2 "Not_Ready" 3 "Invalid" ;
VAL_ 1137 PLGM_Tindcn_NTC 110 "Invalid" ;
VAL_ 1140 TBOX_ICC_UpdSched 0 "Initial_Value" 1 "Scheduled_time_reached" ;
VAL_ 1140 TBOX_OTAReq_BMS 0 "No_request" 1 "Request" 3 "Invalid" ;
VAL_ 1140 TBOX_OTAReq_VCU 0 "No_request" 1 "Request" 3 "Invalid" ;
VAL_ 1140 TBOX_OTAReq_ECC 0 "No_request" 1 "Request" 3 "Invalid" ;
VAL_ 1140 TBOX_OTAReq_OBC 0 "No_request" 1 "Request" 3 "Invalid" ;
VAL_ 1140 TBOX_OTAReq_MCU_F 0 "No_request" 1 "Request" 3 "Invalid" ;
VAL_ 1140 TBOX_OTAReq_MCU_R 0 "No_request" 1 "Request" 3 "Invalid" ;
VAL_ 1140 TBOX_OTAReq_ADAS 0 "No_request" 1 "Request" 3 "Invalid" ;
VAL_ 1140 TBOX_OTAReq_FCM 0 "No_request" 1 "Request" 3 "Invalid" ;
VAL_ 1140 TBOX_OTAReq_GW 0 "No_request" 1 "Request" 3 "Invalid" ;
VAL_ 1140 TBOX_OTAReq_EPS 0 "No_request" 1 "Request" 3 "Invalid" ;
VAL_ 1140 TBOX_OTAReq_ESP 0 "No_request" 1 "Request" 3 "Invalid" ;
VAL_ 1140 TBOX_OTAReq_iBooster 0 "No_request" 1 "Request" 3 "Invalid" ;
VAL_ 1140 TBOX_OTAReq_SCM 0 "No_request" 1 "Request" 3 "Invalid" ;
VAL_ 1140 TBOX_OTAReq_ICC 0 "No_request" 1 "Request" 3 "Invalid" ;
VAL_ 1140 TBOX_OTAReq_OHC 0 "No_request" 1 "Request" 3 "Invalid" ;
VAL_ 1140 TBOX_OTAReq_BCM 0 "No_request" 1 "Request" 3 "Invalid" ;
VAL_ 1140 TBOX_OTAReq_CIM 0 "No_request" 1 "Request" 3 "Invalid" ;
VAL_ 1140 TBOX_OTAReq_PKC 0 "No_request" 1 "Request" 3 "Invalid" ;
VAL_ 1140 TBOX_OTAReq_PLGM 0 "No_request" 1 "Request" 3 "Invalid" ;
VAL_ 1140 TBOX_OTAReq_TRM 0 "No_request" 1 "Request" 3 "Invalid" ;
VAL_ 1140 TBOX_OTAReq_DSMC 0 "No_request" 1 "Request" 3 "Invalid" ;
VAL_ 1140 TBOX_OTAReq_PSM 0 "No_request" 1 "Request" 3 "Invalid" ;
VAL_ 1140 TBOX_OTAReq_VSP 0 "No_request" 1 "Request" 3 "Invalid" ;
VAL_ 1140 TBOX_OTAReq_TBOX 0 "No_request" 1 "Request" 3 "Invalid" ;
